VERSION ""

NS_ :

BS_:

BU_:

BO_ 2561081086 AUXIO3: 8 Vector__XXX
 SG_ AuxiliaryIO49 : 6|2@1+ (1,0) [0|3] "" Vector__XXX
 SG_ AuxiliaryIO50 : 4|2@1+ (1,0) [0|3] "" Vector__XXX
 SG_ AuxiliaryIO51 : 2|2@1+ (1,0) [0|3] "" Vector__XXX
 SG_ AuxiliaryIO52 : 0|2@1+ (1,0) [0|3] "" Vector__XXX
 SG_ AuxiliaryIO53 : 14|2@1+ (1,0) [0|3] "" Vector__XXX
 SG_ AuxiliaryIO54 : 12|2@1+ (1,0) [0|3] "" Vector__XXX
 SG_ AuxiliaryIO55 : 10|2@1+ (1,0) [0|3] "" Vector__XXX
 SG_ AuxiliaryIO56 : 8|2@1+ (1,0) [0|3] "" Vector__XXX
 SG_ AuxiliaryIO57 : 22|2@1+ (1,0) [0|3] "" Vector__XXX
 SG_ AuxiliaryIO58 : 20|2@1+ (1,0) [0|3] "" Vector__XXX
 SG_ AuxiliaryIO59 : 18|2@1+ (1,0) [0|3] "" Vector__XXX
 SG_ AuxiliaryIO60 : 16|2@1+ (1,0) [0|3] "" Vector__XXX
 SG_ AuxiliaryIO61 : 30|2@1+ (1,0) [0|3] "" Vector__XXX
 SG_ AuxiliaryIO62 : 28|2@1+ (1,0) [0|3] "" Vector__XXX
 SG_ AuxiliaryIO63 : 26|2@1+ (1,0) [0|3] "" Vector__XXX
 SG_ AuxiliaryIO64 : 24|2@1+ (1,0) [0|3] "" Vector__XXX
 SG_ AuxiliaryIO65 : 38|2@1+ (1,0) [0|3] "" Vector__XXX
 SG_ AuxiliaryIO66 : 36|2@1+ (1,0) [0|3] "" Vector__XXX
 SG_ AuxiliaryIO67 : 34|2@1+ (1,0) [0|3] "" Vector__XXX
 SG_ AuxiliaryIO68 : 32|2@1+ (1,0) [0|3] "" Vector__XXX
 SG_ AuxiliaryIO69 : 46|2@1+ (1,0) [0|3] "" Vector__XXX
 SG_ AuxiliaryIO70 : 44|2@1+ (1,0) [0|3] "" Vector__XXX
 SG_ AuxiliaryIO71 : 42|2@1+ (1,0) [0|3] "" Vector__XXX
 SG_ AuxiliaryIO72 : 40|2@1+ (1,0) [0|3] "" Vector__XXX
 SG_ AuxiliaryIO73 : 54|2@1+ (1,0) [0|3] "" Vector__XXX
 SG_ AuxiliaryIO74 : 52|2@1+ (1,0) [0|3] "" Vector__XXX
 SG_ AuxiliaryIO75 : 50|2@1+ (1,0) [0|3] "" Vector__XXX
 SG_ AuxiliaryIO76 : 48|2@1+ (1,0) [0|3] "" Vector__XXX
 SG_ AuxiliaryIO77 : 62|2@1+ (1,0) [0|3] "" Vector__XXX
 SG_ AuxiliaryIO78 : 60|2@1+ (1,0) [0|3] "" Vector__XXX
 SG_ AuxiliaryIO79 : 58|2@1+ (1,0) [0|3] "" Vector__XXX
 SG_ AuxiliaryIO80 : 56|2@1+ (1,0) [0|3] "" Vector__XXX

BO_ 2561146622 AUXIO2: 8 Vector__XXX
 SG_ AuxiliaryIO17 : 6|2@1+ (1,0) [0|3] "" Vector__XXX
 SG_ AuxiliaryIO18 : 4|2@1+ (1,0) [0|3] "" Vector__XXX
 SG_ AuxiliaryIO19 : 2|2@1+ (1,0) [0|3] "" Vector__XXX
 SG_ AuxiliaryIO20 : 0|2@1+ (1,0) [0|3] "" Vector__XXX
 SG_ AuxiliaryIO21 : 14|2@1+ (1,0) [0|3] "" Vector__XXX
 SG_ AuxiliaryIO22 : 12|2@1+ (1,0) [0|3] "" Vector__XXX
 SG_ AuxiliaryIO23 : 10|2@1+ (1,0) [0|3] "" Vector__XXX
 SG_ AuxiliaryIO24 : 8|2@1+ (1,0) [0|3] "" Vector__XXX
 SG_ AuxiliaryIO25 : 22|2@1+ (1,0) [0|3] "" Vector__XXX
 SG_ AuxiliaryIO26 : 20|2@1+ (1,0) [0|3] "" Vector__XXX
 SG_ AuxiliaryIO27 : 18|2@1+ (1,0) [0|3] "" Vector__XXX
 SG_ AuxiliaryIO28 : 16|2@1+ (1,0) [0|3] "" Vector__XXX
 SG_ AuxiliaryIO29 : 30|2@1+ (1,0) [0|3] "" Vector__XXX
 SG_ AuxiliaryIO30 : 28|2@1+ (1,0) [0|3] "" Vector__XXX
 SG_ AuxiliaryIO31 : 26|2@1+ (1,0) [0|3] "" Vector__XXX
 SG_ AuxiliaryIO32 : 24|2@1+ (1,0) [0|3] "" Vector__XXX
 SG_ AuxiliaryIO33 : 38|2@1+ (1,0) [0|3] "" Vector__XXX
 SG_ AuxiliaryIO34 : 36|2@1+ (1,0) [0|3] "" Vector__XXX
 SG_ AuxiliaryIO35 : 34|2@1+ (1,0) [0|3] "" Vector__XXX
 SG_ AuxiliaryIO36 : 32|2@1+ (1,0) [0|3] "" Vector__XXX
 SG_ AuxiliaryIO37 : 46|2@1+ (1,0) [0|3] "" Vector__XXX
 SG_ AuxiliaryIO38 : 44|2@1+ (1,0) [0|3] "" Vector__XXX
 SG_ AuxiliaryIO39 : 42|2@1+ (1,0) [0|3] "" Vector__XXX
 SG_ AuxiliaryIO40 : 40|2@1+ (1,0) [0|3] "" Vector__XXX
 SG_ AuxiliaryIO41 : 54|2@1+ (1,0) [0|3] "" Vector__XXX
 SG_ AuxiliaryIO42 : 52|2@1+ (1,0) [0|3] "" Vector__XXX
 SG_ AuxiliaryIO43 : 50|2@1+ (1,0) [0|3] "" Vector__XXX
 SG_ AuxiliaryIO44 : 48|2@1+ (1,0) [0|3] "" Vector__XXX
 SG_ AuxiliaryIO45 : 62|2@1+ (1,0) [0|3] "" Vector__XXX
 SG_ AuxiliaryIO46 : 60|2@1+ (1,0) [0|3] "" Vector__XXX
 SG_ AuxiliaryIO47 : 58|2@1+ (1,0) [0|3] "" Vector__XXX
 SG_ AuxiliaryIO48 : 56|2@1+ (1,0) [0|3] "" Vector__XXX

BO_ 2561212158 DISP1: 8 Vector__XXX
 SG_ TextDisplayIndex : 16|8@1+ (1,0) [0|200] "count" Vector__XXX
 SG_ TextDisplayInstructions : 0|4@1+ (1,0) [0|15] "" Vector__XXX

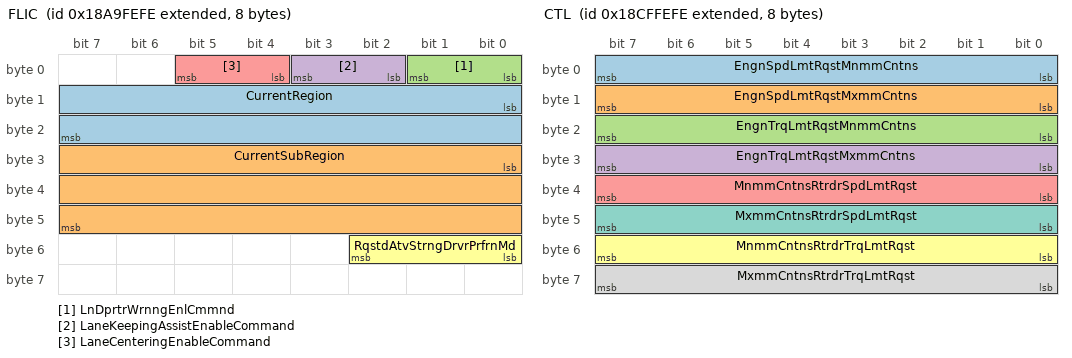
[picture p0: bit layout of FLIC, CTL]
BO_ 2561277694 FLIC: 8 Vector__XXX
 SG_ CurrentRegion : 8|16@1+ (1,0) [0|255] "" Vector__XXX
 SG_ CurrentSubRegion : 24|24@1+ (1,0) [0|255] "" Vector__XXX
 SG_ LnDprtrWrnngEnlCmmnd : 0|2@1+ (1,0) [0|3] "" Vector__XXX
 SG_ LaneKeepingAssistEnableCommand : 2|2@1+ (1,0) [0|3] "" Vector__XXX
 SG_ LaneCenteringEnableCommand : 4|2@1+ (1,0) [0|3] "" Vector__XXX
 SG_ RqstdAtvStrngDrvrPrfrnMd : 48|3@1+ (1,0) [0|7] "" Vector__XXX

BO_ 2561605374 TPRS: 8 Vector__XXX
 SG_ ReferenceTirePressureSetting : 8|8@1+ (8,0) [0|2000] "kPa" Vector__XXX
 SG_ TireLocation : 0|8@1+ (1,0) [0|250] "" Vector__XXX

BO_ 2563768062 CTL: 8 Vector__XXX
 SG_ EngnSpdLmtRqstMnmmCntns : 0|8@1+ (32,0) [0|8000] "rpm" Vector__XXX
 SG_ EngnSpdLmtRqstMxmmCntns : 8|8@1+ (32,0) [0|8000] "rpm" Vector__XXX
 SG_ EngnTrqLmtRqstMnmmCntns : 16|8@1+ (1,-125) [0|125] "%" Vector__XXX
 SG_ EngnTrqLmtRqstMxmmCntns : 24|8@1+ (1,-125) [0|125] "%" Vector__XXX
 SG_ MnmmCntnsRtrdrSpdLmtRqst : 32|8@1+ (32,0) [0|8000] "rpm" Vector__XXX
 SG_ MnmmCntnsRtrdrTrqLmtRqst : 48|8@1+ (1,-125) [-125|0] "%" Vector__XXX
 SG_ MxmmCntnsRtrdrSpdLmtRqst : 40|8@1+ (32,0) [0|8000] "rpm" Vector__XXX
 SG_ MxmmCntnsRtrdrTrqLmtRqst : 56|8@1+ (1,-125) [-125|0] "%" Vector__XXX

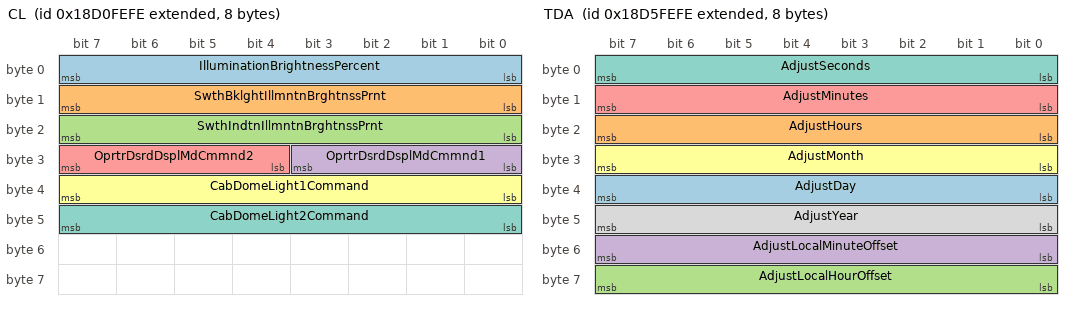
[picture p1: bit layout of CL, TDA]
BO_ 2563833598 CL: 8 Vector__XXX
 SG_ IlluminationBrightnessPercent : 0|8@1+ (0.4,0) [0|100] "%" Vector__XXX
 SG_ SwthBklghtIllmntnBrghtnssPrnt : 8|8@1+ (0.4,0) [0|100] "%" Vector__XXX
 SG_ SwthIndtnIllmntnBrghtnssPrnt : 16|8@1+ (0.4,0) [0|100] "%" Vector__XXX
 SG_ OprtrDsrdDsplMdCmmnd1 : 24|4@1+ (1,0) [0|15] "" Vector__XXX
 SG_ OprtrDsrdDsplMdCmmnd2 : 28|4@1+ (1,0) [0|15] "" Vector__XXX
 SG_ CabDomeLight1Command : 32|8@1+ (0.4,0) [0|100] "%" Vector__XXX
 SG_ CabDomeLight2Command : 40|8@1+ (0.4,0) [0|100] "%" Vector__XXX

BO_ 2564161278 TDA: 8 Vector__XXX
 SG_ AdjustDay : 32|8@1+ (0.25,0) [0.25|31.75] "days" Vector__XXX
 SG_ AdjustHours : 16|8@1+ (1,0) [0|23] "h" Vector__XXX
 SG_ AdjustLocalHourOffset : 56|8@1+ (1,-125) [-24|23] "h" Vector__XXX
 SG_ AdjustLocalMinuteOffset : 48|8@1+ (1,-125) [-59|59] "min" Vector__XXX
 SG_ AdjustMinutes : 8|8@1+ (1,0) [0|59] "min" Vector__XXX
 SG_ AdjustMonth : 24|8@1+ (1,0) [1|12] "month" Vector__XXX
 SG_ AdjustSeconds : 0|8@1+ (0.25,0) [0|59.75] "s" Vector__XXX
 SG_ AdjustYear : 40|8@1+ (1,1985) [1985|2235] "year" Vector__XXX

BO_ 2564882174 CM1: 8 Vector__XXX
 SG_ AftrtrtmntRgnrtnFrSwth : 42|2@1+ (1,0) [0|3] "" Vector__XXX
 SG_ AftrtrtmntRgnrtnInhtSwth : 40|2@1+ (1,0) [0|3] "" Vector__XXX
 SG_ AtmtGrShftngEnlSwth : 44|2@1+ (1,0) [0|3] "" Vector__XXX
 SG_ AuxiliaryHeaterModeRequest : 48|4@1+ (1,0) [0|15] "" Vector__XXX
 SG_ AxlrHtrClntPmpRqst : 24|2@1+ (1,0) [0|3] "" Vector__XXX
 SG_ BatteryMainSwitchHoldRequest : 26|2@1+ (1,0) [0|3] "" Vector__XXX
 SG_ CabInteriorTemperatureCommand : 8|16@1+ (0.03125,-273) [-273|1734.96875] "degC" Vector__XXX
 SG_ EngineFan1RequestedPercentSpeed : 0|8@1+ (0.4,0) [0|100] "%" Vector__XXX
 SG_ EngnAtmtStrtEnlSwth : 46|2@1+ (1,0) [0|3] "" Vector__XXX
 SG_ OperatorSeatDirectionSwitch : 28|2@1+ (1,0) [0|3] "" Vector__XXX
 SG_ ParkBrakeCommand : 32|2@1+ (1,0) [0|3] "" Vector__XXX
 SG_ RequestCabZoneHeating : 54|2@1+ (1,0) [0|3] "" Vector__XXX
 SG_ RequestEngineZoneHeating : 52|2@1+ (1,0) [0|3] "" Vector__XXX
 SG_ SeatBeltSwitch : 30|2@1+ (1,0) [0|3] "" Vector__XXX
 SG_ SltdMxmmVhlSpdLmt : 56|8@1+ (1,0) [0|250] "count" Vector__XXX
 SG_ VhlLmtngSpdGvrnrDrmntSwth : 34|2@1+ (1,0) [0|3] "" Vector__XXX
 SG_ VhlLmtngSpdGvrnrEnlSwth : 38|2@1+ (1,0) [0|3] "" Vector__XXX
 SG_ VhlLmtngSpdGvrnrInrmntSwth : 36|2@1+ (1,0) [0|3] "" Vector__XXX

BO_ 2565865982 EBC1: 8 Vector__XXX
 SG_ AbsFullyOperational : 40|2@1+ (1,0) [0|3] "" Vector__XXX
 SG_ AbsOffRoadSwitch : 16|2@1+ (1,0) [0|3] "" Vector__XXX
 SG_ AcceleratorInterlockSwitch : 24|2@1+ (1,0) [0|3] "" Vector__XXX
 SG_ AntiLockBrakingAbsActive : 4|2@1+ (1,0) [0|3] "" Vector__XXX
 SG_ AsrBrakeControlActive : 2|2@1+ (1,0) [0|3] "" Vector__XXX
 SG_ AsrEngineControlActive : 0|2@1+ (1,0) [0|3] "" Vector__XXX
 SG_ AsrHillHolderSwitch : 20|2@1+ (1,0) [0|3] "" Vector__XXX
 SG_ AsrOffRoadSwitch : 18|2@1+ (1,0) [0|3] "" Vector__XXX
 SG_ AtcAsrInformationSignal : 46|2@1+ (1,0) [0|3] "" Vector__XXX
 SG_ BrakePedalPosition : 8|8@1+ (0.4,0) [0|100] "%" Vector__XXX
 SG_ EbsBrakeSwitch : 6|2@1+ (1,0) [0|3] "" Vector__XXX
 SG_ EbsRedWarningSignal : 42|2@1+ (1,0) [0|3] "" Vector__XXX
 SG_ EngineAuxiliaryShutdownSwitch : 28|2@1+ (1,0) [0|3] "" Vector__XXX
 SG_ EngineDerateSwitch : 26|2@1+ (1,0) [0|3] "" Vector__XXX
 SG_ EngineRetarderSelection : 32|8@1+ (0.4,0) [0|100] "%" Vector__XXX
 SG_ HaltBrakeSwitch : 58|2@1+ (1,0) [0|3] "" Vector__XXX
 SG_ RailroadModeSwitch : 56|2@1+ (1,0) [0|3] "" Vector__XXX
 SG_ RemoteAcceleratorEnableSwitch : 30|2@1+ (1,0) [0|3] "" Vector__XXX
 SG_ TractionControlOverrideSwitch : 22|2@1+ (1,0) [0|3] "" Vector__XXX
 SG_ TrailerAbsStatus : 60|2@1+ (1,0) [0|3] "" Vector__XXX
 SG_ AsEsAmrWrnngSgnlPwrdVhl : 44|2@1+ (1,0) [0|3] "" Vector__XXX
 SG_ SrAddrssOfCntrllngDvFrBrkCntrl : 48|8@1+ (1,0) [0|253] "sourceadr" Vector__XXX
 SG_ TrtrMntdTrlrAsWrnngSgnl : 62|2@1+ (1,0) [0|3] "" Vector__XXX

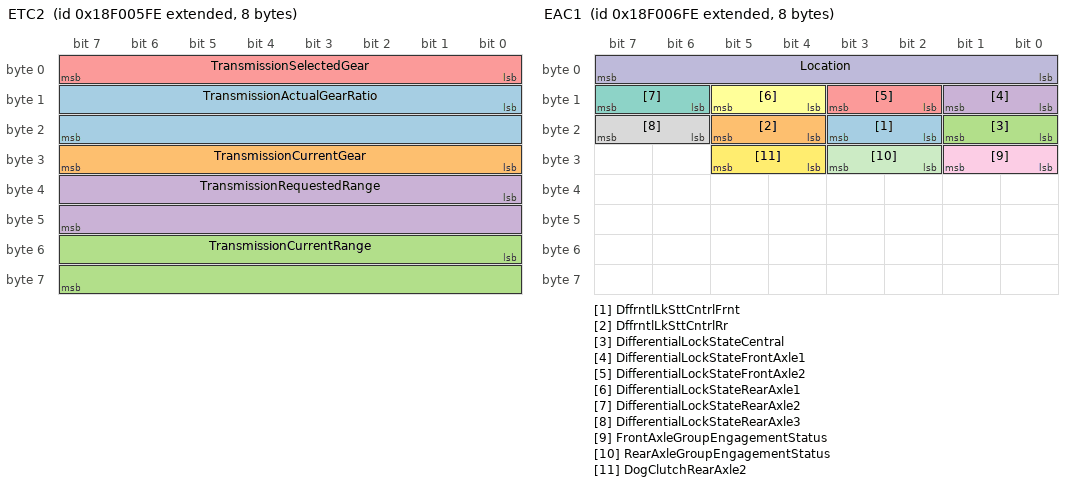
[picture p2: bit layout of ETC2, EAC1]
BO_ 2565867006 ETC2: 8 Vector__XXX
 SG_ TransmissionActualGearRatio : 8|16@1+ (0.001,0) [0|64.255] "" Vector__XXX
 SG_ TransmissionCurrentGear : 24|8@1+ (1,-125) [-125|125] "gear value" Vector__XXX
 SG_ TransmissionCurrentRange : 48|16@1+ (1,0) [0|255] "" Vector__XXX
 SG_ TransmissionRequestedRange : 32|16@1+ (1,0) [0|255] "" Vector__XXX
 SG_ TransmissionSelectedGear : 0|8@1+ (1,-125) [-125|125] "gear value" Vector__XXX

BO_ 2565867262 EAC1: 8 Vector__XXX
 SG_ DffrntlLkSttCntrlFrnt : 18|2@1+ (1,0) [0|3] "" Vector__XXX
 SG_ DffrntlLkSttCntrlRr : 20|2@1+ (1,0) [0|3] "" Vector__XXX
 SG_ DifferentialLockStateCentral : 16|2@1+ (1,0) [0|3] "" Vector__XXX
 SG_ DifferentialLockStateFrontAxle1 : 8|2@1+ (1,0) [0|3] "" Vector__XXX
 SG_ DifferentialLockStateFrontAxle2 : 10|2@1+ (1,0) [0|3] "" Vector__XXX
 SG_ DifferentialLockStateRearAxle1 : 12|2@1+ (1,0) [0|3] "" Vector__XXX
 SG_ DifferentialLockStateRearAxle2 : 14|2@1+ (1,0) [0|3] "" Vector__XXX
 SG_ DifferentialLockStateRearAxle3 : 22|2@1+ (1,0) [0|3] "" Vector__XXX
 SG_ FrontAxleGroupEngagementStatus : 24|2@1+ (1,0) [0|3] "" Vector__XXX
 SG_ Location : 0|8@1+ (1,0) [0|250] "" Vector__XXX
 SG_ RearAxleGroupEngagementStatus : 26|2@1+ (1,0) [0|3] "" Vector__XXX
 SG_ DogClutchRearAxle2 : 28|2@1+ (1,0) [0|3] "" Vector__XXX

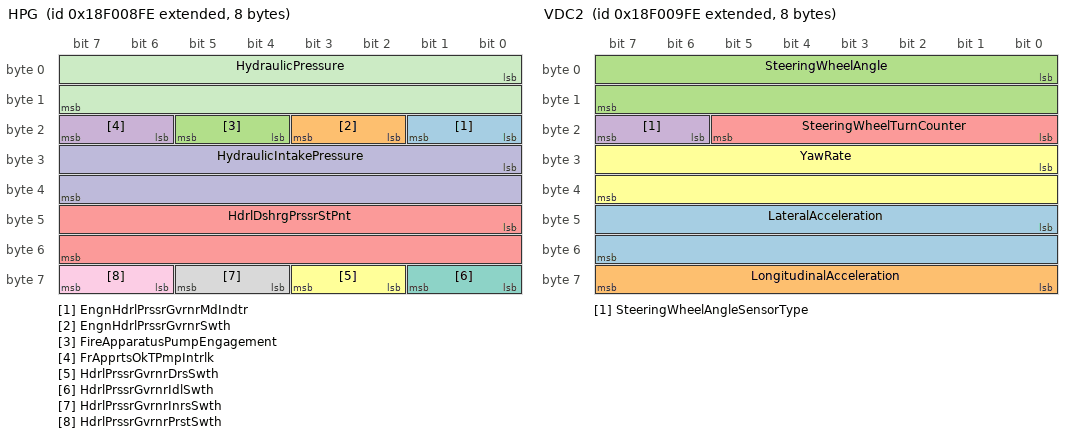
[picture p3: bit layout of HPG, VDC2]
BO_ 2565867774 HPG: 8 Vector__XXX
 SG_ EngnHdrlPrssrGvrnrMdIndtr : 16|2@1+ (1,0) [0|3] "" Vector__XXX
 SG_ EngnHdrlPrssrGvrnrSwth : 18|2@1+ (1,0) [0|3] "" Vector__XXX
 SG_ FireApparatusPumpEngagement : 20|2@1+ (1,0) [0|3] "" Vector__XXX
 SG_ FrApprtsOkTPmpIntrlk : 22|2@1+ (1,0) [0|3] "" Vector__XXX
 SG_ HdrlDshrgPrssrStPnt : 40|16@1+ (2,0) [0|128510] "kPa" Vector__XXX
 SG_ HdrlPrssrGvrnrDrsSwth : 58|2@1+ (1,0) [0|3] "" Vector__XXX
 SG_ HdrlPrssrGvrnrIdlSwth : 56|2@1+ (1,0) [0|3] "" Vector__XXX
 SG_ HdrlPrssrGvrnrInrsSwth : 60|2@1+ (1,0) [0|3] "" Vector__XXX
 SG_ HdrlPrssrGvrnrPrstSwth : 62|2@1+ (1,0) [0|3] "" Vector__XXX
 SG_ HydraulicIntakePressure : 24|16@1+ (0.0001220703125,-1) [-1|6.8436279296875] "MPa" Vector__XXX
 SG_ HydraulicPressure : 0|16@1+ (2,0) [0|128510] "kPa" Vector__XXX

BO_ 2565868030 VDC2: 8 Vector__XXX
 SG_ LateralAcceleration : 40|16@1+ (0.00048828125,-15.687) [-15.687|15.68751171875] "m/(s*s)" Vector__XXX
 SG_ LongitudinalAcceleration : 56|8@1+ (0.1,-12.5) [-12.5|12.5] "m/(s*s)" Vector__XXX
 SG_ SteeringWheelAngle : 0|16@1+ (0.0009765625,-31.374) [-31.374|31.3750234375] "rad" Vector__XXX
 SG_ SteeringWheelAngleSensorType : 22|2@1+ (1,0) [0|3] "" Vector__XXX
 SG_ SteeringWheelTurnCounter : 16|6@1+ (1,-32) [-10|10] "turn" Vector__XXX
 SG_ YawRate : 24|16@1+ (0.0001220703125,-3.92) [-3.92|3.9236279296875] "rad/s" Vector__XXX

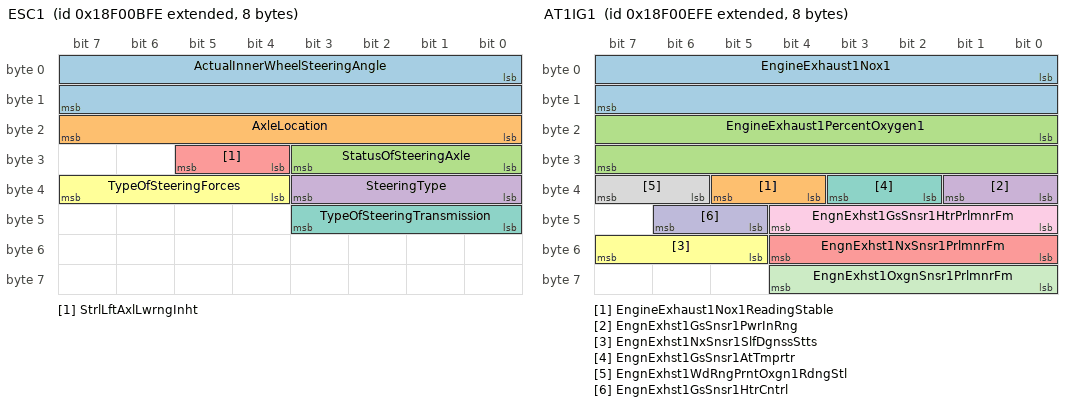
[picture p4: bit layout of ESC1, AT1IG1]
BO_ 2565868542 ESC1: 8 Vector__XXX
 SG_ ActualInnerWheelSteeringAngle : 0|16@1+ (0.00390625,-125) [-125|125.99609375] "deg" Vector__XXX
 SG_ AxleLocation : 16|8@1+ (1,0) [0|250] "" Vector__XXX
 SG_ StatusOfSteeringAxle : 24|4@1+ (1,0) [0|15] "" Vector__XXX
 SG_ SteeringType : 32|4@1+ (1,0) [0|15] "" Vector__XXX
 SG_ StrlLftAxlLwrngInht : 28|2@1+ (1,0) [0|3] "" Vector__XXX
 SG_ TypeOfSteeringForces : 36|4@1+ (1,0) [0|15] "" Vector__XXX
 SG_ TypeOfSteeringTransmission : 40|4@1+ (1,0) [0|15] "" Vector__XXX

BO_ 2565869310 AT1IG1: 8 Vector__XXX
 SG_ EngineExhaust1Nox1 : 0|16@1+ (0.05,-200) [-200|3012.75] "ppm" Vector__XXX
 SG_ EngineExhaust1Nox1ReadingStable : 36|2@1+ (1,0) [0|3] "" Vector__XXX
 SG_ EngineExhaust1PercentOxygen1 : 16|16@1+ (0.000514,-12) [-12|21.02707] "%" Vector__XXX
 SG_ EngnExhst1GsSnsr1PwrInRng : 32|2@1+ (1,0) [0|3] "" Vector__XXX
 SG_ EngnExhst1NxSnsr1PrlmnrFm : 48|5@1+ (1,0) [0|31] "" Vector__XXX
 SG_ EngnExhst1NxSnsr1SlfDgnssStts : 53|3@1+ (1,0) [0|7] "" Vector__XXX
 SG_ EngnExhst1GsSnsr1AtTmprtr : 34|2@1+ (1,0) [0|3] "" Vector__XXX
 SG_ EngnExhst1WdRngPrntOxgn1RdngStl : 38|2@1+ (1,0) [0|3] "" Vector__XXX
 SG_ EngnExhst1GsSnsr1HtrPrlmnrFm : 40|5@1+ (1,0) [0|31] "" Vector__XXX
 SG_ EngnExhst1GsSnsr1HtrCntrl : 45|2@1+ (1,0) [0|3] "" Vector__XXX
 SG_ EngnExhst1OxgnSnsr1PrlmnrFm : 56|5@1+ (1,0) [0|31] "" Vector__XXX

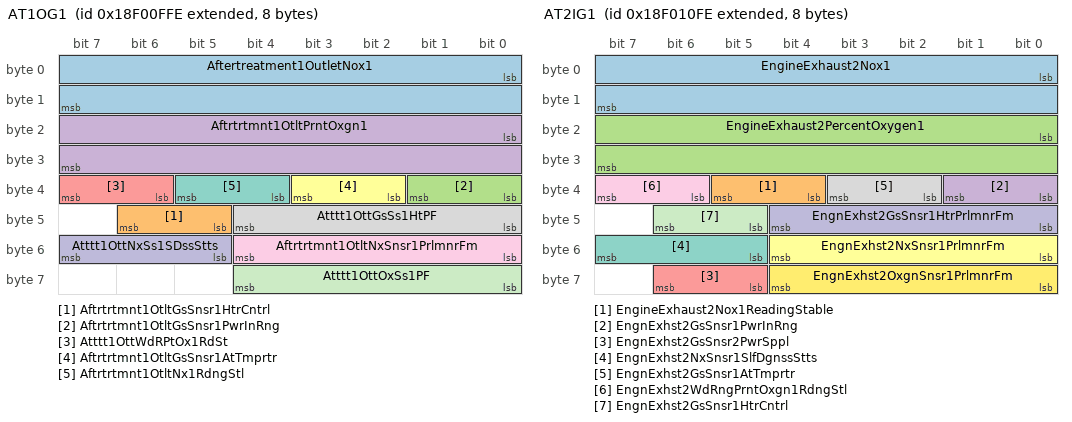
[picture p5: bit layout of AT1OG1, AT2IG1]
BO_ 2565869566 AT1OG1: 8 Vector__XXX
 SG_ Aftertreatment1OutletNox1 : 0|16@1+ (0.05,-200) [-200|3012.75] "ppm" Vector__XXX
 SG_ Aftrtrtmnt1OtltGsSnsr1HtrCntrl : 45|2@1+ (1,0) [0|3] "" Vector__XXX
 SG_ Aftrtrtmnt1OtltGsSnsr1PwrInRng : 32|2@1+ (1,0) [0|3] "" Vector__XXX
 SG_ Aftrtrtmnt1OtltPrntOxgn1 : 16|16@1+ (0.000514,-12) [-12|21.02707] "%" Vector__XXX
 SG_ Atttt1OttWdRPtOx1RdSt : 38|2@1+ (1,0) [0|3] "" Vector__XXX
 SG_ Aftrtrtmnt1OtltGsSnsr1AtTmprtr : 34|2@1+ (1,0) [0|3] "" Vector__XXX
 SG_ Aftrtrtmnt1OtltNx1RdngStl : 36|2@1+ (1,0) [0|3] "" Vector__XXX
 SG_ Atttt1OttGsSs1HtPF : 40|5@1+ (1,0) [0|31] "" Vector__XXX
 SG_ Aftrtrtmnt1OtltNxSnsr1PrlmnrFm : 48|5@1+ (1,0) [0|31] "" Vector__XXX
 SG_ Atttt1OttNxSs1SDssStts : 53|3@1+ (1,0) [0|7] "" Vector__XXX
 SG_ Atttt1OttOxSs1PF : 56|5@1+ (1,0) [0|31] "" Vector__XXX

BO_ 2565869822 AT2IG1: 8 Vector__XXX
 SG_ EngineExhaust2Nox1 : 0|16@1+ (0.05,-200) [-200|3012.75] "ppm" Vector__XXX
 SG_ EngineExhaust2Nox1ReadingStable : 36|2@1+ (1,0) [0|3] "" Vector__XXX
 SG_ EngineExhaust2PercentOxygen1 : 16|16@1+ (0.000514,-12) [-12|21.02707] "%" Vector__XXX
 SG_ EngnExhst2GsSnsr1PwrInRng : 32|2@1+ (1,0) [0|3] "" Vector__XXX
 SG_ EngnExhst2GsSnsr2PwrSppl : 61|2@1+ (1,0) [0|3] "" Vector__XXX
 SG_ EngnExhst2NxSnsr1PrlmnrFm : 48|5@1+ (1,0) [0|31] "" Vector__XXX
 SG_ EngnExhst2NxSnsr1SlfDgnssStts : 53|3@1+ (1,0) [0|7] "" Vector__XXX
 SG_ EngnExhst2GsSnsr1AtTmprtr : 34|2@1+ (1,0) [0|3] "" Vector__XXX
 SG_ EngnExhst2WdRngPrntOxgn1RdngStl : 38|2@1+ (1,0) [0|3] "" Vector__XXX
 SG_ EngnExhst2GsSnsr1HtrPrlmnrFm : 40|5@1+ (1,0) [0|31] "" Vector__XXX
 SG_ EngnExhst2GsSnsr1HtrCntrl : 45|2@1+ (1,0) [0|3] "" Vector__XXX
 SG_ EngnExhst2OxgnSnsr1PrlmnrFm : 56|5@1+ (1,0) [0|31] "" Vector__XXX

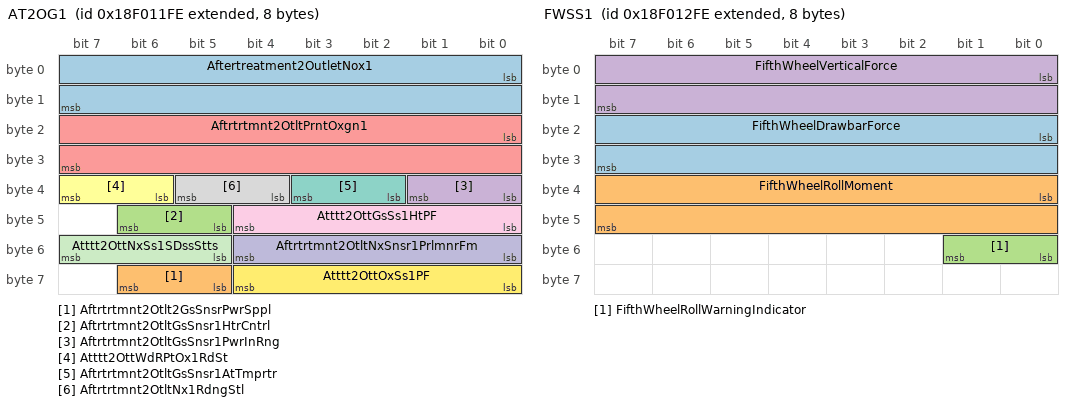
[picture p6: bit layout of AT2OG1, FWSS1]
BO_ 2565870078 AT2OG1: 8 Vector__XXX
 SG_ Aftertreatment2OutletNox1 : 0|16@1+ (0.05,-200) [-200|3012.75] "ppm" Vector__XXX
 SG_ Aftrtrtmnt2Otlt2GsSnsrPwrSppl : 61|2@1+ (1,0) [0|3] "" Vector__XXX
 SG_ Aftrtrtmnt2OtltGsSnsr1HtrCntrl : 45|2@1+ (1,0) [0|3] "" Vector__XXX
 SG_ Aftrtrtmnt2OtltGsSnsr1PwrInRng : 32|2@1+ (1,0) [0|3] "" Vector__XXX
 SG_ Aftrtrtmnt2OtltPrntOxgn1 : 16|16@1+ (0.000514,-12) [-12|21.02707] "%" Vector__XXX
 SG_ Atttt2OttWdRPtOx1RdSt : 38|2@1+ (1,0) [0|3] "" Vector__XXX
 SG_ Aftrtrtmnt2OtltGsSnsr1AtTmprtr : 34|2@1+ (1,0) [0|3] "" Vector__XXX
 SG_ Aftrtrtmnt2OtltNx1RdngStl : 36|2@1+ (1,0) [0|3] "" Vector__XXX
 SG_ Atttt2OttGsSs1HtPF : 40|5@1+ (1,0) [0|31] "" Vector__XXX
 SG_ Aftrtrtmnt2OtltNxSnsr1PrlmnrFm : 48|5@1+ (1,0) [0|31] "" Vector__XXX
 SG_ Atttt2OttNxSs1SDssStts : 53|3@1+ (1,0) [0|7] "" Vector__XXX
 SG_ Atttt2OttOxSs1PF : 56|5@1+ (1,0) [0|31] "" Vector__XXX

BO_ 2565870334 FWSS1: 8 Vector__XXX
 SG_ FifthWheelDrawbarForce : 16|16@1+ (10,-320000) [-320000|322550] "N" Vector__XXX
 SG_ FifthWheelRollMoment : 32|16@1+ (10,-320000) [-320000|322550] "N" Vector__XXX
 SG_ FifthWheelRollWarningIndicator : 48|2@1+ (1,0) [0|3] "" Vector__XXX
 SG_ FifthWheelVerticalForce : 0|16@1+ (5,0) [0|321275] "N" Vector__XXX

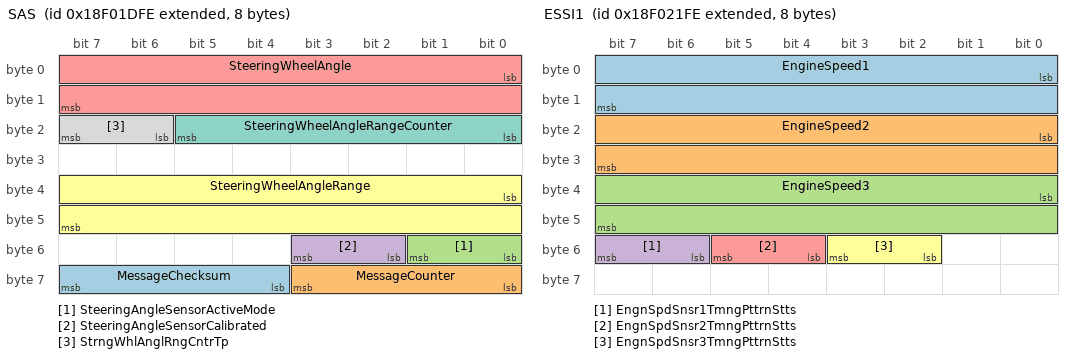
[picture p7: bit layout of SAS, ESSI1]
BO_ 2565873150 SAS: 8 Vector__XXX
 SG_ MessageChecksum : 60|4@1+ (1,0) [0|15] "count" Vector__XXX
 SG_ MessageCounter : 56|4@1+ (1,0) [0|15] "count" Vector__XXX
 SG_ SteeringAngleSensorActiveMode : 48|2@1+ (1,0) [0|3] "" Vector__XXX
 SG_ SteeringAngleSensorCalibrated : 50|2@1+ (1,0) [0|3] "" Vector__XXX
 SG_ SteeringWheelAngle : 0|16@1+ (0.0009765625,-31.374) [-31.374|31.3750234375] "rad" Vector__XXX
 SG_ SteeringWheelAngleRange : 32|16@1+ (0.0009765625,-31.374) [0|31.374] "rad" Vector__XXX
 SG_ SteeringWheelAngleRangeCounter : 16|6@1+ (1,-32) [-32|29] "range" Vector__XXX
 SG_ StrngWhlAnglRngCntrTp : 22|2@1+ (1,0) [0|3] "" Vector__XXX

BO_ 2565874174 ESSI1: 8 Vector__XXX
 SG_ EngineSpeed1 : 0|16@1+ (0.5,0) [0|32127.5] "rpm" Vector__XXX
 SG_ EngineSpeed2 : 16|16@1+ (0.5,0) [0|32127.5] "rpm" Vector__XXX
 SG_ EngineSpeed3 : 32|16@1+ (0.5,0) [0|32127.5] "rpm" Vector__XXX
 SG_ EngnSpdSnsr1TmngPttrnStts : 54|2@1+ (1,0) [0|3] "" Vector__XXX
 SG_ EngnSpdSnsr2TmngPttrnStts : 52|2@1+ (1,0) [0|3] "" Vector__XXX
 SG_ EngnSpdSnsr3TmngPttrnStts : 50|2@1+ (1,0) [0|3] "" Vector__XXX

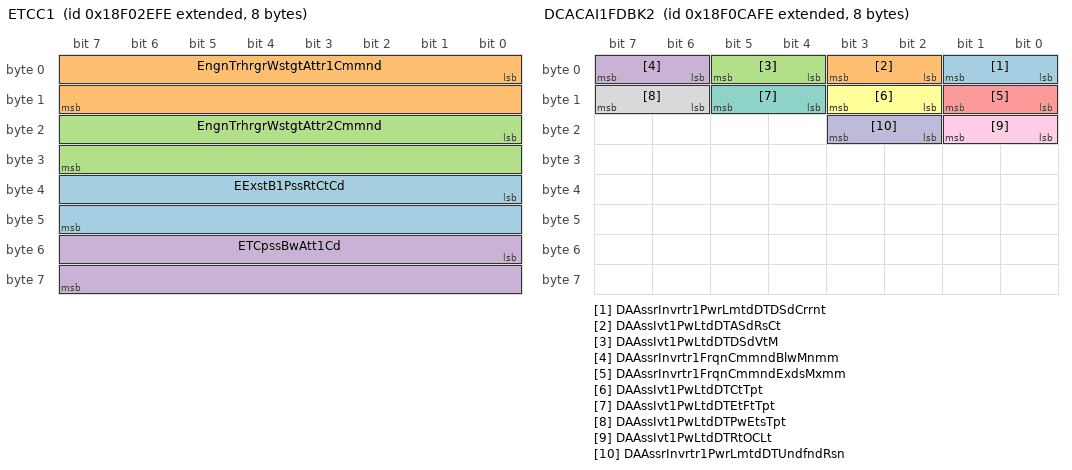
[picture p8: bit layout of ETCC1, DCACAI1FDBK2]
BO_ 2565877502 ETCC1: 8 Vector__XXX
 SG_ EExstB1PssRtCtCd : 32|16@1+ (0.0025,0) [0|100] "%" Vector__XXX
 SG_ EngnTrhrgrWstgtAttr1Cmmnd : 0|16@1+ (0.0025,0) [0|160.6375] "%" Vector__XXX
 SG_ EngnTrhrgrWstgtAttr2Cmmnd : 16|16@1+ (0.0025,0) [0|160.6375] "%" Vector__XXX
 SG_ ETCpssBwAtt1Cd : 48|16@1+ (0.0025,0) [0|100] "%" Vector__XXX

BO_ 2565917438 DCACAI1FDBK2: 8 Vector__XXX
 SG_ DAAssrInvrtr1PwrLmtdDTDSdCrrnt : 0|2@1+ (1,0) [0|3] "" Vector__XXX
 SG_ DAAssIvt1PwLtdDTASdRsCt : 2|2@1+ (1,0) [0|3] "" Vector__XXX
 SG_ DAAssIvt1PwLtdDTDSdVtM : 4|2@1+ (1,0) [0|3] "" Vector__XXX
 SG_ DAAssrInvrtr1FrqnCmmndBlwMnmm : 6|2@1+ (1,0) [0|3] "" Vector__XXX
 SG_ DAAssrInvrtr1FrqnCmmndExdsMxmm : 8|2@1+ (1,0) [0|3] "" Vector__XXX
 SG_ DAAssIvt1PwLtdDTCtTpt : 10|2@1+ (1,0) [0|3] "" Vector__XXX
 SG_ DAAssIvt1PwLtdDTEtFtTpt : 12|2@1+ (1,0) [0|3] "" Vector__XXX
 SG_ DAAssIvt1PwLtdDTPwEtsTpt : 14|2@1+ (1,0) [0|3] "" Vector__XXX
 SG_ DAAssIvt1PwLtdDTRtOCLt : 16|2@1+ (1,0) [0|3] "" Vector__XXX
 SG_ DAAssrInvrtr1PwrLmtdDTUndfndRsn : 18|2@1+ (1,0) [0|3] "" Vector__XXX

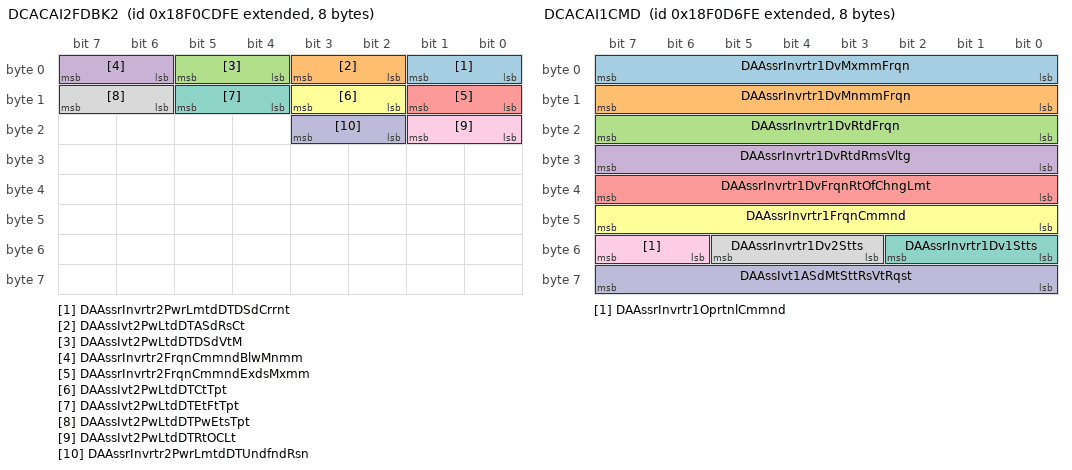
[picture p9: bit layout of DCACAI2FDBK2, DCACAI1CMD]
BO_ 2565918206 DCACAI2FDBK2: 8 Vector__XXX
 SG_ DAAssrInvrtr2PwrLmtdDTDSdCrrnt : 0|2@1+ (1,0) [0|3] "" Vector__XXX
 SG_ DAAssIvt2PwLtdDTASdRsCt : 2|2@1+ (1,0) [0|3] "" Vector__XXX
 SG_ DAAssIvt2PwLtdDTDSdVtM : 4|2@1+ (1,0) [0|3] "" Vector__XXX
 SG_ DAAssrInvrtr2FrqnCmmndBlwMnmm : 6|2@1+ (1,0) [0|3] "" Vector__XXX
 SG_ DAAssrInvrtr2FrqnCmmndExdsMxmm : 8|2@1+ (1,0) [0|3] "" Vector__XXX
 SG_ DAAssIvt2PwLtdDTCtTpt : 10|2@1+ (1,0) [0|3] "" Vector__XXX
 SG_ DAAssIvt2PwLtdDTEtFtTpt : 12|2@1+ (1,0) [0|3] "" Vector__XXX
 SG_ DAAssIvt2PwLtdDTPwEtsTpt : 14|2@1+ (1,0) [0|3] "" Vector__XXX
 SG_ DAAssIvt2PwLtdDTRtOCLt : 16|2@1+ (1,0) [0|3] "" Vector__XXX
 SG_ DAAssrInvrtr2PwrLmtdDTUndfndRsn : 18|2@1+ (1,0) [0|3] "" Vector__XXX

BO_ 2565920510 DCACAI1CMD: 8 Vector__XXX
 SG_ DAAssrInvrtr1DvMxmmFrqn : 0|8@1+ (1,0) [0|250] "Hz" Vector__XXX
 SG_ DAAssrInvrtr1DvMnmmFrqn : 8|8@1+ (1,0) [0|250] "Hz" Vector__XXX
 SG_ DAAssrInvrtr1DvRtdFrqn : 16|8@1+ (1,0) [0|250] "Hz" Vector__XXX
 SG_ DAAssrInvrtr1DvRtdRmsVltg : 24|8@1+ (2,0) [0|500] "V" Vector__XXX
 SG_ DAAssrInvrtr1DvFrqnRtOfChngLmt : 32|8@1+ (2,0) [0|500] "Hz/s" Vector__XXX
 SG_ DAAssrInvrtr1FrqnCmmnd : 40|8@1+ (1,0) [0|250] "Hz" Vector__XXX
 SG_ DAAssrInvrtr1Dv1Stts : 48|3@1+ (1,0) [0|7] "" Vector__XXX
 SG_ DAAssrInvrtr1Dv2Stts : 51|3@1+ (1,0) [0|7] "" Vector__XXX
 SG_ DAAssrInvrtr1OprtnlCmmnd : 54|2@1+ (1,0) [0|3] "" Vector__XXX
 SG_ DAAssIvt1ASdMtSttRsVtRqst : 56|8@1+ (2,0) [0|500] "V" Vector__XXX

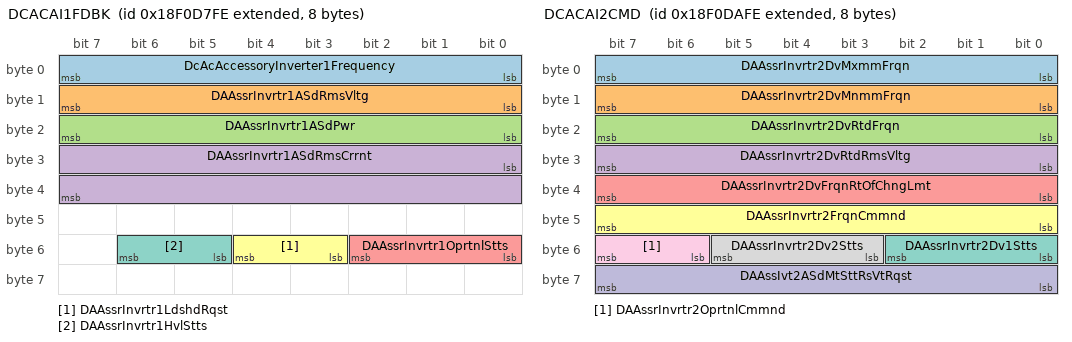
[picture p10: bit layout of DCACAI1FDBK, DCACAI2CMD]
BO_ 2565920766 DCACAI1FDBK: 8 Vector__XXX
 SG_ DcAcAccessoryInverter1Frequency : 0|8@1+ (1,0) [0|250] "Hz" Vector__XXX
 SG_ DAAssrInvrtr1ASdRmsVltg : 8|8@1+ (2,0) [0|500] "V" Vector__XXX
 SG_ DAAssrInvrtr1ASdPwr : 16|8@1+ (0.1,0) [0|25] "kW" Vector__XXX
 SG_ DAAssrInvrtr1ASdRmsCrrnt : 24|16@1+ (0.03125,0) [0|2007.96875] "A" Vector__XXX
 SG_ DAAssrInvrtr1OprtnlStts : 48|3@1+ (1,0) [0|7] "" Vector__XXX
 SG_ DAAssrInvrtr1LdshdRqst : 51|2@1+ (1,0) [0|3] "" Vector__XXX
 SG_ DAAssrInvrtr1HvlStts : 53|2@1+ (1,0) [0|3] "" Vector__XXX

BO_ 2565921534 DCACAI2CMD: 8 Vector__XXX
 SG_ DAAssrInvrtr2DvMxmmFrqn : 0|8@1+ (1,0) [0|250] "Hz" Vector__XXX
 SG_ DAAssrInvrtr2DvMnmmFrqn : 8|8@1+ (1,0) [0|250] "Hz" Vector__XXX
 SG_ DAAssrInvrtr2DvRtdFrqn : 16|8@1+ (1,0) [0|250] "Hz" Vector__XXX
 SG_ DAAssrInvrtr2DvRtdRmsVltg : 24|8@1+ (2,0) [0|500] "V" Vector__XXX
 SG_ DAAssrInvrtr2DvFrqnRtOfChngLmt : 32|8@1+ (2,0) [0|500] "Hz/s" Vector__XXX
 SG_ DAAssrInvrtr2FrqnCmmnd : 40|8@1+ (1,0) [0|250] "Hz" Vector__XXX
 SG_ DAAssrInvrtr2Dv1Stts : 48|3@1+ (1,0) [0|7] "" Vector__XXX
 SG_ DAAssrInvrtr2Dv2Stts : 51|3@1+ (1,0) [0|7] "" Vector__XXX
 SG_ DAAssrInvrtr2OprtnlCmmnd : 54|2@1+ (1,0) [0|3] "" Vector__XXX
 SG_ DAAssIvt2ASdMtSttRsVtRqst : 56|8@1+ (2,0) [0|500] "V" Vector__XXX

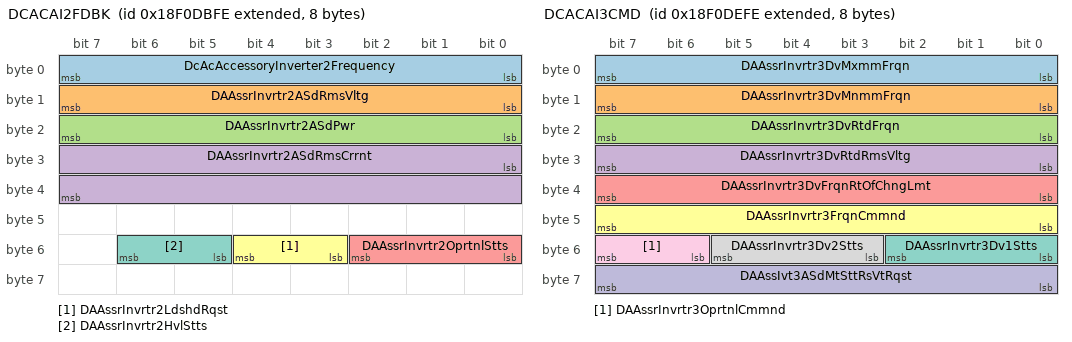
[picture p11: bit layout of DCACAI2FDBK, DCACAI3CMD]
BO_ 2565921790 DCACAI2FDBK: 8 Vector__XXX
 SG_ DcAcAccessoryInverter2Frequency : 0|8@1+ (1,0) [0|250] "Hz" Vector__XXX
 SG_ DAAssrInvrtr2ASdRmsVltg : 8|8@1+ (2,0) [0|500] "V" Vector__XXX
 SG_ DAAssrInvrtr2ASdPwr : 16|8@1+ (0.1,0) [0|25] "kW" Vector__XXX
 SG_ DAAssrInvrtr2ASdRmsCrrnt : 24|16@1+ (0.03125,0) [0|2007.96875] "A" Vector__XXX
 SG_ DAAssrInvrtr2OprtnlStts : 48|3@1+ (1,0) [0|7] "" Vector__XXX
 SG_ DAAssrInvrtr2LdshdRqst : 51|2@1+ (1,0) [0|3] "" Vector__XXX
 SG_ DAAssrInvrtr2HvlStts : 53|2@1+ (1,0) [0|3] "" Vector__XXX

BO_ 2565922558 DCACAI3CMD: 8 Vector__XXX
 SG_ DAAssrInvrtr3DvMxmmFrqn : 0|8@1+ (1,0) [0|250] "Hz" Vector__XXX
 SG_ DAAssrInvrtr3DvMnmmFrqn : 8|8@1+ (1,0) [0|250] "Hz" Vector__XXX
 SG_ DAAssrInvrtr3DvRtdFrqn : 16|8@1+ (1,0) [0|250] "Hz" Vector__XXX
 SG_ DAAssrInvrtr3DvRtdRmsVltg : 24|8@1+ (2,0) [0|500] "V" Vector__XXX
 SG_ DAAssrInvrtr3DvFrqnRtOfChngLmt : 32|8@1+ (2,0) [0|500] "Hz/s" Vector__XXX
 SG_ DAAssrInvrtr3FrqnCmmnd : 40|8@1+ (1,0) [0|250] "Hz" Vector__XXX
 SG_ DAAssrInvrtr3Dv1Stts : 48|3@1+ (1,0) [0|7] "" Vector__XXX
 SG_ DAAssrInvrtr3Dv2Stts : 51|3@1+ (1,0) [0|7] "" Vector__XXX
 SG_ DAAssrInvrtr3OprtnlCmmnd : 54|2@1+ (1,0) [0|3] "" Vector__XXX
 SG_ DAAssIvt3ASdMtSttRsVtRqst : 56|8@1+ (2,0) [0|500] "V" Vector__XXX

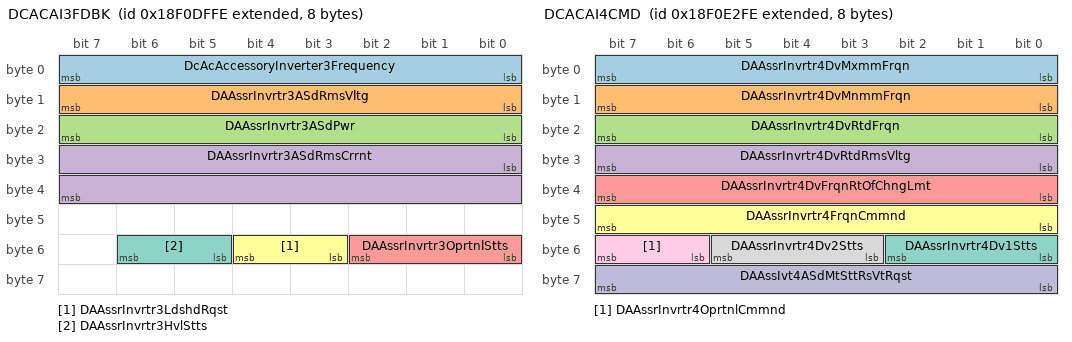
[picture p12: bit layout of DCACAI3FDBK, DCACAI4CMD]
BO_ 2565922814 DCACAI3FDBK: 8 Vector__XXX
 SG_ DcAcAccessoryInverter3Frequency : 0|8@1+ (1,0) [0|250] "Hz" Vector__XXX
 SG_ DAAssrInvrtr3ASdRmsVltg : 8|8@1+ (2,0) [0|500] "V" Vector__XXX
 SG_ DAAssrInvrtr3ASdPwr : 16|8@1+ (0.1,0) [0|25] "kW" Vector__XXX
 SG_ DAAssrInvrtr3ASdRmsCrrnt : 24|16@1+ (0.03125,0) [0|2007.96875] "A" Vector__XXX
 SG_ DAAssrInvrtr3OprtnlStts : 48|3@1+ (1,0) [0|7] "" Vector__XXX
 SG_ DAAssrInvrtr3LdshdRqst : 51|2@1+ (1,0) [0|3] "" Vector__XXX
 SG_ DAAssrInvrtr3HvlStts : 53|2@1+ (1,0) [0|3] "" Vector__XXX

BO_ 2565923582 DCACAI4CMD: 8 Vector__XXX
 SG_ DAAssrInvrtr4DvMxmmFrqn : 0|8@1+ (1,0) [0|250] "Hz" Vector__XXX
 SG_ DAAssrInvrtr4DvMnmmFrqn : 8|8@1+ (1,0) [0|250] "Hz" Vector__XXX
 SG_ DAAssrInvrtr4DvRtdFrqn : 16|8@1+ (1,0) [0|250] "Hz" Vector__XXX
 SG_ DAAssrInvrtr4DvRtdRmsVltg : 24|8@1+ (2,0) [0|500] "V" Vector__XXX
 SG_ DAAssrInvrtr4DvFrqnRtOfChngLmt : 32|8@1+ (2,0) [0|500] "Hz/s" Vector__XXX
 SG_ DAAssrInvrtr4FrqnCmmnd : 40|8@1+ (1,0) [0|250] "Hz" Vector__XXX
 SG_ DAAssrInvrtr4Dv1Stts : 48|3@1+ (1,0) [0|7] "" Vector__XXX
 SG_ DAAssrInvrtr4Dv2Stts : 51|3@1+ (1,0) [0|7] "" Vector__XXX
 SG_ DAAssrInvrtr4OprtnlCmmnd : 54|2@1+ (1,0) [0|3] "" Vector__XXX
 SG_ DAAssIvt4ASdMtSttRsVtRqst : 56|8@1+ (2,0) [0|500] "V" Vector__XXX

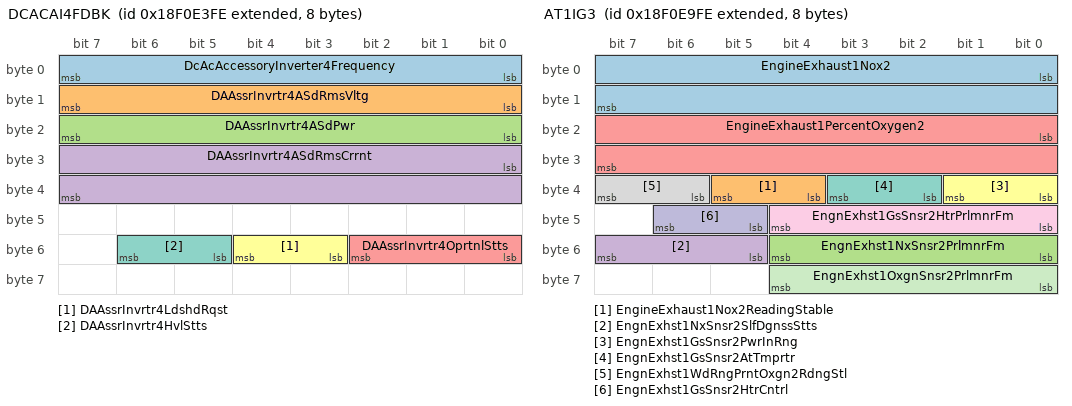
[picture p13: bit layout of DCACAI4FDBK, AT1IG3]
BO_ 2565923838 DCACAI4FDBK: 8 Vector__XXX
 SG_ DcAcAccessoryInverter4Frequency : 0|8@1+ (1,0) [0|250] "Hz" Vector__XXX
 SG_ DAAssrInvrtr4ASdRmsVltg : 8|8@1+ (2,0) [0|500] "V" Vector__XXX
 SG_ DAAssrInvrtr4ASdPwr : 16|8@1+ (0.1,0) [0|25] "kW" Vector__XXX
 SG_ DAAssrInvrtr4ASdRmsCrrnt : 24|16@1+ (0.03125,0) [0|2007.96875] "A" Vector__XXX
 SG_ DAAssrInvrtr4OprtnlStts : 48|3@1+ (1,0) [0|7] "" Vector__XXX
 SG_ DAAssrInvrtr4LdshdRqst : 51|2@1+ (1,0) [0|3] "" Vector__XXX
 SG_ DAAssrInvrtr4HvlStts : 53|2@1+ (1,0) [0|3] "" Vector__XXX

BO_ 2565925374 AT1IG3: 8 Vector__XXX
 SG_ EngineExhaust1Nox2 : 0|16@1+ (0.05,-200) [-200|3012.75] "ppm" Vector__XXX
 SG_ EngineExhaust1Nox2ReadingStable : 36|2@1+ (1,0) [0|3] "" Vector__XXX
 SG_ EngnExhst1NxSnsr2PrlmnrFm : 48|5@1+ (1,0) [0|31] "" Vector__XXX
 SG_ EngnExhst1NxSnsr2SlfDgnssStts : 53|3@1+ (1,0) [0|7] "" Vector__XXX
 SG_ EngineExhaust1PercentOxygen2 : 16|16@1+ (0.000514,-12) [-12|21.02707] "%" Vector__XXX
 SG_ EngnExhst1GsSnsr2PwrInRng : 32|2@1+ (1,0) [0|3] "" Vector__XXX
 SG_ EngnExhst1GsSnsr2AtTmprtr : 34|2@1+ (1,0) [0|3] "" Vector__XXX
 SG_ EngnExhst1WdRngPrntOxgn2RdngStl : 38|2@1+ (1,0) [0|3] "" Vector__XXX
 SG_ EngnExhst1GsSnsr2HtrPrlmnrFm : 40|5@1+ (1,0) [0|31] "" Vector__XXX
 SG_ EngnExhst1GsSnsr2HtrCntrl : 45|2@1+ (1,0) [0|3] "" Vector__XXX
 SG_ EngnExhst1OxgnSnsr2PrlmnrFm : 56|5@1+ (1,0) [0|31] "" Vector__XXX

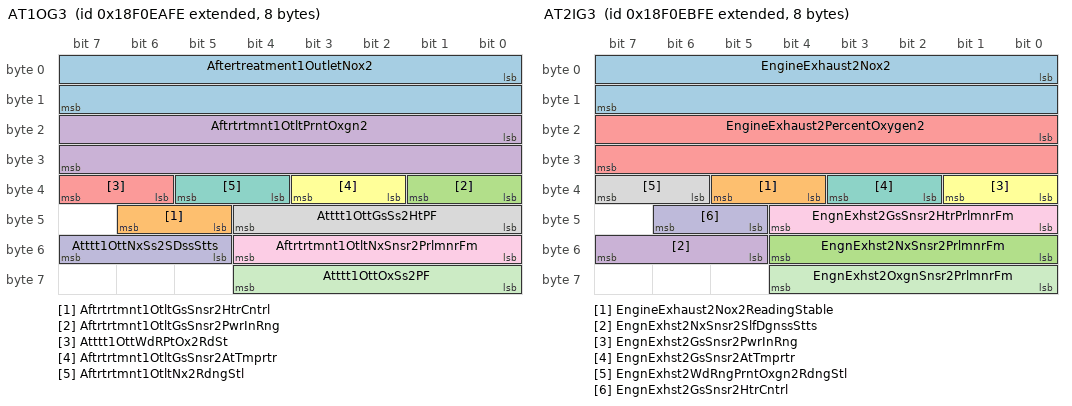
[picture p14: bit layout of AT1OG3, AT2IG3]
BO_ 2565925630 AT1OG3: 8 Vector__XXX
 SG_ Aftertreatment1OutletNox2 : 0|16@1+ (0.05,-200) [-200|3012.75] "ppm" Vector__XXX
 SG_ Aftrtrtmnt1OtltGsSnsr2HtrCntrl : 45|2@1+ (1,0) [0|3] "" Vector__XXX
 SG_ Aftrtrtmnt1OtltGsSnsr2PwrInRng : 32|2@1+ (1,0) [0|3] "" Vector__XXX
 SG_ Aftrtrtmnt1OtltPrntOxgn2 : 16|16@1+ (0.000514,-12) [-12|21.02707] "%" Vector__XXX
 SG_ Atttt1OttWdRPtOx2RdSt : 38|2@1+ (1,0) [0|3] "" Vector__XXX
 SG_ Aftrtrtmnt1OtltGsSnsr2AtTmprtr : 34|2@1+ (1,0) [0|3] "" Vector__XXX
 SG_ Aftrtrtmnt1OtltNx2RdngStl : 36|2@1+ (1,0) [0|3] "" Vector__XXX
 SG_ Atttt1OttGsSs2HtPF : 40|5@1+ (1,0) [0|31] "" Vector__XXX
 SG_ Aftrtrtmnt1OtltNxSnsr2PrlmnrFm : 48|5@1+ (1,0) [0|31] "" Vector__XXX
 SG_ Atttt1OttNxSs2SDssStts : 53|3@1+ (1,0) [0|7] "" Vector__XXX
 SG_ Atttt1OttOxSs2PF : 56|5@1+ (1,0) [0|31] "" Vector__XXX

BO_ 2565925886 AT2IG3: 8 Vector__XXX
 SG_ EngineExhaust2Nox2 : 0|16@1+ (0.05,-200) [-200|3012.75] "ppm" Vector__XXX
 SG_ EngineExhaust2Nox2ReadingStable : 36|2@1+ (1,0) [0|3] "" Vector__XXX
 SG_ EngnExhst2NxSnsr2PrlmnrFm : 48|5@1+ (1,0) [0|31] "" Vector__XXX
 SG_ EngnExhst2NxSnsr2SlfDgnssStts : 53|3@1+ (1,0) [0|7] "" Vector__XXX
 SG_ EngineExhaust2PercentOxygen2 : 16|16@1+ (0.000514,-12) [-12|21.02707] "%" Vector__XXX
 SG_ EngnExhst2GsSnsr2PwrInRng : 32|2@1+ (1,0) [0|3] "" Vector__XXX
 SG_ EngnExhst2GsSnsr2AtTmprtr : 34|2@1+ (1,0) [0|3] "" Vector__XXX
 SG_ EngnExhst2WdRngPrntOxgn2RdngStl : 38|2@1+ (1,0) [0|3] "" Vector__XXX
 SG_ EngnExhst2GsSnsr2HtrPrlmnrFm : 40|5@1+ (1,0) [0|31] "" Vector__XXX
 SG_ EngnExhst2GsSnsr2HtrCntrl : 45|2@1+ (1,0) [0|3] "" Vector__XXX
 SG_ EngnExhst2OxgnSnsr2PrlmnrFm : 56|5@1+ (1,0) [0|31] "" Vector__XXX

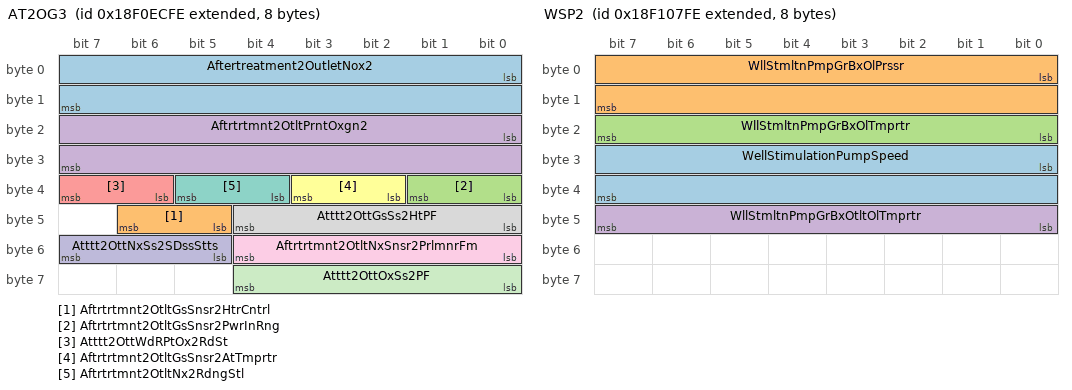
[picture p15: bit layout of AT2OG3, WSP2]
BO_ 2565926142 AT2OG3: 8 Vector__XXX
 SG_ Aftertreatment2OutletNox2 : 0|16@1+ (0.05,-200) [-200|3012.75] "ppm" Vector__XXX
 SG_ Aftrtrtmnt2OtltGsSnsr2HtrCntrl : 45|2@1+ (1,0) [0|3] "" Vector__XXX
 SG_ Aftrtrtmnt2OtltGsSnsr2PwrInRng : 32|2@1+ (1,0) [0|3] "" Vector__XXX
 SG_ Aftrtrtmnt2OtltPrntOxgn2 : 16|16@1+ (0.000514,-12) [-12|21.02707] "%" Vector__XXX
 SG_ Atttt2OttWdRPtOx2RdSt : 38|2@1+ (1,0) [0|3] "" Vector__XXX
 SG_ Aftrtrtmnt2OtltGsSnsr2AtTmprtr : 34|2@1+ (1,0) [0|3] "" Vector__XXX
 SG_ Aftrtrtmnt2OtltNx2RdngStl : 36|2@1+ (1,0) [0|3] "" Vector__XXX
 SG_ Atttt2OttGsSs2HtPF : 40|5@1+ (1,0) [0|31] "" Vector__XXX
 SG_ Aftrtrtmnt2OtltNxSnsr2PrlmnrFm : 48|5@1+ (1,0) [0|31] "" Vector__XXX
 SG_ Atttt2OttNxSs2SDssStts : 53|3@1+ (1,0) [0|7] "" Vector__XXX
 SG_ Atttt2OttOxSs2PF : 56|5@1+ (1,0) [0|31] "" Vector__XXX

BO_ 2565932286 ESSI2: 8 Vector__XXX
 SG_ EngineSpeed4 : 0|16@1+ (0.5,0) [0|32127.5] "rpm" Vector__XXX

BO_ 2565932798 WSP1: 8 Vector__XXX
 SG_ WllStmltnPmpDshrgPrssr : 16|16@1+ (5,0) [0|321275] "kPa" Vector__XXX
 SG_ WllStmltnPmpStnPrssr : 0|16@1+ (0.1,-3212.7) [-3212.7|3212.8] "kPa" Vector__XXX

BO_ 2565933054 WSP2: 8 Vector__XXX
 SG_ WellStimulationPumpSpeed : 24|16@1+ (0.125,0) [0|8031.875] "rpm" Vector__XXX
 SG_ WllStmltnPmpGrBxOlPrssr : 0|16@1+ (0.1,0) [0|6425.5] "kPa" Vector__XXX
 SG_ WllStmltnPmpGrBxOlTmprtr : 16|8@1+ (1,-40) [-40|210] "degC" Vector__XXX
 SG_ WllStmltnPmpGrBxOtltOlTmprtr : 40|8@1+ (1,-40) [-40|210] "degC" Vector__XXX

BO_ 2565934590 GFI6: 8 Vector__XXX
 SG_ EngnFlVlv2DffrntlPrssr : 0|16@1+ (0.1,0) [0|6425.5] "kPa" Vector__XXX

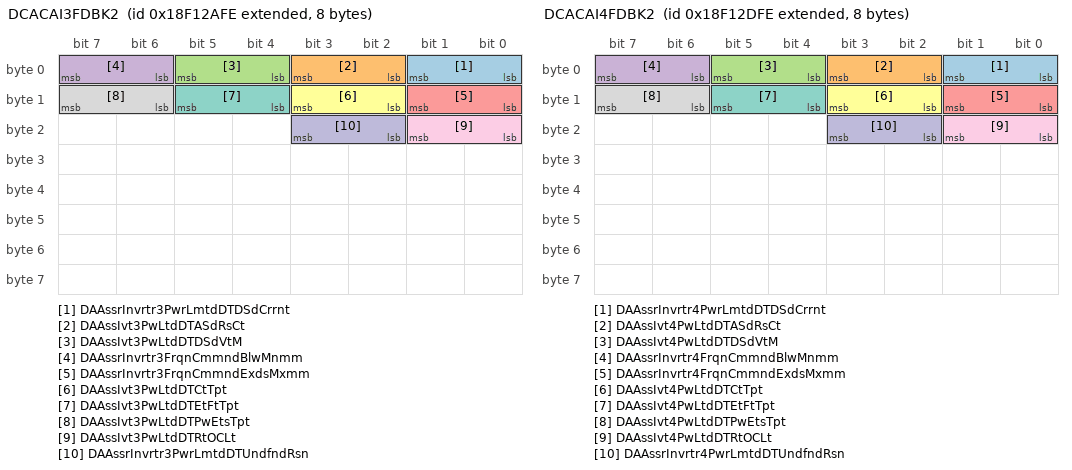
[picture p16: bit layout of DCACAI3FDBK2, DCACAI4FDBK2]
BO_ 2565942014 DCACAI3FDBK2: 8 Vector__XXX
 SG_ DAAssrInvrtr3PwrLmtdDTDSdCrrnt : 0|2@1+ (1,0) [0|3] "" Vector__XXX
 SG_ DAAssIvt3PwLtdDTASdRsCt : 2|2@1+ (1,0) [0|3] "" Vector__XXX
 SG_ DAAssIvt3PwLtdDTDSdVtM : 4|2@1+ (1,0) [0|3] "" Vector__XXX
 SG_ DAAssrInvrtr3FrqnCmmndBlwMnmm : 6|2@1+ (1,0) [0|3] "" Vector__XXX
 SG_ DAAssrInvrtr3FrqnCmmndExdsMxmm : 8|2@1+ (1,0) [0|3] "" Vector__XXX
 SG_ DAAssIvt3PwLtdDTCtTpt : 10|2@1+ (1,0) [0|3] "" Vector__XXX
 SG_ DAAssIvt3PwLtdDTEtFtTpt : 12|2@1+ (1,0) [0|3] "" Vector__XXX
 SG_ DAAssIvt3PwLtdDTPwEtsTpt : 14|2@1+ (1,0) [0|3] "" Vector__XXX
 SG_ DAAssIvt3PwLtdDTRtOCLt : 16|2@1+ (1,0) [0|3] "" Vector__XXX
 SG_ DAAssrInvrtr3PwrLmtdDTUndfndRsn : 18|2@1+ (1,0) [0|3] "" Vector__XXX

BO_ 2565942782 DCACAI4FDBK2: 8 Vector__XXX
 SG_ DAAssrInvrtr4PwrLmtdDTDSdCrrnt : 0|2@1+ (1,0) [0|3] "" Vector__XXX
 SG_ DAAssIvt4PwLtdDTASdRsCt : 2|2@1+ (1,0) [0|3] "" Vector__XXX
 SG_ DAAssIvt4PwLtdDTDSdVtM : 4|2@1+ (1,0) [0|3] "" Vector__XXX
 SG_ DAAssrInvrtr4FrqnCmmndBlwMnmm : 6|2@1+ (1,0) [0|3] "" Vector__XXX
 SG_ DAAssrInvrtr4FrqnCmmndExdsMxmm : 8|2@1+ (1,0) [0|3] "" Vector__XXX
 SG_ DAAssIvt4PwLtdDTCtTpt : 10|2@1+ (1,0) [0|3] "" Vector__XXX
 SG_ DAAssIvt4PwLtdDTEtFtTpt : 12|2@1+ (1,0) [0|3] "" Vector__XXX
 SG_ DAAssIvt4PwLtdDTPwEtsTpt : 14|2@1+ (1,0) [0|3] "" Vector__XXX
 SG_ DAAssIvt4PwLtdDTRtOCLt : 16|2@1+ (1,0) [0|3] "" Vector__XXX
 SG_ DAAssrInvrtr4PwrLmtdDTUndfndRsn : 18|2@1+ (1,0) [0|3] "" Vector__XXX

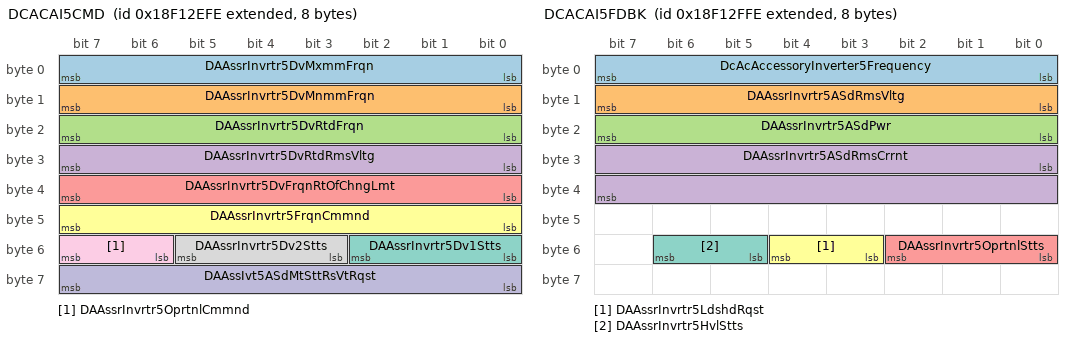
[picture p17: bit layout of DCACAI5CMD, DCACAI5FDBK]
BO_ 2565943038 DCACAI5CMD: 8 Vector__XXX
 SG_ DAAssrInvrtr5DvMxmmFrqn : 0|8@1+ (1,0) [0|250] "Hz" Vector__XXX
 SG_ DAAssrInvrtr5DvMnmmFrqn : 8|8@1+ (1,0) [0|250] "Hz" Vector__XXX
 SG_ DAAssrInvrtr5DvRtdFrqn : 16|8@1+ (1,0) [0|250] "Hz" Vector__XXX
 SG_ DAAssrInvrtr5DvRtdRmsVltg : 24|8@1+ (2,0) [0|500] "V" Vector__XXX
 SG_ DAAssrInvrtr5DvFrqnRtOfChngLmt : 32|8@1+ (2,0) [0|500] "Hz/s" Vector__XXX
 SG_ DAAssrInvrtr5FrqnCmmnd : 40|8@1+ (1,0) [0|250] "Hz" Vector__XXX
 SG_ DAAssrInvrtr5Dv1Stts : 48|3@1+ (1,0) [0|7] "" Vector__XXX
 SG_ DAAssrInvrtr5Dv2Stts : 51|3@1+ (1,0) [0|7] "" Vector__XXX
 SG_ DAAssrInvrtr5OprtnlCmmnd : 54|2@1+ (1,0) [0|3] "" Vector__XXX
 SG_ DAAssIvt5ASdMtSttRsVtRqst : 56|8@1+ (2,0) [0|500] "V" Vector__XXX

BO_ 2565943294 DCACAI5FDBK: 8 Vector__XXX
 SG_ DcAcAccessoryInverter5Frequency : 0|8@1+ (1,0) [0|250] "Hz" Vector__XXX
 SG_ DAAssrInvrtr5ASdRmsVltg : 8|8@1+ (2,0) [0|500] "V" Vector__XXX
 SG_ DAAssrInvrtr5ASdPwr : 16|8@1+ (0.1,0) [0|25] "kW" Vector__XXX
 SG_ DAAssrInvrtr5ASdRmsCrrnt : 24|16@1+ (0.03125,0) [0|2007.96875] "A" Vector__XXX
 SG_ DAAssrInvrtr5OprtnlStts : 48|3@1+ (1,0) [0|7] "" Vector__XXX
 SG_ DAAssrInvrtr5LdshdRqst : 51|2@1+ (1,0) [0|3] "" Vector__XXX
 SG_ DAAssrInvrtr5HvlStts : 53|2@1+ (1,0) [0|3] "" Vector__XXX

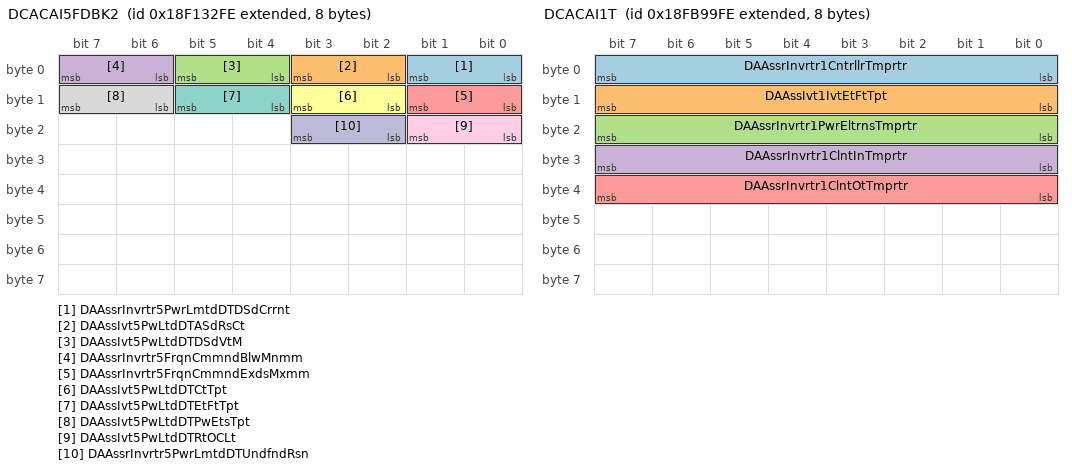
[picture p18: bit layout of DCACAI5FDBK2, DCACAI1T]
BO_ 2565944062 DCACAI5FDBK2: 8 Vector__XXX
 SG_ DAAssrInvrtr5PwrLmtdDTDSdCrrnt : 0|2@1+ (1,0) [0|3] "" Vector__XXX
 SG_ DAAssIvt5PwLtdDTASdRsCt : 2|2@1+ (1,0) [0|3] "" Vector__XXX
 SG_ DAAssIvt5PwLtdDTDSdVtM : 4|2@1+ (1,0) [0|3] "" Vector__XXX
 SG_ DAAssrInvrtr5FrqnCmmndBlwMnmm : 6|2@1+ (1,0) [0|3] "" Vector__XXX
 SG_ DAAssrInvrtr5FrqnCmmndExdsMxmm : 8|2@1+ (1,0) [0|3] "" Vector__XXX
 SG_ DAAssIvt5PwLtdDTCtTpt : 10|2@1+ (1,0) [0|3] "" Vector__XXX
 SG_ DAAssIvt5PwLtdDTEtFtTpt : 12|2@1+ (1,0) [0|3] "" Vector__XXX
 SG_ DAAssIvt5PwLtdDTPwEtsTpt : 14|2@1+ (1,0) [0|3] "" Vector__XXX
 SG_ DAAssIvt5PwLtdDTRtOCLt : 16|2@1+ (1,0) [0|3] "" Vector__XXX
 SG_ DAAssrInvrtr5PwrLmtdDTUndfndRsn : 18|2@1+ (1,0) [0|3] "" Vector__XXX

BO_ 2566624510 EEC22: 8 Vector__XXX
 SG_ EngnExhstGsRrltn1ClrIntkPrssr : 0|16@1+ (5,0) [0|321275] "kPa" Vector__XXX
 SG_ TtlNmrOfCrnkAttmptsDrngEngnLf : 16|32@1+ (1,0) [0|4211081215] "count" Vector__XXX

BO_ 2566624766 HOURS2: 8 Vector__XXX
 SG_ EngnIdlMngmntAtvTtlTm : 0|32@1+ (0.05,0) [0|210554060.75] "h" Vector__XXX

BO_ 2566625022 EI3: 8 Vector__XXX
 SG_ InstntnsEstmtdEngnPwrRtLmt : 0|16@1+ (0.125,0) [0|8031.875] "kW/s" Vector__XXX
 SG_ EngineExhaustBank1Pressure2 : 16|16@1+ (0.0078125,-250) [-250|251.9921875] "kPa" Vector__XXX
 SG_ EngineDifferentialPressure : 32|16@1+ (0.0078125,-250) [-250|251.9921875] "kPa" Vector__XXX

BO_ 2566625278 VEP15: 8 Vector__XXX
 SG_ SlBttrPk1Bttr1CptSttng : 0|16@1+ (1,0) [0|64255] "Ah" Vector__XXX
 SG_ SlBttrPk1Bttr2CptSttng : 16|16@1+ (1,0) [0|64255] "Ah" Vector__XXX
 SG_ SlBttrPk1Bttr3CptSttng : 32|16@1+ (1,0) [0|64255] "Ah" Vector__XXX
 SG_ SlBttrPk1Bttr4CptSttng : 48|16@1+ (1,0) [0|64255] "Ah" Vector__XXX

BO_ 2566625790 DCACAI1T: 8 Vector__XXX
 SG_ DAAssrInvrtr1CntrllrTmprtr : 0|8@1+ (1,-40) [-40|210] "degC" Vector__XXX
 SG_ DAAssIvt1IvtEtFtTpt : 8|8@1+ (1,-40) [-40|210] "degC" Vector__XXX
 SG_ DAAssrInvrtr1PwrEltrnsTmprtr : 16|8@1+ (1,-40) [-40|210] "degC" Vector__XXX
 SG_ DAAssrInvrtr1ClntInTmprtr : 24|8@1+ (1,-40) [-40|210] "degC" Vector__XXX
 SG_ DAAssrInvrtr1ClntOtTmprtr : 32|8@1+ (1,-40) [-40|210] "degC" Vector__XXX

BO_ 2566626558 DCACAI1CFG1: 13 Vector__XXX
 SG_ DAAssIvt1DSdVtMLtStt : 0|16@1+ (0.05,0) [0|3212.75] "V" Vector__XXX
 SG_ DAAssIvt1DSdCtMxLtStt : 16|16@1+ (0.05,0) [0|3212.75] "A" Vector__XXX
 SG_ DAAssIvt1ASdRsVtMxLtStt : 32|16@1+ (0.03125,0) [0|2007.96875] "V" Vector__XXX
 SG_ DAAssIvt1ASdRsCtMxLtStt : 48|16@1+ (0.03125,0) [0|2007.96875] "A" Vector__XXX
 SG_ DAAssIvt1DSdVtMxLtStt : 64|16@1+ (0.05,0) [0|3212.75] "V" Vector__XXX
 SG_ DAAssIvt1DSdCtMLtStt : 80|16@1+ (0.05,-3212.75) [-3212.75|0] "A" Vector__XXX
 SG_ DAAssIvt1ASdDtFqCdStt : 96|8@1+ (1,0) [0|250] "Hz" Vector__XXX

BO_ 2566626814 DCACAI1LD: 8 Vector__XXX
 SG_ DAAssrInvrtr1TtlDInptChrg : 0|32@1+ (100,0) [0|421108121500] "Ah" Vector__XXX
 SG_ DAAssrInvrtr1TtlDInptEnrg : 32|32@1+ (100,0) [0|421108121500] "Watt-hour" Vector__XXX

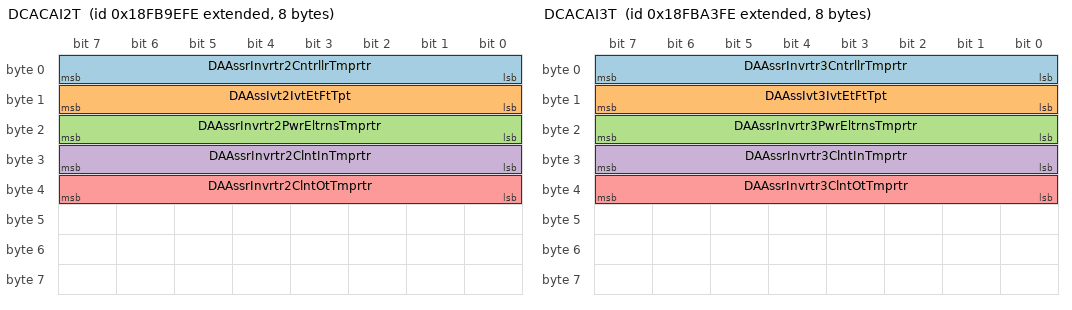
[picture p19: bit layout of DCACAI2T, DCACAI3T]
BO_ 2566627070 DCACAI2T: 8 Vector__XXX
 SG_ DAAssrInvrtr2CntrllrTmprtr : 0|8@1+ (1,-40) [-40|210] "degC" Vector__XXX
 SG_ DAAssIvt2IvtEtFtTpt : 8|8@1+ (1,-40) [-40|210] "degC" Vector__XXX
 SG_ DAAssrInvrtr2PwrEltrnsTmprtr : 16|8@1+ (1,-40) [-40|210] "degC" Vector__XXX
 SG_ DAAssrInvrtr2ClntInTmprtr : 24|8@1+ (1,-40) [-40|210] "degC" Vector__XXX
 SG_ DAAssrInvrtr2ClntOtTmprtr : 32|8@1+ (1,-40) [-40|210] "degC" Vector__XXX

BO_ 2566627838 DCACAI2CFG1: 13 Vector__XXX
 SG_ DAAssIvt2DSdVtMLtStt : 0|16@1+ (0.05,0) [0|3212.75] "V" Vector__XXX
 SG_ DAAssIvt2DSdCtMxLtStt : 16|16@1+ (0.05,0) [0|3212.75] "A" Vector__XXX
 SG_ DAAssIvt2ASdRsVtMxLtStt : 32|16@1+ (0.03125,0) [0|2007.96875] "V" Vector__XXX
 SG_ DAAssIvt2ASdRsCtMxLtStt : 48|16@1+ (0.03125,0) [0|2007.96875] "A" Vector__XXX
 SG_ DAAssIvt2DSdVtMxLtStt : 64|16@1+ (0.05,0) [0|3212.75] "V" Vector__XXX
 SG_ DAAssIvt2DSdCtMLtStt : 80|16@1+ (0.05,-3212.75) [-3212.75|0] "A" Vector__XXX
 SG_ DAAssIvt2ASdDtFqCdStt : 96|8@1+ (1,0) [0|250] "Hz" Vector__XXX

BO_ 2566628094 DCACAI2LD: 8 Vector__XXX
 SG_ DAAssrInvrtr2TtlDInptChrg : 0|32@1+ (100,0) [0|421108121500] "Ah" Vector__XXX
 SG_ DAAssrInvrtr2TtlDInptEnrg : 32|32@1+ (100,0) [0|421108121500] "Watt-hour" Vector__XXX

BO_ 2566628350 DCACAI3T: 8 Vector__XXX
 SG_ DAAssrInvrtr3CntrllrTmprtr : 0|8@1+ (1,-40) [-40|210] "degC" Vector__XXX
 SG_ DAAssIvt3IvtEtFtTpt : 8|8@1+ (1,-40) [-40|210] "degC" Vector__XXX
 SG_ DAAssrInvrtr3PwrEltrnsTmprtr : 16|8@1+ (1,-40) [-40|210] "degC" Vector__XXX
 SG_ DAAssrInvrtr3ClntInTmprtr : 24|8@1+ (1,-40) [-40|210] "degC" Vector__XXX
 SG_ DAAssrInvrtr3ClntOtTmprtr : 32|8@1+ (1,-40) [-40|210] "degC" Vector__XXX

CM_ BO_ 2561081086 "Auxiliary Input/Output Status 3";
CM_ SG_ 2561081086 AuxiliaryIO49 "Auxiliary I/O #49: Identifies the current status of auxiliary input/output functions that are configured uniquely per application.00b = Auxiliary channel off01b = Auxiliary channel on10b = Error Indicator or Not Used , depending on application11b = N...";
CM_ SG_ 2561081086 AuxiliaryIO50 "Auxiliary I/O #50: Identifies the current status of auxiliary input/output functions that are configured uniquely per application.00b = Auxiliary channel off01b = Auxiliary channel on10b = Error Indicator or Not Used , depending on application11b = N...";
CM_ SG_ 2561081086 AuxiliaryIO51 "Auxiliary I/O #51: Identifies the current status of auxiliary input/output functions that are configured uniquely per application.00b = Auxiliary channel off01b = Auxiliary channel on10b = Error Indicator or Not Used , depending on application11b = N...";
CM_ SG_ 2561081086 AuxiliaryIO52 "Auxiliary I/O #52: Identifies the current status of auxiliary input/output functions that are configured uniquely per application.00b = Auxiliary channel off01b = Auxiliary channel on10b = Error Indicator or Not Used , depending on application11b = N...";
CM_ SG_ 2561081086 AuxiliaryIO53 "Auxiliary I/O #53: Identifies the current status of auxiliary input/output functions that are configured uniquely per application.00b = Auxiliary channel off01b = Auxiliary channel on10b = Error Indicator or Not Used , depending on application11b = N...";
CM_ SG_ 2561081086 AuxiliaryIO54 "Auxiliary I/O #54: Identifies the current status of auxiliary input/output functions that are configured uniquely per application.00b = Auxiliary channel off01b = Auxiliary channel on10b = Error Indicator or Not Used , depending on application11b = N...";
CM_ SG_ 2561081086 AuxiliaryIO55 "Auxiliary I/O #55: Identifies the current status of auxiliary input/output functions that are configured uniquely per application.00b = Auxiliary channel off01b = Auxiliary channel on10b = Error Indicator or Not Used , depending on application11b = N...";
CM_ SG_ 2561081086 AuxiliaryIO56 "Auxiliary I/O #56: Identifies the current status of auxiliary input/output functions that are configured uniquely per application.00b = Auxiliary channel off01b = Auxiliary channel on10b = Error Indicator or Not Used , depending on application11b = N...";
CM_ SG_ 2561081086 AuxiliaryIO57 "Auxiliary I/O #57: Identifies the current status of auxiliary input/output functions that are configured uniquely per application.00b = Auxiliary channel off01b = Auxiliary channel on10b = Error Indicator or Not Used , depending on application11b = N...";
CM_ SG_ 2561081086 AuxiliaryIO58 "Auxiliary I/O #58: Identifies the current status of auxiliary input/output functions that are configured uniquely per application.00b = Auxiliary channel off01b = Auxiliary channel on10b = Error Indicator or Not Used , depending on application11b = N...";
CM_ SG_ 2561081086 AuxiliaryIO59 "Auxiliary I/O #59: Identifies the current status of auxiliary input/output functions that are configured uniquely per application.00b = Auxiliary channel off01b = Auxiliary channel on10b = Error Indicator or Not Used , depending on application11b = N...";
CM_ SG_ 2561081086 AuxiliaryIO60 "Auxiliary I/O #60: Identifies the current status of auxiliary input/output functions that are configured uniquely per application.00b = Auxiliary channel off01b = Auxiliary channel on10b = Error Indicator or Not Used , depending on application11b = N...";
CM_ SG_ 2561081086 AuxiliaryIO61 "Auxiliary I/O #61: Identifies the current status of auxiliary input/output functions that are configured uniquely per application.00b = Auxiliary channel off01b = Auxiliary channel on10b = Error Indicator or Not Used , depending on application11b = N...";
CM_ SG_ 2561081086 AuxiliaryIO62 "Auxiliary I/O #62: Identifies the current status of auxiliary input/output functions that are configured uniquely per application.00b = Auxiliary channel off01b = Auxiliary channel on10b = Error Indicator or Not Used , depending on application11b = N...";
CM_ SG_ 2561081086 AuxiliaryIO63 "Auxiliary I/O #63: Identifies the current status of auxiliary input/output functions that are configured uniquely per application.00b = Auxiliary channel off01b = Auxiliary channel on10b = Error Indicator or Not Used , depending on application11b = N...";
CM_ SG_ 2561081086 AuxiliaryIO64 "Auxiliary I/O #64: Identifies the current status of auxiliary input/output functions that are configured uniquely per application.00b = Auxiliary channel off01b = Auxiliary channel on10b = Error Indicator or Not Used , depending on application11b = N...";
CM_ SG_ 2561081086 AuxiliaryIO65 "Auxiliary I/O #65: Identifies the current status of auxiliary input/output functions that are configured uniquely per application.00b = Auxiliary channel off01b = Auxiliary channel on10b = Error Indicator or Not Used , depending on application11b = N...";
CM_ SG_ 2561081086 AuxiliaryIO66 "Auxiliary I/O #66: Identifies the current status of auxiliary input/output functions that are configured uniquely per application.00b = Auxiliary channel off01b = Auxiliary channel on10b = Error Indicator or Not Used , depending on application11b = N...";
CM_ SG_ 2561081086 AuxiliaryIO67 "Auxiliary I/O #67: Identifies the current status of auxiliary input/output functions that are configured uniquely per application.00b = Auxiliary channel off01b = Auxiliary channel on10b = Error Indicator or Not Used , depending on application11b = N...";
CM_ SG_ 2561081086 AuxiliaryIO68 "Auxiliary I/O #68: Identifies the current status of auxiliary input/output functions that are configured uniquely per application.00b = Auxiliary channel off01b = Auxiliary channel on10b = Error Indicator or Not Used , depending on application11b = N...";
CM_ SG_ 2561081086 AuxiliaryIO69 "Auxiliary I/O #69: Identifies the current status of auxiliary input/output functions that are configured uniquely per application.00b = Auxiliary channel off01b = Auxiliary channel on10b = Error Indicator or Not Used , depending on application11b = N...";
CM_ SG_ 2561081086 AuxiliaryIO70 "Auxiliary I/O #70: Identifies the current status of auxiliary input/output functions that are configured uniquely per application.00b = Auxiliary channel off01b = Auxiliary channel on10b = Error Indicator or Not Used , depending on application11b = N...";
CM_ SG_ 2561081086 AuxiliaryIO71 "Auxiliary I/O #71: Identifies the current status of auxiliary input/output functions that are configured uniquely per application.00b = Auxiliary channel off01b = Auxiliary channel on10b = Error Indicator or Not Used , depending on application11b = N...";
CM_ SG_ 2561081086 AuxiliaryIO72 "Auxiliary I/O #72: Identifies the current status of auxiliary input/output functions that are configured uniquely per application.00b = Auxiliary channel off01b = Auxiliary channel on10b = Error Indicator or Not Used , depending on application11b = N...";
CM_ SG_ 2561081086 AuxiliaryIO73 "Auxiliary I/O #73: Identifies the current status of auxiliary input/output functions that are configured uniquely per application.00b = Auxiliary channel off01b = Auxiliary channel on10b = Error Indicator or Not Used , depending on application11b = N...";
CM_ SG_ 2561081086 AuxiliaryIO74 "Auxiliary I/O #74: Identifies the current status of auxiliary input/output functions that are configured uniquely per application.00b = Auxiliary channel off01b = Auxiliary channel on10b = Error Indicator or Not Used , depending on application11b = N...";
CM_ SG_ 2561081086 AuxiliaryIO75 "Auxiliary I/O #75: Identifies the current status of auxiliary input/output functions that are configured uniquely per application.00b = Auxiliary channel off01b = Auxiliary channel on10b = Error Indicator or Not Used , depending on application11b = N...";
CM_ SG_ 2561081086 AuxiliaryIO76 "Auxiliary I/O #76: Identifies the current status of auxiliary input/output functions that are configured uniquely per application.00b = Auxiliary channel off01b = Auxiliary channel on10b = Error Indicator or Not Used , depending on application11b = N...";
CM_ SG_ 2561081086 AuxiliaryIO77 "Auxiliary I/O #77: Identifies the current status of auxiliary input/output functions that are configured uniquely per application.00b = Auxiliary channel off01b = Auxiliary channel on10b = Error Indicator or Not Used , depending on application11b = N...";
CM_ SG_ 2561081086 AuxiliaryIO78 "Auxiliary I/O #78: Identifies the current status of auxiliary input/output functions that are configured uniquely per application.00b = Auxiliary channel off01b = Auxiliary channel on10b = Error Indicator or Not Used , depending on application11b = N...";
CM_ SG_ 2561081086 AuxiliaryIO79 "Auxiliary I/O #79: Identifies the current status of auxiliary input/output functions that are configured uniquely per application.00b = Auxiliary channel off01b = Auxiliary channel on10b = Error Indicator or Not Used , depending on application11b = N...";
CM_ SG_ 2561081086 AuxiliaryIO80 "Auxiliary I/O #80: Identifies the current status of auxiliary input/output functions that are configured uniquely per application.00b = Auxiliary channel off01b = Auxiliary channel on10b = Error Indicator or Not Used , depending on application11b = N...";
CM_ BO_ 2561146622 "Auxiliary Input/Output Status 2";
CM_ SG_ 2561146622 AuxiliaryIO17 "Auxiliary I/O #17: Identifies the current status of auxiliary input/output functions that are configured uniquely per application.00b = Auxiliary channel off01b = Auxiliary channel on10b = Error Indicator or Not Used , depending on application11b = N...";
CM_ SG_ 2561146622 AuxiliaryIO18 "Auxiliary I/O #18: Identifies the current status of auxiliary input/output functions that are configured uniquely per application.00b = Auxiliary channel off01b = Auxiliary channel on10b = Error Indicator or Not Used , depending on application11b = N...";
CM_ SG_ 2561146622 AuxiliaryIO19 "Auxiliary I/O #19: Identifies the current status of auxiliary input/output functions that are configured uniquely per application.00b = Auxiliary channel off01b = Auxiliary channel on10b = Error Indicator or Not Used , depending on application11b = N...";
CM_ SG_ 2561146622 AuxiliaryIO20 "Auxiliary I/O #20: Identifies the current status of auxiliary input/output functions that are configured uniquely per application.00b = Auxiliary channel off01b = Auxiliary channel on10b = Error Indicator or Not Used , depending on application11b = N...";
CM_ SG_ 2561146622 AuxiliaryIO21 "Auxiliary I/O #21: Identifies the current status of auxiliary input/output functions that are configured uniquely per application.00b = Auxiliary channel off01b = Auxiliary channel on10b = Error Indicator or Not Used , depending on application11b = N...";
CM_ SG_ 2561146622 AuxiliaryIO22 "Auxiliary I/O #22: Identifies the current status of auxiliary input/output functions that are configured uniquely per application.00b = Auxiliary channel off01b = Auxiliary channel on10b = Error Indicator or Not Used , depending on application11b = N...";
CM_ SG_ 2561146622 AuxiliaryIO23 "Auxiliary I/O #23: Identifies the current status of auxiliary input/output functions that are configured uniquely per application.00b = Auxiliary channel off01b = Auxiliary channel on10b = Error Indicator or Not Used , depending on application11b = N...";
CM_ SG_ 2561146622 AuxiliaryIO24 "Auxiliary I/O #24: Identifies the current status of auxiliary input/output functions that are configured uniquely per application.00b = Auxiliary channel off01b = Auxiliary channel on10b = Error Indicator or Not Used , depending on application11b = N...";
CM_ SG_ 2561146622 AuxiliaryIO25 "Auxiliary I/O #25: Identifies the current status of auxiliary input/output functions that are configured uniquely per application.00b = Auxiliary channel off01b = Auxiliary channel on10b = Error Indicator or Not Used , depending on application11b = N...";
CM_ SG_ 2561146622 AuxiliaryIO26 "Auxiliary I/O #26: Identifies the current status of auxiliary input/output functions that are configured uniquely per application.00b = Auxiliary channel off01b = Auxiliary channel on10b = Error Indicator or Not Used , depending on application11b = N...";
CM_ SG_ 2561146622 AuxiliaryIO27 "Auxiliary I/O #27: Identifies the current status of auxiliary input/output functions that are configured uniquely per application.00b = Auxiliary channel off01b = Auxiliary channel on10b = Error Indicator or Not Used , depending on application11b = N...";
CM_ SG_ 2561146622 AuxiliaryIO28 "Auxiliary I/O #28: Identifies the current status of auxiliary input/output functions that are configured uniquely per application.00b = Auxiliary channel off01b = Auxiliary channel on10b = Error Indicator or Not Used , depending on application11b = N...";
CM_ SG_ 2561146622 AuxiliaryIO29 "Auxiliary I/O #29: Identifies the current status of auxiliary input/output functions that are configured uniquely per application.00b = Auxiliary channel off01b = Auxiliary channel on10b = Error Indicator or Not Used , depending on application11b = N...";
CM_ SG_ 2561146622 AuxiliaryIO30 "Auxiliary I/O #30: Identifies the current status of auxiliary input/output functions that are configured uniquely per application.00b = Auxiliary channel off01b = Auxiliary channel on10b = Error Indicator or Not Used , depending on application11b = N...";
CM_ SG_ 2561146622 AuxiliaryIO31 "Auxiliary I/O #31: Identifies the current status of auxiliary input/output functions that are configured uniquely per application.00b = Auxiliary channel off01b = Auxiliary channel on10b = Error Indicator or Not Used , depending on application11b = N...";
CM_ SG_ 2561146622 AuxiliaryIO32 "Auxiliary I/O #32: Identifies the current status of auxiliary input/output functions that are configured uniquely per application.00b = Auxiliary channel off01b = Auxiliary channel on10b = Error Indicator or Not Used , depending on application11b = N...";
CM_ SG_ 2561146622 AuxiliaryIO33 "Auxiliary I/O #33: Identifies the current status of auxiliary input/output functions that are configured uniquely per application.00b = Auxiliary channel off01b = Auxiliary channel on10b = Error Indicator or Not Used , depending on application11b = N...";
CM_ SG_ 2561146622 AuxiliaryIO34 "Auxiliary I/O #34: Identifies the current status of auxiliary input/output functions that are configured uniquely per application.00b = Auxiliary channel off01b = Auxiliary channel on10b = Error Indicator or Not Used , depending on application11b = N...";
CM_ SG_ 2561146622 AuxiliaryIO35 "Auxiliary I/O #35: Identifies the current status of auxiliary input/output functions that are configured uniquely per application.00b = Auxiliary channel off01b = Auxiliary channel on10b = Error Indicator or Not Used , depending on application11b = N...";
CM_ SG_ 2561146622 AuxiliaryIO36 "Auxiliary I/O #36: Identifies the current status of auxiliary input/output functions that are configured uniquely per application.00b = Auxiliary channel off01b = Auxiliary channel on10b = Error Indicator or Not Used , depending on application11b = N...";
CM_ SG_ 2561146622 AuxiliaryIO37 "Auxiliary I/O #37: Identifies the current status of auxiliary input/output functions that are configured uniquely per application.00b = Auxiliary channel off01b = Auxiliary channel on10b = Error Indicator or Not Used , depending on application11b = N...";
CM_ SG_ 2561146622 AuxiliaryIO38 "Auxiliary I/O #38: Identifies the current status of auxiliary input/output functions that are configured uniquely per application.00b = Auxiliary channel off01b = Auxiliary channel on10b = Error Indicator or Not Used , depending on application11b = N...";
CM_ SG_ 2561146622 AuxiliaryIO39 "Auxiliary I/O #39: Identifies the current status of auxiliary input/output functions that are configured uniquely per application.00b = Auxiliary channel off01b = Auxiliary channel on10b = Error Indicator or Not Used , depending on application11b = N...";
CM_ SG_ 2561146622 AuxiliaryIO40 "Auxiliary I/O #40: Identifies the current status of auxiliary input/output functions that are configured uniquely per application.00b = Auxiliary channel off01b = Auxiliary channel on10b = Error Indicator or Not Used , depending on application11b = N...";
CM_ SG_ 2561146622 AuxiliaryIO41 "Auxiliary I/O #41: Identifies the current status of auxiliary input/output functions that are configured uniquely per application.00b = Auxiliary channel off01b = Auxiliary channel on10b = Error Indicator or Not Used , depending on application11b = N...";
CM_ SG_ 2561146622 AuxiliaryIO42 "Auxiliary I/O #42: Identifies the current status of auxiliary input/output functions that are configured uniquely per application.00b = Auxiliary channel off01b = Auxiliary channel on10b = Error Indicator or Not Used , depending on application11b = N...";
CM_ SG_ 2561146622 AuxiliaryIO43 "Auxiliary I/O #43: Identifies the current status of auxiliary input/output functions that are configured uniquely per application.00b = Auxiliary channel off01b = Auxiliary channel on10b = Error Indicator or Not Used , depending on application11b = N...";
CM_ SG_ 2561146622 AuxiliaryIO44 "Auxiliary I/O #44: Identifies the current status of auxiliary input/output functions that are configured uniquely per application.00b = Auxiliary channel off01b = Auxiliary channel on10b = Error Indicator or Not Used , depending on application11b = N...";
CM_ SG_ 2561146622 AuxiliaryIO45 "Auxiliary I/O #45: Identifies the current status of auxiliary input/output functions that are configured uniquely per application.00b = Auxiliary channel off01b = Auxiliary channel on10b = Error Indicator or Not Used , depending on application11b = N...";
CM_ SG_ 2561146622 AuxiliaryIO46 "Auxiliary I/O #46: Identifies the current status of auxiliary input/output functions that are configured uniquely per application.00b = Auxiliary channel off01b = Auxiliary channel on10b = Error Indicator or Not Used , depending on application11b = N...";
CM_ SG_ 2561146622 AuxiliaryIO47 "Auxiliary I/O #47: Identifies the current status of auxiliary input/output functions that are configured uniquely per application.00b = Auxiliary channel off01b = Auxiliary channel on10b = Error Indicator or Not Used , depending on application11b = N...";
CM_ SG_ 2561146622 AuxiliaryIO48 "Auxiliary I/O #48: Identifies the current status of auxiliary input/output functions that are configured uniquely per application.00b = Auxiliary channel off01b = Auxiliary channel on10b = Error Indicator or Not Used , depending on application11b = N...";
CM_ BO_ 2561212158 "Text Display";
CM_ SG_ 2561212158 TextDisplayIndex "Text Display Index: Used for overwriting consecutive bytes of a displayed string when byte 1 Text Display Instructions state is set for overwrite substring mode.  When used, this byte declares where in the text string that the new text will start ove...";
CM_ SG_ 2561212158 TextDisplayInstructions "Text Display Instructions: This parameter describes the status for the display how to show the information.0000b = Clear display - The displayed information should be deleted or not displayed any more.0001b = Hold display - The presently displayed in...";
CM_ BO_ 2561277694 "Forward Lane Image Command";
CM_ SG_ 2561277694 CurrentRegion "Current Region: Command sent to forward imager which specifies the operator's desired region to assist with object recognition.Message shall use the 2-character string country codes in ISO 3166-1 alpha-2.Typical examples from ISO 3166-1 alpha-2 are:F...";
CM_ SG_ 2561277694 CurrentSubRegion "Current Sub-Region: Command sent to all Forward Imager which specifies the operator's desired sub-region to assist with object recognition.This signal will be dependent on Current Region and shall use the 3-character string subdivision codes in ISO 3...";
CM_ SG_ 2561277694 LnDprtrWrnngEnlCmmnd "Lane Departure Warning Enable Command: Command to enable/disable Lane Departure Indication00b = Disable Lane Departure Warning01b = Enable Lane Departure Warning10b = Reserved11b = Don't care";
CM_ SG_ 2561277694 LaneKeepingAssistEnableCommand "Lane Keeping Assist Enable Command: Command to enable/disable lane keeping assist system.00b = Disable lane keeping assist01b = Enable lane keeping assist10b = Reserved11b = Don't care";
CM_ SG_ 2561277694 LaneCenteringEnableCommand "Lane Centering Enable Command: Command to enable/disable lane centering system.00b = Disable lane centering01b = Enable lane centering10b = Reserved11b = Don't care";
CM_ SG_ 2561277694 RqstdAtvStrngDrvrPrfrnMd "Requested Active Steering Driver Preference Mode: The requested active steering mode to the active steering system from the operators interface. This parameter is the driver's request, the state is shown in SPN 9757.000b = Requested Active Steering M...";
CM_ BO_ 2561605374 "Tire Pressure Reference Setting";
CM_ SG_ 2561605374 ReferenceTirePressureSetting "Reference Tire Pressure Setting: Reference value of the tire pressure setting as basis for the tire pressure monitoring";
CM_ SG_ 2561605374 TireLocation "Tire Location: Identifies which tire is associated with the parametric data in this PG.The low order 4 bits represent a position number, counting left to right when facing in the direction of normal vehicle travel (forward).The high order 4 bits repr...";
CM_ BO_ 2563768062 "Continuous Torque & Speed Limit Request";
CM_ SG_ 2563768062 EngnSpdLmtRqstMnmmCntns "Engine Speed Limit Request - Minimum Continuous: Requested minimum continuous engine speed";
CM_ SG_ 2563768062 EngnSpdLmtRqstMxmmCntns "Engine Speed Limit Request - Maximum Continuous: Requested maximum continuous engine speed";
CM_ SG_ 2563768062 EngnTrqLmtRqstMnmmCntns "Engine Torque Limit Request - Minimum Continuous: Requested minimum continuous engine torque (operating range: 0 to 125%)";
CM_ SG_ 2563768062 EngnTrqLmtRqstMxmmCntns "Engine Torque Limit Request - Maximum Continuous: Requested maximum continuous engine torque (operating range: 0 to 125%)";
CM_ SG_ 2563768062 MnmmCntnsRtrdrSpdLmtRqst "Minimum Continuous Retarder Speed Limit Request: Requested minimum continuous retarder speed";
CM_ SG_ 2563768062 MnmmCntnsRtrdrTrqLmtRqst "Minimum Continuous Retarder Torque Limit Request: Requested minimum continuous retarder torque (operating range: -125 to 0%)";
CM_ SG_ 2563768062 MxmmCntnsRtrdrSpdLmtRqst "Maximum Continuous Retarder Speed Limit Request: Requested maximum continuous retarder speed";
CM_ SG_ 2563768062 MxmmCntnsRtrdrTrqLmtRqst "Maximum Continuous Retarder Torque Limit Request: Requested maximum continuous retarder torque (operating range: -125 to 0%)";
CM_ BO_ 2563833598 "Cab Illumination Message";
CM_ SG_ 2563833598 IlluminationBrightnessPercent "Illumination Brightness Percent: Commanded backlight brightness level for all cab displays.  Note:  If a separate device is used to independently control the switch backlight brightness level, see SPN 5532.";
CM_ SG_ 2563833598 SwthBklghtIllmntnBrghtnssPrnt "Switch Backlight Illumination Brightness Percent: Commanded switch backlight brightness level for all operator control switches.  This is separate from the cab display illumination Brightness Percent parameter.Note:  If a single device is used to con...";
CM_ SG_ 2563833598 SwthIndtnIllmntnBrghtnssPrnt "Switch Indication Illumination Brightness Percent: Commanded switch indication illumination brightness level for all operator control switches. This is separate from the cab display illumination Brightness Percent parameter.Note: If a single device i...";
CM_ SG_ 2563833598 OprtrDsrdDsplMdCmmnd1 "Operator Desired Display Mode Command 1: The desired mode of the operator's display.  Allows the operator to select different day/night modes and broadcast desired setting to other displays in the system.  Display modes may include brightness, color,...";
CM_ SG_ 2563833598 OprtrDsrdDsplMdCmmnd2 "Operator Desired Display Mode Command 2: The desired mode of the operator's display.  Allows the operator to select different day/night modes and broadcast desired setting to other displays in the system.  Display modes may include brightness, color,...";
CM_ SG_ 2563833598 CabDomeLight1Command "Cab Dome Light 1 Command: The cab dome light 1 is the forwardmost interior light mounted on the ceiling of the cab behind the driver's shoulders.  Typically, the cab dome light 1 will illuminate when the driver's or passenger's door is open.  Cabs wi...";
CM_ SG_ 2563833598 CabDomeLight2Command "Cab Dome Light 2 Command: The cab dome light 2 is the second forwardmost interior light mounted on the ceiling of the cab behind the driver's shoulders.  Typically, the cab dome light 2 will illuminate when a rear passenger door is open.See SPN 3977 ...";
CM_ BO_ 2564161278 "Time/Date Adjust";
CM_ SG_ 2564161278 AdjustDay "Adjust day: The day component for setting the current calendar date.  This should be reported as the day component of the current date according to the calendar date standard indicated with the Local Hour Offset parameter (SPN 1602).  The calendar da...";
CM_ SG_ 2564161278 AdjustHours "Adjust hours: The hours component for setting the current time of day.  This should be reported as the hours component of the current time according to the time of day standard indicated with the Local Hour Offset parameter (SPN 1602).  The time of d...";
CM_ SG_ 2564161278 AdjustLocalHourOffset "Adjust local hour offset: The hour component for setting the offset between the UTC (Universal Time Coordinate) time and date and a the local time zone time and date.  This is the number of minutes to add to UTC, a.k.a. GMT, time and date to convert ...";
CM_ SG_ 2564161278 AdjustLocalMinuteOffset "Adjust local minute offset: The minute component for setting the offset between the UTC (Universal Time Coordinate) time and date and a the local time zone time and date.  This is the number of minutes to add to UTC, a.k.a. GMT, time and date to conv...";
CM_ SG_ 2564161278 AdjustMinutes "Adjust minutes: The minutes component for setting the current time of day.  This should be reported as the minutes component of the current time according to the time of day standard indicated with the Local Hour Offset parameter (SPN 1602).  The tim...";
CM_ SG_ 2564161278 AdjustMonth "Adjust month: The month component for setting the current calendar date.  This should be reported as the month component of the current date according to the calendar date standard indicated with the Local Hour Offset parameter (SPN 1602).  The calen...";
CM_ SG_ 2564161278 AdjustSeconds "Adjust seconds: The seconds component for setting the current time of day.  This should be reported as the seconds component of the current time according to the time of day standard indicated with the Local Hour Offset parameter (SPN 1602).  The tim...";
CM_ SG_ 2564161278 AdjustYear "Adjust year: The year component for setting the current calendar date.  This should be reported as the year component of the current date according to the calendar date standard indicated with the Local Hour Offset parameter (SPN 1602).  The calendar...";
CM_ BO_ 2564882174 "Cab Message 1";
CM_ SG_ 2564882174 AftrtrtmntRgnrtnFrSwth "Aftertreatment Regeneration Force Switch: Indicates the state of a switch available to the operator that forces aftertreatment regeneration. 00b = not active 01b = active 10b = error 11b = not available  This SP would be not active when aftertreatmen...";
CM_ SG_ 2564882174 AftrtrtmntRgnrtnInhtSwth "Aftertreatment Regeneration Inhibit Switch: Indicates the state of a switch available to the operator that inhibits aftertreatment regeneration. 00b = not active 01b = active 10b = error 11b = not available  This SP would be not active when aftertrea...";
CM_ SG_ 2564882174 AtmtGrShftngEnlSwth "Automatic Gear Shifting Enable Switch: Indicates that automated gear shifting is enabled via a switch00b = Automated Gear Shifting is disabled01b = Automated Gear Shifting is enabled10b = Error11b = Not available";
CM_ SG_ 2564882174 AuxiliaryHeaterModeRequest "Auxiliary Heater Mode Request: Request to activate the auxiliary heater.0000b = De-activate auxiliary heater0001b = Off due to ADR per European Regulations for Transport of hazardous materials0010b = Economy mode0011b = Normal mode0100b = Heater pump...";
CM_ SG_ 2564882174 AxlrHtrClntPmpRqst "Auxiliary Heater Coolant Pump Request: Indicates whether to activate the auxiliary heater coolant water pump.00b = Deactivate water pump01b = Activate water pump10b = Reserved11b = Don't care/take no action";
CM_ SG_ 2564882174 BatteryMainSwitchHoldRequest "Battery Main Switch Hold Request: Request to hold the battery main switch.00b = Release Battery Main Switch01b = Hold Battery Main Switch10b = undefined11b = Don't care/take no action";
CM_ SG_ 2564882174 CabInteriorTemperatureCommand "Cab Interior Temperature Command: Parameter used to command a certain cab interior temperature.Note: See also SPN 170.  SPN 1662 is an additional diagnostic SP associated with cab temperature.";
CM_ SG_ 2564882174 EngineFan1RequestedPercentSpeed "Engine Fan 1 Requested Percent Speed: Fan speed of the first or only fan in the system as a ratio of the actual fan drive (current speed) to the fully engaged fan drive (maximum fan speed). A two state fan (off/on) will use 0% and 100% respectively. ...";
CM_ SG_ 2564882174 EngnAtmtStrtEnlSwth "Engine Automatic Start Enable Switch: Switch signal which enables the idle management system to be enabled. When this system is enabled with the engine in an idle mode and safe operating conditions existing, then the engine may be started or stopped ...";
CM_ SG_ 2564882174 OperatorSeatDirectionSwitch "Operator Seat Direction Switch: Senses whether the operator seat is in the forward driving position00b = Operator seat not facing forward01b = Operator seat is facing forward10b = Error11b = Not Available";
CM_ SG_ 2564882174 ParkBrakeCommand "Park Brake Command: Request by a secondary device to command the Park Brake.  The Park Brake controller should treat this as a request and should apply the Park Brake as determined by the controller. Feedback of the park brake actuation may utilize S...";
CM_ SG_ 2564882174 RequestCabZoneHeating "Request Cab Zone Heating: Request to activate cab zone heating.00b = Do not heat cab engine zone01b = Heat cab zone10b = Reserved11b = Don't care/take no action";
CM_ SG_ 2564882174 RequestEngineZoneHeating "Request Engine Zone Heating: Request to activate engine zone heating.00b = Do not heat engine zone01b = Heat engine zone10b = Reserved11b = Don't care/take no action";
CM_ SG_ 2564882174 SeatBeltSwitch "Seat Belt Switch: State of switch used to determine if Seat Belt is buckled00b = NOT Buckled01b = OK - Seat Belt is buckled10b = Error - Switch state cannot be determined11b = Not Available";
CM_ SG_ 2564882174 SltdMxmmVhlSpdLmt "Selected Maximum Vehicle Speed Limit: User selected maximum vehicle speed.  If one is selected, then this SP must equal one of the maximum vehicle speeds #1-#7 from PGN 64997 - Maximum Vehicle Speed Limit Status. If different maximum vehicle speed re...";
CM_ SG_ 2564882174 VhlLmtngSpdGvrnrDrmntSwth "Vehicle Limiting Speed Governor Decrement Switch: Switch signal which decreases the Vehicle Limiting Speed Governor (VLSG).00b = Switch in the off state01b = Switch in the on state - decrease10b = Error11b = Not available";
CM_ SG_ 2564882174 VhlLmtngSpdGvrnrEnlSwth "Vehicle Limiting Speed Governor Enable Switch: Switch signal which enables the Vehicle Limiting Speed Governor (VLSG) such that the vehicle speed may be either increased or decreased when the engine is off idle.00b = Switch disabled01b = Switched ena...";
CM_ SG_ 2564882174 VhlLmtngSpdGvrnrInrmntSwth "Vehicle Limiting Speed Governor Increment Switch: Switch signal which increases the Vehicle Limiting Speed Governor (VLSG).00b = Switch in the off state01b = Switch in the on state - increase10b = Error11b = Not available";
CM_ BO_ 2565865982 "Electronic Brake Controller 1";
CM_ SG_ 2565865982 AbsFullyOperational "ABS Fully Operational: Signal which indicates whether an ABS system is fully operational or whether its functionality is reduced by a defect or by an intended action (e.g., by activation of an ABS-off-road switch or during special diagnostic procedur...";
CM_ SG_ 2565865982 AbsOffRoadSwitch "ABS Off-road Switch: Switch signal which indicates the position of the ABS off-road switch.00b = ABS off-road switch passive01b = ABS off-road switch active10b = Error11b = Not available";
CM_ SG_ 2565865982 AcceleratorInterlockSwitch "Accelerator Interlock Switch: Switch signal used to disable the accelerator and remote accelerator inputs, causing the engine to return to idle.00b = Off01b = On10b = Error11b = Not available";
CM_ SG_ 2565865982 AntiLockBrakingAbsActive "Anti-Lock Braking (ABS) Active: State signal which indicates that the ABS is active.  The signal is set active when wheel brake pressure actually starts to be modulated by ABS and is reset to passive when all wheels are in a stable condition for a ce...";
CM_ SG_ 2565865982 AsrBrakeControlActive "ASR Brake Control Active: State signal which indicates that ASR brake control is active. Active means that ASR actually controls wheel brake pressure at one or more wheels of the driven axle(s).00b = ASR brake control passive but installed01b = ASR b...";
CM_ SG_ 2565865982 AsrEngineControlActive "ASR Engine Control Active: State signal which indicates that ASR engine control has been commanded to be active. Active means that ASR actually tries to control the engine. This state signal is independent of other control commands to the engine (e.g...";
CM_ SG_ 2565865982 AsrHillHolderSwitch "ASR Hill Holder Switch: Switch signal which indicates the position of the ASR hill holder switch.00b = ASR hill holder switch passive01b = ASR hill holder switch active10b = Error11b = Not available";
CM_ SG_ 2565865982 AsrOffRoadSwitch "ASR Off-road Switch: Switch signal which indicates the position of the ASR off-road switch.00b = ASR off-road switch passive01b = ASR off-road switch active10b = Error11b = Not available";
CM_ SG_ 2565865982 AtcAsrInformationSignal "ATC/ASR Information Signal: This parameter commands the ATC/ASR driver information signal, for example a dash lamp.00b = Off01b = On 10b = Reserved11b = Take no action";
CM_ SG_ 2565865982 BrakePedalPosition "Brake Pedal Position: Ratio of brake pedal position to maximum pedal position.  Used for electric brake applications. 0% means no braking. Also when there are two brake pedals on the machine (Left Brake Pedal Position SPN 3033 and Right Brake Pedal P...";
CM_ SG_ 2565865982 EbsBrakeSwitch "EBS Brake Switch: Switch signal which indicates that the brake pedal is being pressed.  The EBS brake switch is independent of the brake light switch and has no provisions for external connections.00b = Brake pedal is not being pressed01b = Brake ped...";
CM_ SG_ 2565865982 EbsRedWarningSignal "EBS Red Warning Signal: This parameter commands the EBS red optical warning signal00b = Off01b = On10b = Reserved11b = Take no action";
CM_ SG_ 2565865982 EngineAuxiliaryShutdownSwitch "Engine Auxiliary Shutdown Switch: Switch signal which requests that all engine fueling stop.00b = Off01b = On10b = Error11b = Not available";
CM_ SG_ 2565865982 EngineDerateSwitch "Engine Derate Switch: Switch signal used to activate the torque limiting feature of the engine.  The specific nature of torque limiting should be verified with the manufacturer.00b = Off01b = On10b = Error11b = Not available";
CM_ SG_ 2565865982 EngineRetarderSelection "Engine Retarder Selection: The position of the operator controlled selector, expressed as a percentage and determined by the ratio of the current position of the selector to its maximum possible position. Zero percent means no braking torque is reque...";
CM_ SG_ 2565865982 HaltBrakeSwitch "Halt brake switch: Switch signal which indicates the position of the halt brake switch.00b = Halt brake switch passive01b = Halt brake switch active10b = Error11b = Not available";
CM_ SG_ 2565865982 RailroadModeSwitch "Railroad Mode Switch: Switch signal which indicates the position of the Railroad mode switch.00b = Railroad mode switch passive (City/Highway mode)01b = Railroad mode switch active (Railroad mode)10b = Error11b = Not availableNote:  This switch signa...";
CM_ SG_ 2565865982 RemoteAcceleratorEnableSwitch "Remote Accelerator Enable Switch: Switch signal which indicates that the remote accelerator has been enabled and controls the engine.  00b = Off01b = On10b = Error11b = Not availableNOTE-The accelerator interlock switch (see SPN 972) must be disabled...";
CM_ SG_ 2565865982 TractionControlOverrideSwitch "Traction Control Override Switch: Switch signal which indicates the position of the traction control override switch.  The traction control override signal disables the automatic traction control function allowing the wheels to spin.00b = Off01b = On...";
CM_ SG_ 2565865982 TrailerAbsStatus "Trailer ABS Status: State signal which indicates that ABS in the trailer is actively controlling the brakes.  A message is sent to the tractor from the trailer (i.e. by PLC). The receiving device in the tractor transfers this information to the J1939...";
CM_ SG_ 2565865982 AsEsAmrWrnngSgnlPwrdVhl "ABS/EBS Amber Warning Signal (Powered Vehicle): This parameter commands the ABS/EBS amber/yellow optical warning signal00b = Off01b = On10b = Reserved11b = Take no action";
CM_ SG_ 2565865982 SrAddrssOfCntrllngDvFrBrkCntrl "Source Address of Controlling Device for Brake Control: The source address of the SAE J1939 device currently controlling the brake system. Its value may be the source address of the ECU transmitting the message (which means that no external SAE J1939...";
CM_ SG_ 2565865982 TrtrMntdTrlrAsWrnngSgnl "Tractor-Mounted Trailer ABS Warning Signal: This parameter commands the tractor-mounted trailer ABS optical warning signal.00b = Off01b = On 10b = Reserved11b = Take no action";
CM_ BO_ 2565867006 "Electronic Transmission Controller 2";
CM_ SG_ 2565867006 TransmissionActualGearRatio "Transmission Actual Gear Ratio: Actual ratio of input shaft speed to output shaft speed.";
CM_ SG_ 2565867006 TransmissionCurrentGear "Transmission Current Gear: The gear currently engaged in the transmission or the last gear engaged while the transmission is in the process of shifting to the new or selected gear.  Transitions toward a destination gear will not be indicated.  Once t...";
CM_ SG_ 2565867006 TransmissionCurrentRange "Transmission Current Range: Range currently being commanded by the transmission control system. Characters may include P, Rx, Rx-1...R2, R1, R, Nx, Nx-1...N2, N1, N, D, D1, D2..., Dx, L, L1, L2..., Lx-1, 1, 2, 3,... If only one displayed character is...";
CM_ SG_ 2565867006 TransmissionRequestedRange "Transmission Requested Range: Range selected by the operator.  Characters may include P, Rx, Rx-1...R2, R1, R, Nx, Nx-1...N2, N1, N, D, D1, D2..., Dx, L, L1, L2..., Lx-1, 1, 2, 3,...  If only one displayed character is required, the second character ...";
CM_ SG_ 2565867006 TransmissionSelectedGear "Transmission Selected Gear: The gear that the transmission will attempt to achieve during the current shift if a shift is in progress, or the next shift if one is pending (i.e., waiting for torque reduction to initiate the shift).Negative values are ...";
CM_ BO_ 2565867262 "Electronic Axle Controller 1";
CM_ SG_ 2565867262 DffrntlLkSttCntrlFrnt "Differential Lock State - Central Front: State used which indicates the condition of the central front differential lock.  The differential locks are located as defined in figure SPN564_A.00b = Differential lock disengaged01b = Differential lock enga...";
CM_ SG_ 2565867262 DffrntlLkSttCntrlRr "Differential Lock State - Central Rear: State used which indicates the condition of the central rear differential lock.  The differential locks are located as defined in figure SPN564_A.00b = Differential lock disengaged01b = Differential lock engage...";
CM_ SG_ 2565867262 DifferentialLockStateCentral "Differential Lock State - Central: State used which indicates the condition of the central differential lock.  The differential locks are located as defined in attached figure SPN564_A.00b = Differential lock disengaged01b = Differential lock engaged...";
CM_ SG_ 2565867262 DifferentialLockStateFrontAxle1 "Differential Lock State - Front Axle 1: State used which indicates the condition of the front axle 1 differential lock.  The differential locks are located as defined in figure SPN564_A.00b = Differential lock disengaged01b = Differential lock engage...";
CM_ SG_ 2565867262 DifferentialLockStateFrontAxle2 "Differential Lock State - Front Axle 2: State used which indicates the condition of the front axle 2 differential lock. The differential locks are located as defined in figure SPN 564_A.00b = Differential lock disengaged01b = Differential lock engage...";
CM_ SG_ 2565867262 DifferentialLockStateRearAxle1 "Differential Lock State - Rear Axle 1: State used which indicates the condition of the rear axle 1 differential lock.  The differential locks are located as defined in figure SPN 564_A.00b = Differential lock disengaged01b = Differential lock engaged...";
CM_ SG_ 2565867262 DifferentialLockStateRearAxle2 "Differential Lock State - Rear Axle 2: State used which indicates the condition of the rear axle 2 differential lock.  The differential locks are located as defined in figure SPN 564_A.00b = Differential lock disengaged01b = Differential lock engaged...";
CM_ SG_ 2565867262 DifferentialLockStateRearAxle3 "Differential Lock State - Rear Axle 3: State used which indicates the condition of the rear axle 3 differential lock. The differential locks are located as defined in figure SPN 564_A.00b = Differential lock disengaged01b = Differential lock engaged1...";
CM_ SG_ 2565867262 FrontAxleGroupEngagementStatus "Front axle group engagement status: Front axle group engagement status 00b = front axle group disengaged 01b = front axle group engaged10b = error11b = not available";
CM_ SG_ 2565867262 Location "Location: To identify to which of several similar devices (such as tires or fuel tanks) the information applies.The low order 4 bits represent a position number, counting left to right when facing in the direction of normal vehicle travel (forward).T...";
CM_ SG_ 2565867262 RearAxleGroupEngagementStatus "Rear axle group engagement status: Rear axle group engagement status00b = rear axle group disengaged 01b = rear axle group engaged10b = error11b = not available";
CM_ SG_ 2565867262 DogClutchRearAxle2 "Dog Clutch Rear Axle 2: Status of the Dog Clutch Rear Axle 2.00b = Dog Clutch Rear Axle 2 Disengaged01b = Dog Clutch Rear Axle 2 Engaged10b = Error11b = Not Available";
CM_ BO_ 2565867774 "Hydraulic Pressure Governor Info";
CM_ SG_ 2565867774 EngnHdrlPrssrGvrnrMdIndtr "Engine Hydraulic Pressure Governor Mode Indicator: Mode for governor operation is hydraulic pressure control.00b = Disabled01b = Enabled10b = Error Indicator11b = Not Available";
CM_ SG_ 2565867774 EngnHdrlPrssrGvrnrSwth "Engine Hydraulic Pressure Governor Switch: Switch that sets the  mode of hydraulic governor00b = Pressure Mode Inactive01b = Pressure Mode Active10b = Error Indicator11b = Not Available";
CM_ SG_ 2565867774 FireApparatusPumpEngagement "Fire Apparatus Pump Engagement: The measured status of the pump used to provide water in fire fighting apparatus for distribution of water through water cannons or fire hoses.00b = Pump not engaged01b = Pump engaged10b = Error11b = Not available or n...";
CM_ SG_ 2565867774 FrApprtsOkTPmpIntrlk "Fire Apparatus Okay To Pump Interlock: The measured state of the Okay To Pump interlock of the fire apparatus.00b = Okay to Pump Interlock Inactive01b = Okay to Pump Interlock Active10b = Error11b = Not AvailableNote: Okay to Pump is incorporated int...";
CM_ SG_ 2565867774 HdrlDshrgPrssrStPnt "Hydraulic Discharge Pressure Set Point: Hydraulic pressure governing system discharge pressure set point.";
CM_ SG_ 2565867774 HdrlPrssrGvrnrDrsSwth "Hydraulic Pressure Governor Decrease Switch: Switch that commands hydraulic pressure governor to decrease engine rpm resulting in expected decrease of hydraulic discharge pressure.00b = Decrease Switch Inactive01b = Decrease Switch Active10b = Error1...";
CM_ SG_ 2565867774 HdrlPrssrGvrnrIdlSwth "Hydraulic Pressure Governor Idle Switch: Switch that commands hydraulic pressure governor to decrease engine rpm to its idle position.00b = Idle Switch Inactive01b = Idle Switch Active10b = Error11b = Not available";
CM_ SG_ 2565867774 HdrlPrssrGvrnrInrsSwth "Hydraulic Pressure Governor Increase Switch: Switch that commands hydraulic pressure governor to increase engine rpm resulting in expected increase of hydraulic discharge pressure.00b = Increase Switch Inactive01b = Increase Switch Active10b = Error1...";
CM_ SG_ 2565867774 HdrlPrssrGvrnrPrstSwth "Hydraulic Pressure Governor Preset Switch: Switch that commands hydraulic pressure governor to increase or decrease engine rpm to achieve a predefined discharge pressure.00b = Preset Switch Inactive01b = Preset Switch Active10b = Error11b = Not avail...";
CM_ SG_ 2565867774 HydraulicIntakePressure "Hydraulic Intake Pressure: Hydraulic pressure measured at the intake of the hydraulic pump.";
CM_ SG_ 2565867774 HydraulicPressure "Hydraulic Pressure: Hydraulic pressure measured at the output of the hydraulic pump.";
CM_ BO_ 2565868030 "Vehicle Dynamic Stability Control 2";
CM_ SG_ 2565868030 LateralAcceleration "Lateral Acceleration: Indicates a lateral acceleration of the vehicle (the component of vehicle acceleration vector along the Y-axis). A positive lateral acceleration signal results when the vehicle is accelerated to the left.  This parameter is defi...";
CM_ SG_ 2565868030 LongitudinalAcceleration "Longitudinal Acceleration: Indicates the longitudinal acceleration of the vehicle. A positive longitudinal acceleration signal results when the vehicle speed increases, regardless of driving the vehicle forward or backward.  This parameter is applica...";
CM_ SG_ 2565868030 SteeringWheelAngle "Steering Wheel Angle: The main operator`s steering wheel angle (on the steering column, not the actual wheel angle).  The vehicle being steered to the left (counterclockwise) results in a positive steering wheel angle.  This is the yaw angle of the s...";
CM_ SG_ 2565868030 SteeringWheelAngleSensorType "Steering Wheel Angle Sensor Type: Indicates whether the steering wheel angle sensor is capable of absolute measuring of the number of steering wheel turns or not (relative measuring to position at ignition on).00b = Relative measuring principle01b = ...";
CM_ SG_ 2565868030 SteeringWheelTurnCounter "Steering Wheel Turn Counter: Indicates number of steering wheel turns, absolute position or relative position at ignition on. Positive values indicate left turns.";
CM_ SG_ 2565868030 YawRate "Yaw Rate: Indicates the rate of rotation about the vertical axis (i.e. the z-axis).  A positive yaw rate signal results when the vehicle turns counter-clockwise.   This parameter is defined according to a Z-Up axis system and the sign of the value is...";
CM_ BO_ 2565868542 "Electronic Steering Control";
CM_ SG_ 2565868542 ActualInnerWheelSteeringAngle "Actual Inner wheel steering angle: Signal which indicates the actual inner wheel steering angle.  The steering angle is the angle of wheel turn relative to the vehicle x-axis (yaw angle of inner wheel). See Figure SPN2927_A for explanation of positiv...";
CM_ SG_ 2565868542 AxleLocation "Axle Location: To identify to which of several similar devices (such as tires or fuel tanks) the information applies.The low order 4 bits represent a position number, counting left to right when facing in the direction of normal vehicle travel (forwa...";
CM_ SG_ 2565868542 StatusOfSteeringAxle "Status of Steering Axle: A signal which indicates different states of the steering axle0000b = Axle steering not active (adhesion steering)0001b = Axle steering active0010b = Axle centered0011b = Axle centered, because of an error0100b = Axle not act...";
CM_ SG_ 2565868542 SteeringType "Steering Type: Indicates the different types of steering systems (ref. ECE Regulation 79 paragraph 2.5)0000b = Main steering system0001b = Auxiliary steering equipment0010b to 1110b = Reserved for Assignment by SAE1111b = Not Available0000b    Main s...";
CM_ SG_ 2565868542 StrlLftAxlLwrngInht "Steerable Lift Axle Lowering Inhibit: A signal which indicates if lowering of lifted axle is allowed or inhibited.00b = Lowering allowed01b = Lowering inhibited10b = Reserved11b = Not available";
CM_ SG_ 2565868542 TypeOfSteeringForces "Type of Steering Forces: Type of Steering Forces (Ref. ECE Regulation 79 paragraph 2.5)0000b = Manual steering equipment0001b = Power assisted steering equipment0010b = Full power steering equipment0011b = Self tracking steering equipment0100b to 111...";
CM_ SG_ 2565868542 TypeOfSteeringTransmission "Type of Steering Transmission: Type of Steering Transmission (Ref. ECE Regulation 79 paragraph 2.6)0000b = Purely mechanical steering transmission0001b = Purely hydraulic steering transmission0010b = Purely electric steering transmission0011b = Hybri...";
CM_ BO_ 2565869310 "Aftertreatment 1 Intake Gas 1";
CM_ SG_ 2565869310 EngineExhaust1Nox1 "Engine Exhaust 1 NOx 1: The amount of combined NO and NO2 in the exhaust, represented in NOx molecule parts per million non-NOx molecules, in exhaust bank 1.  This sensor is located at the intake of the SCR system if an SCR system exists. SPN 3216 sh...";
CM_ SG_ 2565869310 EngineExhaust1Nox1ReadingStable "Engine Exhaust 1 NOx 1 Reading Stable: Indicates that the NOx reading of the first NOx sensor is stable as determined by the manufacturer's control software in exhaust bank 1.  This sensor is located at the intake of the SCR system if an SCR system e...";
CM_ SG_ 2565869310 EngineExhaust1PercentOxygen1 "Engine Exhaust 1 Percent Oxygen 1: The actual oxidation factor (Percent Oxygen) of the gas within the exhaust stream. For positive values, the parameter represents the percent oxygen in excess of the amount required for stoichiometric combustion. For...";
CM_ SG_ 2565869310 EngnExhst1GsSnsr1PwrInRng "Engine Exhaust 1 Gas Sensor 1 Power In Range: Indicates that the power supplied to the aftertreatment intake gas sensor, either NOx or O2, is within the manufacturer's specification in exhaust bank 1.  This parameter reports the status as reported by...";
CM_ SG_ 2565869310 EngnExhst1NxSnsr1PrlmnrFm "Engine Exhaust 1 NOx Sensor 1 Preliminary FMI: Used to identify the applicable J1939-73 FMI detected in the first NOx sensor by the manufacturer's sensor control software in exhaust bank 1.  This sensor is located at the intake of the SCR system if a...";
CM_ SG_ 2565869310 EngnExhst1NxSnsr1SlfDgnssStts "Engine Exhaust 1 NOx Sensor 1 Self-diagnosis Status: Self-diagnosis result status for the first NOx sensor in Engine Exhaust Bank 1 (EEB1).  This sensor is located at the intake of the aftertreatment system if an aftertreatment system exists.000b = D...";
CM_ SG_ 2565869310 EngnExhst1GsSnsr1AtTmprtr "Engine Exhaust 1 Gas Sensor 1 at Temperature: Indicates that the heater element of the gas sensor, either NOx or O2, is within the manufacturer's specified range for accurate measurements in exhaust bank 1.   This sensor is located at the engine exha...";
CM_ SG_ 2565869310 EngnExhst1WdRngPrntOxgn1RdngStl "Engine Exhaust 1 Wide-Range Percent Oxygen 1 Reading Stable: Indicates that the percent oxygen reading of the gas sensor, either NOx or O2, is stable as determined by the manufacturer's control software in exhaust bank 1.  This sensor is located at t...";
CM_ SG_ 2565869310 EngnExhst1GsSnsr1HtrPrlmnrFm "Engine Exhaust 1 Gas Sensor 1 Heater Preliminary FMI: Used to identify the applicable J1939-73 FMI detected in the heater of the exhaust gas sensor, either NOx or O2, by the manufacturer's sensor control software in exhaust bank 1.  In the case of mu...";
CM_ SG_ 2565869310 EngnExhst1GsSnsr1HtrCntrl "Engine Exhaust 1 Gas Sensor 1 Heater Control: Indicates the heater status in the warm-up process.  Upon receiving a power-up command, the gas sensor ramps up according to a manufacturer defined profile.  The Preheat 1, Preheat 2, and Automatic messag...";
CM_ SG_ 2565869310 EngnExhst1OxgnSnsr1PrlmnrFm "Engine Exhaust 1 Oxygen  Sensor 1 Preliminary FMI: Used to identify the applicable J1939-73 FMI detected in the oxygen sensor by the manufacturer's sensor control software in exhaust bank 1.  In the case of multiple failures the most severe is commun...";
CM_ BO_ 2565869566 "Aftertreatment 1 Outlet Gas 1";
CM_ SG_ 2565869566 Aftertreatment1OutletNox1 "Aftertreatment 1 Outlet NOx 1: The amount of combined NO and NO2 in the exhaust exiting the aftertreatment system measured by a NOx sensor at the aftertreatment outlet, represented in NOx molecule parts per million non-NOx molecules in exhaust bank 1...";
CM_ SG_ 2565869566 Aftrtrtmnt1OtltGsSnsr1HtrCntrl "Aftertreatment 1 Outlet Gas Sensor 1 Heater Control: Indicates the heater status in the warm-up process.  Upon receiving a power-up command, the gas sensor ramps up according to a manufacturer defined profile.  The Preheat 1, Preheat 2, and Automatic...";
CM_ SG_ 2565869566 Aftrtrtmnt1OtltGsSnsr1PwrInRng "Aftertreatment 1 Outlet Gas Sensor 1 Power In Range: Indicates that the power supplied to the aftertreatment outlet gas sensor, either NOx or O2, is within the manufacturer's specification in exhaust bank 1. This parameter reports the status as repor...";
CM_ SG_ 2565869566 Aftrtrtmnt1OtltPrntOxgn1 "Aftertreatment 1 Outlet Percent Oxygen 1: The actual oxidation factor (percent oxygen) of the gas within the exhaust stream.  For positive values, the parameter represents the percent oxygen in excess of the amount required for stoichiometric combust...";
CM_ SG_ 2565869566 Atttt1OttWdRPtOx1RdSt "Aftertreatment 1 Outlet Wide-Range Percent Oxygen 1 Reading Stable: Indicates that the percent oxygen reading of the aftertreatment outlet gas sensor, either NOx or O2, is stable as determined by the manufacturer's control software in exhaust bank 1....";
CM_ SG_ 2565869566 Aftrtrtmnt1OtltGsSnsr1AtTmprtr "Aftertreatment 1 Outlet Gas Sensor 1 at Temperature: Indicates that the heater element of the aftertreatment outlet gas sensor, either NOx or O2, is within the manufacturer's specified range for accurate measurements in exhaust bank 1.00b = Not in ra...";
CM_ SG_ 2565869566 Aftrtrtmnt1OtltNx1RdngStl "Aftertreatment 1 Outlet NOx 1 Reading Stable: Indicates that the NOx reading of the aftertreatment outlet NOx sensor is stable as determined by the manufacturer's control software in exhaust bank 1.00b = Not stable01b = Stable10b = Error11b = Not ava...";
CM_ SG_ 2565869566 Atttt1OttGsSs1HtPF "Aftertreatment 1 Outlet Gas Sensor 1 Heater Preliminary FMI: Used to identify the applicable J1939-73 FMI detected in the heater of the outlet exhaust gas sensor, either NOx or O2, by the manufacturer's sensor control software in exhaust bank 1.  In ...";
CM_ SG_ 2565869566 Aftrtrtmnt1OtltNxSnsr1PrlmnrFm "Aftertreatment 1 Outlet NOx Sensor 1 Preliminary FMI: Used to identify the applicable J1939-73 FMI detected in the aftertreatment outlet NOx sensor by the manufacturer's sensor control software in exhaust bank 1.  In the case of multiple failures the...";
CM_ SG_ 2565869566 Atttt1OttNxSs1SDssStts "Aftertreatment 1 Outlet NOx Sensor 1 Self-diagnosis Status: Self-diagnosis result status for NOx sensor ATO1 (Aftertreatment Outlet Bank 1)000b = Diagnosis not active001b = NOx Sensor ATO1 Self-diagnosis active flag010b = NOx Sensor ATO1 Self-diagnos...";
CM_ SG_ 2565869566 Atttt1OttOxSs1PF "Aftertreatment 1 Outlet Oxygen Sensor 1 Preliminary FMI: Used to identify the applicable J1939-73 FMI detected in the aftertreatment outlet oxygen sensor by the manufacturer's sensor control software in exhaust bank 1.  In the case of multiple failur...";
CM_ BO_ 2565869822 "Aftertreatment 2 Intake Gas 1";
CM_ SG_ 2565869822 EngineExhaust2Nox1 "Engine Exhaust 2 NOx 1: The amount of combined NO and NO2 in the exhaust, represented in NOx molecule parts per million non-NOx molecules, in exhaust bank 2.  This sensor is located at the intake of the SCR system if an SCR system exists.For a single...";
CM_ SG_ 2565869822 EngineExhaust2Nox1ReadingStable "Engine Exhaust 2 NOx 1 Reading Stable: Indicates that the NOx reading of the first NOx sensor is stable as determined by the manufacturer's control software in exhaust bank 2.  This sensor is located at the intake of the SCR system if an SCR system e...";
CM_ SG_ 2565869822 EngineExhaust2PercentOxygen1 "Engine Exhaust 2 Percent Oxygen 1: The actual oxidation factor (percent oxygen) of the gas within the exhaust stream.  For positive values, the parameter represents the percent oxygen in excess of the amount required for stoichiometric combustion.  F...";
CM_ SG_ 2565869822 EngnExhst2GsSnsr1PwrInRng "Engine Exhaust 2 Gas Sensor 1 Power In Range: Indicates that the power supplied to the intake gas sensor, either NOx or O2, is within the manufacturer's specification in exhaust bank 2. This parameter reports the status as reported by the sensor. Thi...";
CM_ SG_ 2565869822 EngnExhst2GsSnsr2PwrSppl "Engine Exhaust 2 Gas Sensor 2 Power Supply: State signal which indicates when the Engine Exhaust 2 Intake 2 Gas Sensor driver output is being driven.  On means the ECU is powering the Engine Exhaust 2 Intake 2 Gas Sensor.  Note that the ECU is extern...";
CM_ SG_ 2565869822 EngnExhst2NxSnsr1PrlmnrFm "Engine Exhaust 2 NOx Sensor 1 Preliminary FMI: Used to identify the applicable J1939-73 FMI detected in the NOx sensor by the manufacturer's sensor control software in exhaust bank 2.  This sensor is located at the intake of the SCR system if an SCR ...";
CM_ SG_ 2565869822 EngnExhst2NxSnsr1SlfDgnssStts "Engine Exhaust 2 NOx Sensor 1 Self-diagnosis Status: Self-diagnosis result status for NOx sensor Engine Exhaust Bank 2 (EEB2).  This sensor is located at the intake of the aftertreatment system if an aftertreatment system exists.000b = Diagnosis not ...";
CM_ SG_ 2565869822 EngnExhst2GsSnsr1AtTmprtr "Engine Exhaust 2 Gas Sensor 1 at Temperature: Indicates that the heater element of the gas sensor, either NOx or O2, is within the manufacturer's specified range for accurate measurements in exhaust bank 2.  This sensor is located at the engine exhau...";
CM_ SG_ 2565869822 EngnExhst2WdRngPrntOxgn1RdngStl "Engine Exhaust 2 Wide-Range Percent Oxygen 1 Reading Stable: Indicates that the percent oxygen reading of the gas sensor, either NOx or O2, is stable as determined by the manufacturer's control software in exhaust bank 2.This sensor is located at the...";
CM_ SG_ 2565869822 EngnExhst2GsSnsr1HtrPrlmnrFm "Engine Exhaust 2 Gas Sensor 1 Heater Preliminary FMI: Used to identify the applicable J1939-73 FMI detected in the heater of the exhaust gas sensor, either NOx or O2, by the manufacturer's sensor control software in exhaust bank 2.  In the case of mu...";
CM_ SG_ 2565869822 EngnExhst2GsSnsr1HtrCntrl "Engine Exhaust 2 Gas Sensor 1 Heater Control: Indicates the heater status in the warm-up process.  Upon receiving a power-up command, the gas sensor ramps up according to a manufacturer defined profile.  The Preheat 1, Preheat 2, and Automatic messag...";
CM_ SG_ 2565869822 EngnExhst2OxgnSnsr1PrlmnrFm "Engine Exhaust 2 Oxygen Sensor 1 Preliminary FMI: Used to identify the applicable J1939-73 FMI detected in the  oxygen sensor by the manufacturer's sensor control software in exhaust bank 2.  In the case of multiple failures the most severe is commun...";
CM_ BO_ 2565870078 "Aftertreatment 2 Outlet Gas 1";
CM_ SG_ 2565870078 Aftertreatment2OutletNox1 "Aftertreatment 2 Outlet NOx 1: The amount of combined NO and NO2 in the exhaust entering the aftertreatment system measured by a NOx sensor at the aftertreatment outlet, represented in NOx molecule parts per million non-NOx molecules in exhaust bank ...";
CM_ SG_ 2565870078 Aftrtrtmnt2Otlt2GsSnsrPwrSppl "Aftertreatment 2 Outlet 2 Gas Sensor Power Supply: State signal which indicates when the Aftertreatment 2 Outlet 2 Gas Sensor driver output is being driven.  On means the ECU is powering the Aftertreatment 2 Outlet 2 Gas Sensor.  Note that the ECU is...";
CM_ SG_ 2565870078 Aftrtrtmnt2OtltGsSnsr1HtrCntrl "Aftertreatment 2 Outlet Gas Sensor 1 Heater Control: Indicates the heater status in the warm-up process.  Upon receiving a power-up command, the gas sensor ramps up according to a manufacturer defined profile.  The Preheat 1, Preheat 2, and Automatic...";
CM_ SG_ 2565870078 Aftrtrtmnt2OtltGsSnsr1PwrInRng "Aftertreatment 2 Outlet Gas Sensor 1 Power In Range:  Indicates that the power supplied to the aftertreatment outlet gas sensor, either NOx or O2, is within the manufacturer's specification in exhaust bank 2.For a single exhaust bank system, refer to...";
CM_ SG_ 2565870078 Aftrtrtmnt2OtltPrntOxgn1 "Aftertreatment 2 Outlet Percent Oxygen 1: The actual oxidation factor (percent oxygen) of the gas within the exhaust stream.  For positive values, the parameter represents the percent oxygen in excess of the amount required for stoichiometric combust...";
CM_ SG_ 2565870078 Atttt2OttWdRPtOx1RdSt "Aftertreatment 2 Outlet Wide-Range Percent Oxygen 1 Reading Stable: Indicates that the percent oxygen reading of the aftertreatment outlet gas sensor, either NOx or O2, is stable as determined by the manufacturer's control software in exhaust bank 2....";
CM_ SG_ 2565870078 Aftrtrtmnt2OtltGsSnsr1AtTmprtr "Aftertreatment 2 Outlet Gas Sensor 1 at Temperature: Indicates that the heater element of the aftertreatment outlet gas sensor, either NOx or O2, is within the manufacturer's specified range for accurate measurements in exhaust bank 2.For a single ex...";
CM_ SG_ 2565870078 Aftrtrtmnt2OtltNx1RdngStl "Aftertreatment 2 Outlet NOx 1 Reading Stable: Indicates that the NOx reading of the aftertreatment outlet NOx sensor is stable as determined by the manufacturer's control software in exhaust bank 2.For a single exhaust bank system, refer to parameter...";
CM_ SG_ 2565870078 Atttt2OttGsSs1HtPF "Aftertreatment 2 Outlet Gas Sensor 1 Heater Preliminary FMI: Used to identify the applicable J1939-73 FMI detected in the heater of the outlet exhaust gas sensor, either NOx or O2, by the manufacturer's sensor control software in exhaust bank 2.  In ...";
CM_ SG_ 2565870078 Aftrtrtmnt2OtltNxSnsr1PrlmnrFm "Aftertreatment 2 Outlet NOx Sensor 1 Preliminary FMI: Used to identify the applicable J1939-73 FMI detected in the aftertreatment outlet NOx sensor by the manufacturer's sensor control software in exhaust bank 2.  In the case of multiple failures the...";
CM_ SG_ 2565870078 Atttt2OttNxSs1SDssStts "Aftertreatment 2 Outlet NOx Sensor 1 Self-diagnosis Status: Self-diagnosis result status for NOx sensor ATO2 (Aftertreatment Outlet Bank 2)000b = Diagnosis not active001b = NOx Sensor ATO2 Self-diagnosis active flag010b = NOx Sensor ATO2 Self-diagnos...";
CM_ SG_ 2565870078 Atttt2OttOxSs1PF "Aftertreatment 2 Outlet Oxygen Sensor 1 Preliminary FMI: Used to identify the applicable J1939-73 FMI detected in the aftertreatment outlet oxygen sensor by the manufacturer's sensor control software in exhaust bank 2.  In the case of multiple failur...";
CM_ BO_ 2565870334 "Fifth Wheel Smart Systems 1";
CM_ SG_ 2565870334 FifthWheelDrawbarForce "Fifth Wheel Drawbar Force: Fifth wheel drawbar force, with the trailer held stationary a positive force is generated by the vehicle pulling forward.";
CM_ SG_ 2565870334 FifthWheelRollMoment "Fifth Wheel Roll Moment : Fifth wheel roll moment force - If the moment is positive, the trailer is rolling clockwise relative to the normal vehicle forward motion.";
CM_ SG_ 2565870334 FifthWheelRollWarningIndicator "Fifth Wheel Roll Warning Indicator: Indicates to the vehicle operator that the roll moment has exceeded a preset limit. 00b = Limit not exceeded01b = Limit exceeded10b = error11b = Not Available";
CM_ SG_ 2565870334 FifthWheelVerticalForce "Fifth Wheel Vertical Force: The amount of load being applied to the fifth wheel by the trailer. Zero load is indicated without a trailer.";
CM_ BO_ 2565873150 "Steering Angle Sensor Information";
CM_ SG_ 2565873150 MessageChecksum "Message Checksum: The message checksum is used to verify the signal path from the demanding device to the steering controller.  The support of this parameter is mandatory if PGN 61469 is supported as there is no means to indicate not available.The 4 ...";
CM_ SG_ 2565873150 MessageCounter "Message Counter: The message counter is to verify the signal path from the demanding device to the steering controller.  The support of this parameter is mandatory.Note:  The initial value of the 4 bit message counter for the first message during a d...";
CM_ SG_ 2565873150 SteeringAngleSensorActiveMode "Steering Angle Sensor Active Mode: This signal indicates the operational mode of the steering angle sensor.00b = Programming mode active01b = Normal mode active10b = Reserved11b = Not available";
CM_ SG_ 2565873150 SteeringAngleSensorCalibrated "Steering Angle Sensor Calibrated: This signal indicates the calibration status of the steering angle sensor.00b = SAS not calibrated01b = SAS calibrated10b = Reserved11b = Not available";
CM_ SG_ 2565873150 SteeringWheelAngle "Steering Wheel Angle: The main operator`s steering wheel angle (on the steering column, not the actual wheel angle). The vehicle being steered to the left (counterclockwise) results in a positive steering wheel angle.  This is the yaw angle of the st...";
CM_ SG_ 2565873150 SteeringWheelAngleRange "Steering Wheel Angle Range: The signal indicates the range of  the steering wheel angle the sensor element is capable to measure. The steering wheel angle signal ranges between the negative and the positive value of the steering wheel angle range.For...";
CM_ SG_ 2565873150 SteeringWheelAngleRangeCounter "Steering Wheel Angle Range Counter: The signal indicates the number of steering wheel angle range overflows if the operating range of steering wheel is greater than the measuring range of sensor element. Positive values indicate left turns (countercl...";
CM_ SG_ 2565873150 StrngWhlAnglRngCntrTp "Steering Wheel Angle Range Counter Type: The signal indicates whether the steering wheel angle sensor is capable of absolute measuring of the number of steering wheel angle ranges or not.  Absolute measuring means that the steering wheel angle range ...";
CM_ BO_ 2565874174 "Engine Speed Sensor Information 1";
CM_ SG_ 2565874174 EngineSpeed1 "Engine Speed 1: The engine speed as measured by speed sensor 1.Note:  This is for the engine speed from the 1st engine speed sensor.  This may be different than SPN 190 when used in multiple engine speed sensor configurations.   In an application wit...";
CM_ SG_ 2565874174 EngineSpeed2 "Engine Speed 2: The engine speed as measured by speed sensor 2Note:  This is for the engine speed from the 2nd engine speed sensor.  This may be different than SPN 190 when used in multiple engine speed sensor configurations.   In an application with...";
CM_ SG_ 2565874174 EngineSpeed3 "Engine Speed 3: The engine speed as measured by speed sensor 3.Note:  This is for the engine speed from the 3rd engine speed sensor.  This may be different than SPN 190 when used in multiple engine speed sensor configurations.   In an application wit...";
CM_ SG_ 2565874174 EngnSpdSnsr1TmngPttrnStts "Engine Speed Sensor 1 Timing Pattern Status: This is the timing pattern status of the engine speed sensor signal for sensor 1.   The sensor may be sending a speed signal but the pattern may not be valid.  Since the speed is considered valid, the erro...";
CM_ SG_ 2565874174 EngnSpdSnsr2TmngPttrnStts "Engine Speed Sensor 2 Timing Pattern Status: This is the timing pattern status of the engine speed sensor signal for sensor 2.  The sensor may be sending a speed signal but the pattern may not be valid.  Since the speed is considered valid, the error...";
CM_ SG_ 2565874174 EngnSpdSnsr3TmngPttrnStts "Engine Speed Sensor 3 Timing Pattern Status: This is the timing pattern status of the engine speed sensor signal for sensor 3.  The sensor may be sending a speed signal but the pattern may not be valid.  Since the speed is considered valid, the error...";
CM_ BO_ 2565877502 "Engine Turbocharger Control 1";
CM_ SG_ 2565877502 EExstB1PssRtCtCd "Engine Exhaust Bank 1 Pressure Regulator Control Command: The control command to the Engine Exhaust Pressure Regulator in bank 1, normalized to percent.  100 percent means the regulator is fully closed, providing the maximum restriction to exhaust ga...";
CM_ SG_ 2565877502 EngnTrhrgrWstgtAttr1Cmmnd "Engine Turbocharger Wastegate Actuator 1 Command: The command to a Turbocharger Wastegate actuator 1, normalized to percent, where 0% nominally represents fully closed (No Flow) and 100% represents fully open (Max Flow).FB00h - FB64h is sent to calib...";
CM_ SG_ 2565877502 EngnTrhrgrWstgtAttr2Cmmnd "Engine Turbocharger Wastegate Actuator 2 Command: The command to a Turbocharger Wastegate actuator 2, normalized to percent, where 0% nominally represents fully closed (No Flow) and 100% represents fully open (Max Flow).";
CM_ SG_ 2565877502 ETCpssBwAtt1Cd "Engine Turbocharger Compressor Blowoff Actuator 1 Command: The command to blow off actuator 1, normalized to percent, where 0% nominally represents fully closed (No Flow) and 100% represents fully open (Max Flow). The purpose of Blow-off value is sim...";
CM_ BO_ 2565917438 "DC/AC Accessory Inverter 1 Feedback 2";
CM_ SG_ 2565917438 DAAssrInvrtr1PwrLmtdDTDSdCrrnt "DC/AC Accessory Inverter 1 Power Limited due to DC Side Current: Output power is being limited due to DC Side input current (see SPN 8891) approaching or exceeding the maximum limit (See SPN 9226).00b = No power limit for this reason01b = Power limit...";
CM_ SG_ 2565917438 DAAssIvt1PwLtdDTASdRsCt "DC/AC Accessory Inverter 1 Power Limited due to AC Side RMS Current: AC Side Output power is being limited due to AC Side output RMS current (see SPN 9200) approaching or exceeding the maximum limit (See SPN 9228).00b = No power limit for this reason...";
CM_ SG_ 2565917438 DAAssIvt1PwLtdDTDSdVtM "DC/AC Accessory Inverter 1 Power Limited due to DC Side Voltage Minimum: Output power is being limited due to DC Side input voltage (see SPN 8890) approaching or falling below the minimum limit (SPN 9225).00b = No power limit for this reason01b = Pow...";
CM_ SG_ 2565917438 DAAssrInvrtr1FrqnCmmndBlwMnmm "DC/AC Accessory Inverter 1 Frequency Command below Minimum: Output frequency is being limited due to frequency command (see SPN 8333) approaching or falling below the minimum limit (SPN 8329).00b = No frequency limit for this reason01b = Frequency li...";
CM_ SG_ 2565917438 DAAssrInvrtr1FrqnCmmndExdsMxmm "DC/AC Accessory Inverter 1 Frequency Command exceeds Maximum: Output frequency is being limited due to frequency command (see SPN 8333) approaching or exceeding the maximum limit (SPN 8328).00b = No frequency limit for this reason01b = Frequency limi...";
CM_ SG_ 2565917438 DAAssIvt1PwLtdDTCtTpt "DC/AC Accessory Inverter 1 Power Limited due to Controller Temperature: Output power is being limited due to the controller temperature (see SPN 9204) approaching or exceeding the maximum limit.00b = No power limit for this reason01b = Power limited ...";
CM_ SG_ 2565917438 DAAssIvt1PwLtdDTEtFtTpt "DC/AC Accessory Inverter 1 Power Limited due to Electronic Filter Temperature: Output power is being limited due to electronic filter temperature (see SPN 9205) approaching or exceeding the maximum limit.00b = No power limit for this reason01b = Powe...";
CM_ SG_ 2565917438 DAAssIvt1PwLtdDTPwEtsTpt "DC/AC Accessory Inverter 1 Power Limited due to Power Electronics Temperature: Output power is being limited due to power electronics temperature (see SPN 9206) approaching or exceeding the maximum limit.00b = No power limit for this reason01b = Powe...";
CM_ SG_ 2565917438 DAAssIvt1PwLtdDTRtOCLt "DC/AC Accessory Inverter 1 Power Limited due to Rate of Change Limit: Output power is being limited due to the frequency approaching or exceeding the rate of change limit (see SPN 8332).00b = No power limit for this reason01b = Power limited for this...";
CM_ SG_ 2565917438 DAAssrInvrtr1PwrLmtdDTUndfndRsn "DC/AC Accessory Inverter 1 Power Limited due to Undefined Reason: Output power is being limited due to an undefined reason.00b = No power limit for this reason01b = Power limited for this reason10b = Error11b = Not Available";
CM_ BO_ 2565918206 "DC/AC Accessory Inverter 2 Feedback 2";
CM_ SG_ 2565918206 DAAssrInvrtr2PwrLmtdDTDSdCrrnt "DC/AC Accessory Inverter 2 Power Limited due to DC Side Current: Output power is being limited due to DC Side input current (see SPN 9238) approaching or exceeding the maximum limit (See SPN 9256).00b = No power limit for this reason01b = Power limit...";
CM_ SG_ 2565918206 DAAssIvt2PwLtdDTASdRsCt "DC/AC Accessory Inverter 2 Power Limited due to AC Side RMS Current: AC Side Output power is being limited due to AC Side output RMS current (see SPN 9201) approaching or exceeding the maximum limit (See SPN 9258).00b = No power limit for this reason...";
CM_ SG_ 2565918206 DAAssIvt2PwLtdDTDSdVtM "DC/AC Accessory Inverter 2 Power Limited due to DC Side Voltage Minimum: Output power is being limited due to DC Side input voltage (see SPN 9237) approaching or falling below the minimum limit (SPN 9255).00b = No power limit for this reason01b = Pow...";
CM_ SG_ 2565918206 DAAssrInvrtr2FrqnCmmndBlwMnmm "DC/AC Accessory Inverter 2 Frequency Command below Minimum: Output frequency is being limited due to frequency command (see SPN 8347) approaching or falling below the minimum limit (SPN 8343).00b = No frequency limit for this reason01b = Frequency li...";
CM_ SG_ 2565918206 DAAssrInvrtr2FrqnCmmndExdsMxmm "DC/AC Accessory Inverter 2 Frequency Command exceeds Maximum: Output frequency is being limited due to frequency command (see SPN 8347) approaching or exceeding the maximum limit (SPN 8342).00b = No frequency limit for this reason01b = Frequency limi...";
CM_ SG_ 2565918206 DAAssIvt2PwLtdDTCtTpt "DC/AC Accessory Inverter 2 Power Limited due to Controller Temperature: Output power is being limited due to the controller temperature (see SPN 9231) approaching or exceeding the maximum limit.00b = No power limit for this reason01b = Power limited ...";
CM_ SG_ 2565918206 DAAssIvt2PwLtdDTEtFtTpt "DC/AC Accessory Inverter 2 Power Limited due to Electronic Filter Temperature: Output power is being limited due to electronic filter temperature (see SPN 9232) approaching or exceeding the maximum limit.00b = No power limit for this reason01b = Powe...";
CM_ SG_ 2565918206 DAAssIvt2PwLtdDTPwEtsTpt "DC/AC Accessory Inverter 2 Power Limited due to Power Electronics Temperature: Output power is being limited due to power electronics temperature (see SPN 9233) approaching or exceeding the maximum limit.00b = No power limit for this reason01b = Powe...";
CM_ SG_ 2565918206 DAAssIvt2PwLtdDTRtOCLt "DC/AC Accessory Inverter 2 Power Limited due to Rate of Change Limit: Output power is being limited due to the frequency approaching or exceeding the rate of change limit (see SPN 8346).00b = No power limit for this reason01b = Power limited for this...";
CM_ SG_ 2565918206 DAAssrInvrtr2PwrLmtdDTUndfndRsn "DC/AC Accessory Inverter 2 Power Limited due to Undefined Reason: Output power is being limited due to an undefined reason.00b = No power limit for this reason01b = Power limited for this reason10b = Error11b = Not Available";
CM_ BO_ 2565920510 "DC/AC Accessory Inverter 1 Command";
CM_ SG_ 2565920510 DAAssrInvrtr1DvMxmmFrqn "DC/AC Accessory Inverter 1 Device Maximum Frequency: Signal to the DC/AC Accessory Inverter indicating the maximum frequency of the devices(s) attached to the inverter output.  Each output may control multiple devices (e.g. electric motors) if they a...";
CM_ SG_ 2565920510 DAAssrInvrtr1DvMnmmFrqn "DC/AC Accessory Inverter 1 Device Minimum Frequency: Signal to the DC/AC Accessory Inverter indicating the minimum frequency of the device(s) attached to the inverter output.  Each output may control multiple devices (e.g. electric motors) if they al...";
CM_ SG_ 2565920510 DAAssrInvrtr1DvRtdFrqn "DC/AC Accessory Inverter 1 Device Rated Frequency: Signal to the DC/AC Accessory Inverter indicating the rated frequency of the device(s) attached to the inverter output.  Each output may control multiple devices (e.g. electric motors) if they all op...";
CM_ SG_ 2565920510 DAAssrInvrtr1DvRtdRmsVltg "DC/AC Accessory Inverter 1 Device Rated RMS Voltage: Signal to the DC/AC Accessory Inverter indicating the rated RMS voltage of the device(s) attached to the inverter output.   Each output may control multiple devices (e.g. electric motors) if they a...";
CM_ SG_ 2565920510 DAAssrInvrtr1DvFrqnRtOfChngLmt "DC/AC Accessory Inverter 1 Device Frequency Rate of Change Limit: Signal to the DC/AC Accessory Inverter indicating the frequency rate of change limit of the device(s) attached to the inverter output (Note: Increasing and decreasing rates can be cont...";
CM_ SG_ 2565920510 DAAssrInvrtr1FrqnCmmnd "DC/AC Accessory Inverter 1 Frequency Command: Command to the DC/AC Accessory Inverter indicating the Inverter frequency desired for the device(s) attached to the inverter output.  Each output may control multiple devices (e.g. electric motors) if the...";
CM_ SG_ 2565920510 DAAssrInvrtr1Dv1Stts "DC/AC Accessory Inverter 1 Device 1 Status: Signal to the DC/AC Accessory Inverter indicating the state of the device attached to the inverter output.  Each output may control multiple devices (e.g. electric motors) if they all operate at the same fr...";
CM_ SG_ 2565920510 DAAssrInvrtr1Dv2Stts "DC/AC Accessory Inverter 1 Device 2 Status: Signal to the DC/AC Accessory Inverter indicating the state of the device attached to the inverter output.  Each output may control multiple devices (e.g. electric motors) if they all operate at the same fr...";
CM_ SG_ 2565920510 DAAssrInvrtr1OprtnlCmmnd "DC/AC Accessory Inverter 1 Operational Command: Command to the DC/AC Accessory Inverter to enable this output.  Each output may control multiple devices (e.g. electric motors) if they all operate at the same frequency.00b = Disable DC/AC Accessory In...";
CM_ SG_ 2565920510 DAAssIvt1ASdMtSttRsVtRqst "DC/AC Accessory Inverter 1 AC Side Motor Starting RMS Voltage Request: Signal to the DC/AC Accessory Inverter indicating the requested AC side RMS voltage for starting the attached accessory motor.   In a V/Hz variable speed motor control application...";
CM_ BO_ 2565920766 "DC/AC Accessory Inverter 1 Feedback";
CM_ SG_ 2565920766 DcAcAccessoryInverter1Frequency "DC/AC Accessory Inverter 1 Frequency: Present operating frequency of this DC/AC Accessory Inverter output.";
CM_ SG_ 2565920766 DAAssrInvrtr1ASdRmsVltg "DC/AC Accessory Inverter 1 AC Side RMS Voltage: Present operating AC Side line to line RMS voltage of this DC/AC Accessory Inverter output.  In a three phase balanced motor, this is the RMS voltage across one phase of the motor.";
CM_ SG_ 2565920766 DAAssrInvrtr1ASdPwr "DC/AC Accessory Inverter 1 AC Side Power: Present operating AC Side power of this DC/AC Accessory Inverter output.";
CM_ SG_ 2565920766 DAAssrInvrtr1ASdRmsCrrnt "DC/AC Accessory Inverter 1 AC Side RMS Current: Present operating AC Side output RMS line Current of this DC/AC Accessory Inverter.  When connected to a balanced three phase motor, this would be the current in each individual phase of the motor.";
CM_ SG_ 2565920766 DAAssrInvrtr1OprtnlStts "DC/AC Accessory Inverter 1 Operational Status: Operating Status of this DC/AC Accessory Inverter output. The Inverter Output Faulted state will be communicated when the inverter output has shutdown due to an overload condition or other fault.000b = O...";
CM_ SG_ 2565920766 DAAssrInvrtr1LdshdRqst "DC/AC Accessory Inverter 1 Loadshed Request: Loadshed Request from this DC/AC Accessory Inverter output.  The Loadshed Requested state is an indication that the inverter output powering this device has a malfunction and is in a limit condition and if...";
CM_ SG_ 2565920766 DAAssrInvrtr1HvlStts "DC/AC Accessory Inverter 1 HVIL Status: High Voltage Interlock Loop (HVIL) state of the DC/AC Accessory Inverter 1.00b = HVIL Closed01b = HVIL Open10b = Error11b = Not Available";
CM_ BO_ 2565921534 "DC/AC Accessory Inverter 2 Command";
CM_ SG_ 2565921534 DAAssrInvrtr2DvMxmmFrqn "DC/AC Accessory Inverter 2 Device Maximum Frequency: Signal to the DC/AC Accessory Inverter indicating the maximum frequency of the devices(s) attached to the inverter output.  Each output may control multiple devices (e.g. electric motors) if they a...";
CM_ SG_ 2565921534 DAAssrInvrtr2DvMnmmFrqn "DC/AC Accessory Inverter 2 Device Minimum Frequency: Signal to the DC/AC Accessory Inverter indicating the minimum frequency of the device(s) attached to the inverter output.  Each output may control multiple devices (e.g. electric motors) if they al...";
CM_ SG_ 2565921534 DAAssrInvrtr2DvRtdFrqn "DC/AC Accessory Inverter 2 Device Rated Frequency: Signal to the DC/AC Accessory Inverter indicating the rated frequency of the device(s) attached to the inverter output.  Each output may control multiple devices (e.g. electric motors) if they all op...";
CM_ SG_ 2565921534 DAAssrInvrtr2DvRtdRmsVltg "DC/AC Accessory Inverter 2 Device Rated RMS Voltage: Signal to the DC/AC Accessory Inverter indicating the rated RMS voltage of the device(s) attached to the inverter output.   Each output may control multiple devices (e.g. electric motors) if they a...";
CM_ SG_ 2565921534 DAAssrInvrtr2DvFrqnRtOfChngLmt "DC/AC Accessory Inverter 2 Device Frequency Rate of Change Limit: Signal to the DC/AC Accessory Inverter indicating the frequency rate of change limit of the device(s) attached to the inverter output (Note: Increasing and decreasing rates can be cont...";
CM_ SG_ 2565921534 DAAssrInvrtr2FrqnCmmnd "DC/AC Accessory Inverter 2 Frequency Command: Command to the DC/AC Accessory Inverter indicating the Inverter frequency desired for the device(s) attached to the inverter output.  Each output may control multiple devices (e.g. electric motors) if the...";
CM_ SG_ 2565921534 DAAssrInvrtr2Dv1Stts "DC/AC Accessory Inverter 2 Device 1 Status: Signal to the DC/AC Accessory Inverter indicating the state of the device attached to the inverter output.  Each output may control multiple devices (e.g. electric motors) if they all operate at the same fr...";
CM_ SG_ 2565921534 DAAssrInvrtr2Dv2Stts "DC/AC Accessory Inverter 2 Device 2 Status: Signal to the DC/AC Accessory Inverter indicating the state of the device attached to the inverter output.  Each output may control multiple devices (e.g. electric motors) if they all operate at the same fr...";
CM_ SG_ 2565921534 DAAssrInvrtr2OprtnlCmmnd "DC/AC Accessory Inverter 2 Operational Command: Command to the DC/AC Accessory Inverter to enable this output.  Each output may control multiple devices (e.g. electric motors) if they all operate at the same frequency.00b = Disable DC/AC Accessory In...";
CM_ SG_ 2565921534 DAAssIvt2ASdMtSttRsVtRqst "DC/AC Accessory Inverter 2 AC Side Motor Starting RMS Voltage Request: Signal to the DC/AC Accessory Inverter indicating the requested AC side RMS voltage for starting the attached accessory motor.   In a V/Hz variable speed motor control application...";
CM_ BO_ 2565921790 "DC/AC Accessory Inverter 2 Feedback";
CM_ SG_ 2565921790 DcAcAccessoryInverter2Frequency "DC/AC Accessory Inverter 2 Frequency: Present operating frequency of this DC/AC Accessory Inverter output.";
CM_ SG_ 2565921790 DAAssrInvrtr2ASdRmsVltg "DC/AC Accessory Inverter 2 AC Side RMS Voltage: Present operating AC Side line to line RMS voltage of this DC/AC Accessory Inverter output.  In a three phase balanced motor, this is the RMS voltage across one phase of the motor.";
CM_ SG_ 2565921790 DAAssrInvrtr2ASdPwr "DC/AC Accessory Inverter 2 AC Side Power: Present operating AC Side power of this DC/AC Accessory Inverter output.";
CM_ SG_ 2565921790 DAAssrInvrtr2ASdRmsCrrnt "DC/AC Accessory Inverter 2 AC Side RMS Current: Present operating AC Side output RMS line Current of this DC/AC Accessory Inverter.  When connected to a balanced three phase motor, this would be the current in each individual phase of the motor.";
CM_ SG_ 2565921790 DAAssrInvrtr2OprtnlStts "DC/AC Accessory Inverter 2 Operational Status: Operating Status of this DC/AC Accessory Inverter output. The Inverter Output Faulted state will be communicated when the inverter output has shutdown due to an overload condition or other fault.000b = O...";
CM_ SG_ 2565921790 DAAssrInvrtr2LdshdRqst "DC/AC Accessory Inverter 2 Loadshed Request: Loadshed Request from this DC/AC Accessory Inverter output.  The Loadshed Requested state is an indication that the inverter output powering this device has a malfunction and is in a limit condition and if...";
CM_ SG_ 2565921790 DAAssrInvrtr2HvlStts "DC/AC Accessory Inverter 2 HVIL Status: High Voltage Interlock Loop (HVIL) state of the DC/AC Accessory Inverter 2.00b = HVIL Closed01b = HVIL Open10b = Error11b = Not Available";
CM_ BO_ 2565922558 "DC/AC Accessory Inverter 3 Command";
CM_ SG_ 2565922558 DAAssrInvrtr3DvMxmmFrqn "DC/AC Accessory Inverter 3 Device Maximum Frequency: Signal to the DC/AC Accessory Inverter indicating the maximum frequency of the devices(s) attached to the inverter output.  Each output may control multiple devices (e.g. electric motors) if they a...";
CM_ SG_ 2565922558 DAAssrInvrtr3DvMnmmFrqn "DC/AC Accessory Inverter 3 Device Minimum Frequency: Signal to the DC/AC Accessory Inverter indicating the minimum frequency of the device(s) attached to the inverter output.  Each output may control multiple devices (e.g. electric motors) if they al...";
CM_ SG_ 2565922558 DAAssrInvrtr3DvRtdFrqn "DC/AC Accessory Inverter 3 Device Rated Frequency: Signal to the DC/AC Accessory Inverter indicating the rated frequency of the device(s) attached to the inverter output.  Each output may control multiple devices (e.g. electric motors) if they all op...";
CM_ SG_ 2565922558 DAAssrInvrtr3DvRtdRmsVltg "DC/AC Accessory Inverter 3 Device Rated RMS Voltage: Signal to the DC/AC Accessory Inverter indicating the rated RMS voltage of the device(s) attached to the inverter output.   Each output may control multiple devices (e.g. electric motors) if they a...";
CM_ SG_ 2565922558 DAAssrInvrtr3DvFrqnRtOfChngLmt "DC/AC Accessory Inverter 3 Device Frequency Rate of Change Limit: Signal to the DC/AC Accessory Inverter indicating the frequency rate of change limit of the device(s) attached to the inverter output (Note: Increasing and decreasing rates can be cont...";
CM_ SG_ 2565922558 DAAssrInvrtr3FrqnCmmnd "DC/AC Accessory Inverter 3 Frequency Command: Command to the DC/AC Accessory Inverter indicating the Inverter frequency desired for the device(s) attached to the inverter output.  Each output may control multiple devices (e.g. electric motors) if the...";
CM_ SG_ 2565922558 DAAssrInvrtr3Dv1Stts "DC/AC Accessory Inverter 3 Device 1 Status: Signal to the DC/AC Accessory Inverter indicating the state of the device attached to the inverter output.  Each output may control multiple devices (e.g. electric motors) if they all operate at the same fr...";
CM_ SG_ 2565922558 DAAssrInvrtr3Dv2Stts "DC/AC Accessory Inverter 3 Device 2 Status: Signal to the DC/AC Accessory Inverter indicating the state of the device attached to the inverter output.  Each output may control multiple devices (e.g. electric motors) if they all operate at the same fr...";
CM_ SG_ 2565922558 DAAssrInvrtr3OprtnlCmmnd "DC/AC Accessory Inverter 3 Operational Command: Command to the DC/AC Accessory Inverter to enable this output.  Each output may control multiple devices (e.g. electric motors) if they all operate at the same frequency.00b = Disable DC/AC Accessory In...";
CM_ SG_ 2565922558 DAAssIvt3ASdMtSttRsVtRqst "DC/AC Accessory Inverter 3 AC Side Motor Starting RMS Voltage Request: Signal to the DC/AC Accessory Inverter indicating the requested AC side RMS voltage for starting the attached accessory motor.   In a V/Hz variable speed motor control application...";
CM_ BO_ 2565922814 "DC/AC Accessory Inverter 3 Feedback";
CM_ SG_ 2565922814 DcAcAccessoryInverter3Frequency "DC/AC Accessory Inverter 3 Frequency: Present operating frequency of this DC/AC Accessory Inverter output.";
CM_ SG_ 2565922814 DAAssrInvrtr3ASdRmsVltg "DC/AC Accessory Inverter 3 AC Side RMS Voltage: Present operating AC Side line to line RMS voltage of this DC/AC Accessory Inverter output.  In a three phase balanced motor, this is the RMS voltage across one phase of the motor.";
CM_ SG_ 2565922814 DAAssrInvrtr3ASdPwr "DC/AC Accessory Inverter 3 AC Side Power: Present operating AC Side power of this DC/AC Accessory Inverter output.";
CM_ SG_ 2565922814 DAAssrInvrtr3ASdRmsCrrnt "DC/AC Accessory Inverter 3 AC Side RMS Current: Present operating AC Side output RMS line Current of this DC/AC Accessory Inverter.  When connected to a balanced three phase motor, this would be the current in each individual phase of the motor.";
CM_ SG_ 2565922814 DAAssrInvrtr3OprtnlStts "DC/AC Accessory Inverter 3 Operational Status: Operating Status of this DC/AC Accessory Inverter output. The Inverter Output Faulted state will be communicated when the inverter output has shutdown due to an overload condition or other fault.000b = O...";
CM_ SG_ 2565922814 DAAssrInvrtr3LdshdRqst "DC/AC Accessory Inverter 3 Loadshed Request: Loadshed Request from this DC/AC Accessory Inverter output.  The Loadshed Requested state is an indication that the inverter output powering this device has a malfunction and is in a limit condition and if...";
CM_ SG_ 2565922814 DAAssrInvrtr3HvlStts "DC/AC Accessory Inverter 3 HVIL Status: High Voltage Interlock Loop (HVIL) state of the DC/AC Accessory Inverter 3.00b = HVIL Closed01b = HVIL Open10b = Error11b = Not Available";
CM_ BO_ 2565923582 "DC/AC Accessory Inverter 4 Command";
CM_ SG_ 2565923582 DAAssrInvrtr4DvMxmmFrqn "DC/AC Accessory Inverter 4 Device Maximum Frequency: Signal to the DC/AC Accessory Inverter indicating the maximum frequency of the devices(s) attached to the inverter output.  Each output may control multiple devices (e.g. electric motors) if they a...";
CM_ SG_ 2565923582 DAAssrInvrtr4DvMnmmFrqn "DC/AC Accessory Inverter 4 Device Minimum Frequency: Signal to the DC/AC Accessory Inverter indicating the minimum frequency of the device(s) attached to the inverter output.  Each output may control multiple devices (e.g. electric motors) if they al...";
CM_ SG_ 2565923582 DAAssrInvrtr4DvRtdFrqn "DC/AC Accessory Inverter 4 Device Rated Frequency: Signal to the DC/AC Accessory Inverter indicating the rated frequency of the device(s) attached to the inverter output.  Each output may control multiple devices (e.g. electric motors) if they all op...";
CM_ SG_ 2565923582 DAAssrInvrtr4DvRtdRmsVltg "DC/AC Accessory Inverter 4 Device Rated RMS Voltage: Signal to the DC/AC Accessory Inverter indicating the rated RMS voltage of the device(s) attached to the inverter output.   Each output may control multiple devices (e.g. electric motors) if they a...";
CM_ SG_ 2565923582 DAAssrInvrtr4DvFrqnRtOfChngLmt "DC/AC Accessory Inverter 4 Device Frequency Rate of Change Limit: Signal to the DC/AC Accessory Inverter indicating the frequency rate of change limit of the device(s) attached to the inverter output (Note: Increasing and decreasing rates can be cont...";
CM_ SG_ 2565923582 DAAssrInvrtr4FrqnCmmnd "DC/AC Accessory Inverter 4 Frequency Command: Command to the DC/AC Accessory Inverter indicating the Inverter frequency desired for the device(s) attached to the inverter output.  Each output may control multiple devices (e.g. electric motors) if the...";
CM_ SG_ 2565923582 DAAssrInvrtr4Dv1Stts "DC/AC Accessory Inverter 4 Device 1 Status: Signal to the DC/AC Accessory Inverter indicating the state of the device attached to the inverter output.  Each output may control multiple devices (e.g. electric motors) if they all operate at the same fr...";
CM_ SG_ 2565923582 DAAssrInvrtr4Dv2Stts "DC/AC Accessory Inverter 4 Device 2 Status: Signal to the DC/AC Accessory Inverter indicating the state of the device attached to the inverter output.  Each output may control multiple devices (e.g. electric motors) if they all operate at the same fr...";
CM_ SG_ 2565923582 DAAssrInvrtr4OprtnlCmmnd "DC/AC Accessory Inverter 4 Operational Command: Command to the DC/AC Accessory Inverter to enable this output.  Each output may control multiple devices (e.g. electric motors) if they all operate at the same frequency.00b = Disable DC/AC Accessory In...";
CM_ SG_ 2565923582 DAAssIvt4ASdMtSttRsVtRqst "DC/AC Accessory Inverter 4 AC Side Motor Starting RMS Voltage Request: Signal to the DC/AC Accessory Inverter indicating the requested AC side RMS voltage for starting the attached accessory motor.   In a V/Hz variable speed motor control application...";
CM_ BO_ 2565923838 "DC/AC Accessory Inverter 4 Feedback";
CM_ SG_ 2565923838 DcAcAccessoryInverter4Frequency "DC/AC Accessory Inverter 4 Frequency: Present operating frequency of this DC/AC Accessory Inverter output.";
CM_ SG_ 2565923838 DAAssrInvrtr4ASdRmsVltg "DC/AC Accessory Inverter 4 AC Side RMS Voltage: Present operating AC Side line to line RMS voltage of this DC/AC Accessory Inverter output.  In a three phase balanced motor, this is the RMS voltage across one phase of the motor.";
CM_ SG_ 2565923838 DAAssrInvrtr4ASdPwr "DC/AC Accessory Inverter 4 AC Side Power: Present operating AC Side power of this DC/AC Accessory Inverter output.";
CM_ SG_ 2565923838 DAAssrInvrtr4ASdRmsCrrnt "DC/AC Accessory Inverter 4 AC Side RMS Current: Present operating AC Side output RMS line Current of this DC/AC Accessory Inverter.  When connected to a balanced three phase motor, this would be the current in each individual phase of the motor.";
CM_ SG_ 2565923838 DAAssrInvrtr4OprtnlStts "DC/AC Accessory Inverter 4 Operational Status: Operating Status of this DC/AC Accessory Inverter output. The Inverter Output Faulted state will be communicated when the inverter output has shutdown due to an overload condition or other fault.000b = O...";
CM_ SG_ 2565923838 DAAssrInvrtr4LdshdRqst "DC/AC Accessory Inverter 4 Loadshed Request: Loadshed Request from this DC/AC Accessory Inverter output.  The Loadshed Requested state is an indication that the inverter output powering this device has a malfunction and is in a limit condition and if...";
CM_ SG_ 2565923838 DAAssrInvrtr4HvlStts "DC/AC Accessory Inverter 4 HVIL Status: High Voltage Interlock Loop (HVIL) state of the DC/AC Accessory Inverter 4.00b = HVIL Closed01b = HVIL Open10b = Error11b = Not Available";
CM_ BO_ 2565925374 "Aftertreatment 1 Intake Gas 3";
CM_ SG_ 2565925374 EngineExhaust1Nox2 "Engine Exhaust 1 NOx 2: The second measurement of the amount of combined NO and NO2 in the exhaust, represented in NOx molecule parts per million non-NOx molecules in exhaust bank 1.  This sensor is located at the intake of the SCR system if an SCR s...";
CM_ SG_ 2565925374 EngineExhaust1Nox2ReadingStable "Engine Exhaust 1 NOx 2 Reading Stable: Indicates that the NOx reading of the second NOx sensor is stable as determined by the manufacturer's control software in exhaust bank 1.  This sensor is located at the intake of the SCR system if an SCR system ...";
CM_ SG_ 2565925374 EngnExhst1NxSnsr2PrlmnrFm "Engine Exhaust 1 NOx Sensor 2 Preliminary FMI: Used to identify the applicable J1939-73 FMI detected in the second NOx sensor by the manufacturer's sensor control software in exhaust bank 1.  In the case of multiple failures the most severe is commun...";
CM_ SG_ 2565925374 EngnExhst1NxSnsr2SlfDgnssStts "Engine Exhaust 1 NOx Sensor 2 Self-diagnosis Status: Self-diagnosis result status for the second NOx sensor in Engine Exhaust Bank 1 (EEB1).  This sensor is located at the intake of the aftertreatment system if an aftertreatment system exists.000b = ...";
CM_ SG_ 2565925374 EngineExhaust1PercentOxygen2 "Engine Exhaust 1 Percent Oxygen 2: The second measurement of the actual oxidation factor (Percent Oxygen) of the gas within the exhaust stream. For positive values, the parameter represents the percent oxygen in excess of the amount required for stoi...";
CM_ SG_ 2565925374 EngnExhst1GsSnsr2PwrInRng "Engine Exhaust 1 Gas Sensor 2 Power In Range: Indicates that the second measurement of power supplied to the gas sensor, either NOx or O2, is within the manufacturer's specification in exhaust bank 1.  This parameter reports the status as reported by...";
CM_ SG_ 2565925374 EngnExhst1GsSnsr2AtTmprtr "Engine Exhaust 1 Gas Sensor 2 at Temperature: Indicates that the heater element of the gas second sensor, either NOx or O2, is within the manufacturer's specified range for accurate measurements in exhaust bank 1.  This sensor is located at the engin...";
CM_ SG_ 2565925374 EngnExhst1WdRngPrntOxgn2RdngStl "Engine Exhaust 1 Wide-Range Percent Oxygen 2 Reading Stable: Indicates that the second measurement of the percent oxygen reading of the gas sensor, either NOx or O2, is stable as determined by the manufacturer's control software in exhaust bank 1.Thi...";
CM_ SG_ 2565925374 EngnExhst1GsSnsr2HtrPrlmnrFm "Engine Exhaust 1 Gas Sensor 2 Heater Preliminary FMI: Used to identify the second applicable J1939-73 FMI detected in the heater of the exhaust gas sensor, either NOx or O2, by the manufacturer's sensor control software in exhaust bank 1.  In the cas...";
CM_ SG_ 2565925374 EngnExhst1GsSnsr2HtrCntrl "Engine Exhaust 1 Gas Sensor 2 Heater Control: Indicates the heater status in the warm-up process.  Upon receiving a power-up command, the second gas sensor ramps up according to a manufacturer defined profile.  The Preheat 1, Preheat 2, and Automatic...";
CM_ SG_ 2565925374 EngnExhst1OxgnSnsr2PrlmnrFm "Engine Exhaust 1 Oxygen Sensor 2 Preliminary FMI: Used to identify the second applicable J1939-73 FMI detected in the oxygen sensor by the manufacturer's sensor control software in exhaust bank 1.   In the case of multiple failures the most severe is...";
CM_ BO_ 2565925630 "Aftertreatment 1 Outlet Gas 3";
CM_ SG_ 2565925630 Aftertreatment1OutletNox2 "Aftertreatment 1 Outlet NOx 2: The second measurement of the amount of combined NO and NO2 in the exhaust exiting the aftertreatment system measured by a NOx sensor at the aftertreatment outlet, represented in NOx molecule parts per million non-NOx m...";
CM_ SG_ 2565925630 Aftrtrtmnt1OtltGsSnsr2HtrCntrl "Aftertreatment 1 Outlet Gas Sensor 2 Heater Control: Indicates the heater status in the warm-up process.  Upon receiving a power-up command, the gas second sensor ramps up according to a manufacturer defined profile.  The Preheat 1, Preheat 2, and Au...";
CM_ SG_ 2565925630 Aftrtrtmnt1OtltGsSnsr2PwrInRng "Aftertreatment 1 Outlet Gas Sensor 2 Power In Range: Indicates that the second measurement of power supplied to the aftertreatment outlet gas sensor, either NOx or O2, is within the manufacturer's specification in exhaust bank 1. This parameter repor...";
CM_ SG_ 2565925630 Aftrtrtmnt1OtltPrntOxgn2 "Aftertreatment 1 Outlet Percent Oxygen 2: The second measurement of the actual oxidation factor (percent oxygen) of the gas within the exhaust stream.  For positive values, the parameter represents the percent oxygen in excess of the amount required ...";
CM_ SG_ 2565925630 Atttt1OttWdRPtOx2RdSt "Aftertreatment 1 Outlet Wide-Range Percent Oxygen 2 Reading Stable: Indicates that the percent oxygen reading of the aftertreatment outlet gas second sensor, either NOx or O2, is stable as determined by the manufacturer's control software in exhaust ...";
CM_ SG_ 2565925630 Aftrtrtmnt1OtltGsSnsr2AtTmprtr "Aftertreatment 1 Outlet Gas Sensor 2 at Temperature: Indicates that the heater element of the aftertreatment outlet gas second sensor, either NOx or O2, is within the manufacturer's specified range for accurate measurements in exhaust bank 1.00b = No...";
CM_ SG_ 2565925630 Aftrtrtmnt1OtltNx2RdngStl "Aftertreatment 1 Outlet NOx 2 Reading Stable: Indicates that the NOx reading of the aftertreatment outlet NOx second sensor is stable as determined by the manufacturer's control software in exhaust bank 1.00b = Not stable01b = Stable10b = Error11b = ...";
CM_ SG_ 2565925630 Atttt1OttGsSs2HtPF "Aftertreatment 1 Outlet Gas Sensor 2 Heater Preliminary FMI: Used to identify the applicable J1939-73 FMI detected in the heater of the outlet exhaust gas second sensor, either NOx or O2, by the manufacturer's sensor control software in exhaust bank ...";
CM_ SG_ 2565925630 Aftrtrtmnt1OtltNxSnsr2PrlmnrFm "Aftertreatment 1 Outlet NOx Sensor 2 Preliminary FMI: Used to identify the applicable J1939-73 FMI detected in the aftertreatment outlet NOx second sensor by the manufacturer's sensor control software in exhaust bank 1.  In the case of multiple failu...";
CM_ SG_ 2565925630 Atttt1OttNxSs2SDssStts "Aftertreatment 1 Outlet NOx Sensor 2 Self-diagnosis Status: Self-diagnosis result status for NOx second sensor ATO1 (Aftertreatment Outlet Bank 1)000b = Diagnosis not active001b = NOx Sensor ATO1 Self-diagnosis active flag010b = NOx Sensor ATO1 Self-...";
CM_ SG_ 2565925630 Atttt1OttOxSs2PF "Aftertreatment 1 Outlet Oxygen Sensor 2 Preliminary FMI: Used to identify the applicable J1939-73 FMI detected in the aftertreatment outlet oxygen second sensor by the manufacturer's sensor control software in exhaust bank 1.  In the case of multiple...";
CM_ BO_ 2565925886 "Aftertreatment 2 Intake Gas 3";
CM_ SG_ 2565925886 EngineExhaust2Nox2 "Engine Exhaust 2 NOx 2: The amount of combined NO and NO2 in the exhaust measured by the second NOx sensor at the aftertreatment intake, represented in NOx molecule parts per million non-NOx molecules in exhaust bank 2.  This sensor is located at the...";
CM_ SG_ 2565925886 EngineExhaust2Nox2ReadingStable "Engine Exhaust 2 NOx 2 Reading Stable: Indicates that the NOx reading of the second NOx sensor is stable as determined by the manufacturer's control software in exhaust bank 2.  This sensor is located at the intake of the SCR system if an SCR system ...";
CM_ SG_ 2565925886 EngnExhst2NxSnsr2PrlmnrFm "Engine Exhaust 2 NOx Sensor 2 Preliminary FMI: Used to identify the applicable J1939-73 FMI detected in the second NOx sensor by the manufacturer's sensor control software in exhaust bank 2.  This sensor is located at the intake of the SCR system if ...";
CM_ SG_ 2565925886 EngnExhst2NxSnsr2SlfDgnssStts "Engine Exhaust 2 NOx Sensor 2 Self-diagnosis Status: Self-diagnosis result status for NOx second sensor EEB2 (Engine Exhaust Bank 2).  This sensor is located at the intake of the aftertreatment system if an aftertreatment system exists.000b = Diagnos...";
CM_ SG_ 2565925886 EngineExhaust2PercentOxygen2 "Engine Exhaust 2 Percent Oxygen 2: The actual oxidation factor (percent oxygen) of the gas within the exhaust stream.  For positive values, the parameter represents the percent oxygen in excess of the amount required for stoichiometric combustion.  F...";
CM_ SG_ 2565925886 EngnExhst2GsSnsr2PwrInRng "Engine Exhaust 2 Gas Sensor 2 Power In Range: Indicates that the power supplied to the second gas sensor, either NOx or O2, is within the manufacturer's specification in exhaust bank 2.  This sensor is located at the engine exhaust in bank 2 and befo...";
CM_ SG_ 2565925886 EngnExhst2GsSnsr2AtTmprtr "Engine Exhaust 2 Gas Sensor 2 at Temperature: Indicates that the heater element of the second gas sensor, either NOx or O2, is within the manufacturer's specified range for accurate measurements in exhaust bank 2.  This sensor is located at the engin...";
CM_ SG_ 2565925886 EngnExhst2WdRngPrntOxgn2RdngStl "Engine Exhaust 2 Wide-Range Percent Oxygen 2 Reading Stable: Indicates that the percent oxygen reading of the second gas sensor, either NOx or O2, is stable as determined by the manufacturer's control software in exhaust bank 2.  This sensor is locat...";
CM_ SG_ 2565925886 EngnExhst2GsSnsr2HtrPrlmnrFm "Engine Exhaust 2 Gas Sensor 2 Heater Preliminary FMI: Used to identify the applicable J1939-73 FMI detected in the heater of the second gas sensor, either NOx or O2, by the manufacturer's sensor control software in exhaust bank 2.  In the case of mul...";
CM_ SG_ 2565925886 EngnExhst2GsSnsr2HtrCntrl "Engine Exhaust 2 Gas Sensor 2 Heater Control: Indicates the heater status in the warm-up process.  Upon receiving a power-up command, the second gas sensor ramps up according to a manufacturer defined profile.  The Preheat 1, Preheat 2, and Automatic...";
CM_ SG_ 2565925886 EngnExhst2OxgnSnsr2PrlmnrFm "Engine Exhaust 2 Oxygen Sensor 2 Preliminary FMI: Used to identify the applicable J1939-73 FMI detected in the second oxygen sensor by the manufacturer's sensor control software in exhaust bank 2.  In the case of multiple failures the most severe is ...";
CM_ BO_ 2565926142 "Aftertreatment 2 Outlet Gas 3";
CM_ SG_ 2565926142 Aftertreatment2OutletNox2 "Aftertreatment 2 Outlet NOx 2: The amount of combined NO and NO2 in the exhaust entering the aftertreatment system measured by the second NOx sensor at the aftertreatment outlet, represented in NOx molecule parts per million non-NOx molecules in exha...";
CM_ SG_ 2565926142 Aftrtrtmnt2OtltGsSnsr2HtrCntrl "Aftertreatment 2 Outlet Gas Sensor 2 Heater Control: Indicates the heater status in the warm-up process.  Upon receiving a power-up command, the gas second sensor ramps up according to a manufacturer defined profile.  The Preheat 1, Preheat 2, and Au...";
CM_ SG_ 2565926142 Aftrtrtmnt2OtltGsSnsr2PwrInRng "Aftertreatment 2 Outlet Gas Sensor 2 Power In Range:  Indicates that the power supplied to the aftertreatment outlet gas second sensor, either NOx or O2, is within the manufacturer's specification in exhaust bank 2.For a single exhaust bank system, r...";
CM_ SG_ 2565926142 Aftrtrtmnt2OtltPrntOxgn2 "Aftertreatment 2 Outlet Percent Oxygen 2: The actual oxidation factor (percent oxygen) of the gas within the exhaust stream.  For positive values, the parameter represents the percent oxygen in excess of the amount required for stoichiometric combust...";
CM_ SG_ 2565926142 Atttt2OttWdRPtOx2RdSt "Aftertreatment 2 Outlet Wide-Range Percent Oxygen 2 Reading Stable: Indicates that the percent oxygen reading of the aftertreatment outlet gas second sensor, either NOx or O2, is stable as determined by the manufacturer's control software in exhaust ...";
CM_ SG_ 2565926142 Aftrtrtmnt2OtltGsSnsr2AtTmprtr "Aftertreatment 2 Outlet Gas Sensor 2 at Temperature: Indicates that the heater element of the aftertreatment outlet gas second sensor, either NOx or O2, is within the manufacturer's specified range for accurate measurements in exhaust bank 2.For a si...";
CM_ SG_ 2565926142 Aftrtrtmnt2OtltNx2RdngStl "Aftertreatment 2 Outlet NOx  2 Reading Stable: Indicates that the NOx reading of the aftertreatment outlet NOx second sensor is stable as determined by the manufacturer's control software in exhaust bank 2.For a single exhaust bank system, refer to p...";
CM_ SG_ 2565926142 Atttt2OttGsSs2HtPF "Aftertreatment 2 Outlet Gas Sensor 2 Heater Preliminary FMI: Used to identify the applicable J1939-73 FMI detected in the heater of the outlet exhaust gas second sensor, either NOx or O2, by the manufacturer's sensor control software in exhaust bank ...";
CM_ SG_ 2565926142 Aftrtrtmnt2OtltNxSnsr2PrlmnrFm "Aftertreatment 2 Outlet NOx Sensor 2 Preliminary FMI: Used to identify the applicable J1939-73 FMI detected in the aftertreatment outlet NOx second sensor by the manufacturer's sensor control software in exhaust bank 2.  In the case of multiple failu...";
CM_ SG_ 2565926142 Atttt2OttNxSs2SDssStts "Aftertreatment 2 Outlet NOx Sensor 2 Self-diagnosis Status: Self-diagnosis result status for second NOx sensor ATO2 (Aftertreatment Outlet Bank 2)000b = Diagnosis not active001b = NOx Sensor ATO2 Self-diagnosis active flag010b = NOx Sensor ATO2 Self-...";
CM_ SG_ 2565926142 Atttt2OttOxSs2PF "Aftertreatment 2 Outlet Oxygen Sensor 2 Preliminary FMI: Used to identify the applicable J1939-73 FMI detected in the aftertreatment outlet oxygen second sensor by the manufacturer's sensor control software in exhaust bank 2.  In the case of multiple...";
CM_ BO_ 2565932286 "Engine Speed Sensor Information 2";
CM_ SG_ 2565932286 EngineSpeed4 "Engine Speed 4: The engine speed as measured by speed sensor 4.Notes: This is for the engine speed from the 4th engine speed sensor. This may be different than SPN 190 when used in multiple engine speed sensor configurations. In an application with m...";
CM_ BO_ 2565932798 "Well Stimulation Pump System 1";
CM_ SG_ 2565932798 WllStmltnPmpDshrgPrssr "Well Stimulation Pump Discharge Pressure: The pressure on the discharge side of the well stimulation pump.";
CM_ SG_ 2565932798 WllStmltnPmpStnPrssr "Well Stimulation Pump Suction Pressure: The pressure on the suction side of the well stimulation pump.";
CM_ BO_ 2565933054 "Well Stimulation Pump System 2";
CM_ SG_ 2565933054 WellStimulationPumpSpeed "Well Stimulation Pump Speed: The operating speed of the well stimulation pump.";
CM_ SG_ 2565933054 WllStmltnPmpGrBxOlPrssr "Well Stimulation Pump Gear Box Oil Pressure: The oil pressure measured in the well stimulation pump gear box.";
CM_ SG_ 2565933054 WllStmltnPmpGrBxOlTmprtr "Well Stimulation Pump Gear Box Oil Temperature: Temperature of the oil in the well stimulation pump gear box.";
CM_ SG_ 2565933054 WllStmltnPmpGrBxOtltOlTmprtr "Well Stimulation Pump Gear Box Outlet Oil Temperature: Temperature of the oil at the outlet of the well stimulation pump gear box.  Reference SPN 8157 for the temperature at the inlet of the pump gear box.";
CM_ BO_ 2565934590 "Fuel Information 6 (Gaseous)";
CM_ SG_ 2565934590 EngnFlVlv2DffrntlPrssr "Engine Fuel Valve 2 Differential Pressure: The differential pressure between the intake and the outlet of the second gaseous fuel valve.";
CM_ BO_ 2565942014 "DC/AC Accessory Inverter 3 Feedback 2";
CM_ SG_ 2565942014 DAAssrInvrtr3PwrLmtdDTDSdCrrnt "DC/AC Accessory Inverter 3 Power Limited due to DC Side Current: Output power is being limited due to DC Side input current (see SPN 9268) approaching or exceeding the maximum limit (See SPN 9286).00b = No power limit for this reason01b = Power limit...";
CM_ SG_ 2565942014 DAAssIvt3PwLtdDTASdRsCt "DC/AC Accessory Inverter 3 Power Limited due to AC Side RMS Current: AC Side Output power is being limited due to AC Side output RMS current (see SPN 9202) approaching or exceeding the maximum limit (See SPN 9288).00b = No power limit for this reason...";
CM_ SG_ 2565942014 DAAssIvt3PwLtdDTDSdVtM "DC/AC Accessory Inverter 3 Power Limited due to DC Side Voltage Minimum: Output power is being limited due to DC Side input voltage (see SPN 9267) approaching or falling below the minimum limit  (SPN 9285).00b = No power limit for this reason01b = Po...";
CM_ SG_ 2565942014 DAAssrInvrtr3FrqnCmmndBlwMnmm "DC/AC Accessory Inverter 3 Frequency Command below Minimum: Output frequency is being limited due to frequency command (see SPN 8361) approaching or falling below the minimum limit (SPN 8357).00b = No frequency limit for this reason01b = Frequency li...";
CM_ SG_ 2565942014 DAAssrInvrtr3FrqnCmmndExdsMxmm "DC/AC Accessory Inverter 3 Frequency Command exceeds Maximum: Output frequency is being limited due to frequency command (see SPN 8361) approaching or exceeding the maximum limit (SPN 8356).00b = No frequency limit for this reason01b = Frequency limi...";
CM_ SG_ 2565942014 DAAssIvt3PwLtdDTCtTpt "DC/AC Accessory Inverter 3 Power Limited due to Controller Temperature: Output power is being limited due to the controller temperature (see SPN 9261) approaching or exceeding the maximum limit.00b = No power limit for this reason01b = Power limited ...";
CM_ SG_ 2565942014 DAAssIvt3PwLtdDTEtFtTpt "DC/AC Accessory Inverter 3 Power Limited due to Electronic Filter Temperature: Output power is being limited due to electronic filter temperature (see SPN 9262) approaching or exceeding the maximum limit.00b = No power limit for this reason01b = Powe...";
CM_ SG_ 2565942014 DAAssIvt3PwLtdDTPwEtsTpt "DC/AC Accessory Inverter 3 Power Limited due to Power Electronics Temperature: Output power is being limited due to power electronics temperature (see SPN 9263) approaching or exceeding the maximum limit.00b = No power limit for this reason01b = Powe...";
CM_ SG_ 2565942014 DAAssIvt3PwLtdDTRtOCLt "DC/AC Accessory Inverter 3 Power Limited due to Rate of Change Limit: Output power is being limited due to the frequency approaching or exceeding the rate of change limit (see SPN 8360).00b = No power limit for this reason01b = Power limited for this...";
CM_ SG_ 2565942014 DAAssrInvrtr3PwrLmtdDTUndfndRsn "DC/AC Accessory Inverter 3 Power Limited due to Undefined Reason: Output power is being limited due to an undefined reason.00b = No power limit for this reason01b = Power limited for this reason10b = Error11b = Not Available";
CM_ BO_ 2565942782 "DC/AC Accessory Inverter 4 Feedback 2";
CM_ SG_ 2565942782 DAAssrInvrtr4PwrLmtdDTDSdCrrnt "DC/AC Accessory Inverter 4 Power Limited due to DC Side Current: Output power is being limited due to DC Side input current (see SPN 9298) approaching or exceeding the maximum limit (See SPN 9316).00b = No power limit for this reason01b = Power limit...";
CM_ SG_ 2565942782 DAAssIvt4PwLtdDTASdRsCt "DC/AC Accessory Inverter 4 Power Limited due to AC Side RMS Current: AC Side Output power is being limited due to AC Side output RMS current (see SPN 9203) approaching or exceeding the maximum limit (See SPN 9318).00b = No power limit for this reason...";
CM_ SG_ 2565942782 DAAssIvt4PwLtdDTDSdVtM "DC/AC Accessory Inverter 4 Power Limited due to DC Side Voltage Minimum: Output power is being limited due to DC Side input voltage (see SPN 9297) approaching or falling below the minimum limit (SPN 9315).00b = No power limit for this reason01b = Pow...";
CM_ SG_ 2565942782 DAAssrInvrtr4FrqnCmmndBlwMnmm "DC/AC Accessory Inverter 4 Frequency Command below Minimum: Output frequency is being limited due to frequency command (see SPN 8375) approaching or falling below the minimum limit (SPN 8371).00b = No frequency limit for this reason01b = Frequency li...";
CM_ SG_ 2565942782 DAAssrInvrtr4FrqnCmmndExdsMxmm "DC/AC Accessory Inverter 4 Frequency Command exceeds Maximum: Output frequency is being limited due to frequency command (see SPN 8375) approaching or exceeding the maximum limit (SPN 8370).00b = No frequency limit for this reason01b = Frequency limi...";
CM_ SG_ 2565942782 DAAssIvt4PwLtdDTCtTpt "DC/AC Accessory Inverter 4 Power Limited due to Controller Temperature: Output power is being limited due to the controller temperature (see SPN 9291) approaching or exceeding the maximum limit.00b = No power limit for this reason01b = Power limited ...";
CM_ SG_ 2565942782 DAAssIvt4PwLtdDTEtFtTpt "DC/AC Accessory Inverter 4 Power Limited due to Electronic Filter Temperature: Output power is being limited due to electronic filter temperature (see SPN 9292) approaching or exceeding the maximum limit.00b = No power limit for this reason01b = Powe...";
CM_ SG_ 2565942782 DAAssIvt4PwLtdDTPwEtsTpt "DC/AC Accessory Inverter 4 Power Limited due to Power Electronics Temperature: Output power is being limited due to power electronics temperature (see SPN 9293) approaching or exceeding the maximum limit.00b = No power limit for this reason01b = Powe...";
CM_ SG_ 2565942782 DAAssIvt4PwLtdDTRtOCLt "DC/AC Accessory Inverter 4 Power Limited due to Rate of Change Limit: Output power is being limited due to the frequency approaching or exceeding the rate of change limit (see SPN 8374).00b = No power limit for this reason01b = Power limited for this...";
CM_ SG_ 2565942782 DAAssrInvrtr4PwrLmtdDTUndfndRsn "DC/AC Accessory Inverter 4 Power Limited due to Undefined Reason: Output power is being limited due to an undefined reason.00b = No power limit for this reason01b = Power limited for this reason10b = Error11b = Not Available";
CM_ BO_ 2565943038 "DC/AC Accessory Inverter 5 Command";
CM_ SG_ 2565943038 DAAssrInvrtr5DvMxmmFrqn "DC/AC Accessory Inverter 5 Device Maximum Frequency: Signal to the DC/AC Accessory Inverter indicating the maximum frequency of the devices(s) attached to the inverter output.  Each output may control multiple devices (e.g. electric motors) if they a...";
CM_ SG_ 2565943038 DAAssrInvrtr5DvMnmmFrqn "DC/AC Accessory Inverter 5 Device Minimum Frequency: Signal to the DC/AC Accessory Inverter indicating the minimum frequency of the device(s) attached to the inverter output.  Each output may control multiple devices (e.g. electric motors) if they al...";
CM_ SG_ 2565943038 DAAssrInvrtr5DvRtdFrqn "DC/AC Accessory Inverter 5 Device Rated Frequency: Signal to the DC/AC Accessory Inverter indicating the rated frequency of the device(s) attached to the inverter output.  Each output may control multiple devices (e.g. electric motors) if they all op...";
CM_ SG_ 2565943038 DAAssrInvrtr5DvRtdRmsVltg "DC/AC Accessory Inverter 5 Device Rated RMS Voltage: Signal to the DC/AC Accessory Inverter indicating the rated RMS voltage of the device(s) attached to the inverter output.   Each output may control multiple devices (e.g. electric motors) if they a...";
CM_ SG_ 2565943038 DAAssrInvrtr5DvFrqnRtOfChngLmt "DC/AC Accessory Inverter 5 Device Frequency Rate of Change Limit: Signal to the DC/AC Accessory Inverter indicating the frequency rate of change limit of the device(s) attached to the inverter output (Note: Increasing and decreasing rates can be cont...";
CM_ SG_ 2565943038 DAAssrInvrtr5FrqnCmmnd "DC/AC Accessory Inverter 5 Frequency Command: Command to the DC/AC Accessory Inverter indicating the Inverter frequency desired for the device(s) attached to the inverter output.  Each output may control multiple devices (e.g. electric motors) if the...";
CM_ SG_ 2565943038 DAAssrInvrtr5Dv1Stts "DC/AC Accessory Inverter 5 Device 1 Status: Signal to the DC/AC Accessory Inverter indicating the state of the device attached to the inverter output.  Each output may control multiple devices (e.g. electric motors) if they all operate at the same fr...";
CM_ SG_ 2565943038 DAAssrInvrtr5Dv2Stts "DC/AC Accessory Inverter 5 Device 2 Status: Signal to the DC/AC Accessory Inverter indicating the state of the device attached to the inverter output.  Each output may control multiple devices (e.g. electric motors) if they all operate at the same fr...";
CM_ SG_ 2565943038 DAAssrInvrtr5OprtnlCmmnd "DC/AC Accessory Inverter 5 Operational Command: Command to the DC/AC Accessory Inverter to enable this output.  Each output may control multiple devices (e.g. electric motors) if they all operate at the same frequency.00b = Disable DC/AC Accessory In...";
CM_ SG_ 2565943038 DAAssIvt5ASdMtSttRsVtRqst "DC/AC Accessory Inverter 5 AC Side Motor Starting RMS Voltage Request: Signal to the DC/AC Accessory Inverter indicating the requested AC side RMS voltage for starting the attached accessory motor.   In a V/Hz variable speed motor control application...";
CM_ BO_ 2565943294 "DC/AC Accessory Inverter 5 Feedback";
CM_ SG_ 2565943294 DcAcAccessoryInverter5Frequency "DC/AC Accessory Inverter 5 Frequency: Present operating frequency of this DC/AC Accessory Inverter output.";
CM_ SG_ 2565943294 DAAssrInvrtr5ASdRmsVltg "DC/AC Accessory Inverter 5 AC Side RMS Voltage: Present operating AC Side line to line RMS voltage of this DC/AC Accessory Inverter output.  In a three phase balanced motor, this is the RMS voltage across one phase of the motor.";
CM_ SG_ 2565943294 DAAssrInvrtr5ASdPwr "DC/AC Accessory Inverter 5 AC Side Power: Present operating AC Side power of this DC/AC Accessory Inverter output.";
CM_ SG_ 2565943294 DAAssrInvrtr5ASdRmsCrrnt "DC/AC Accessory Inverter 5 AC Side RMS Current: Present operating AC Side output RMS line Current of this DC/AC Accessory Inverter.  When connected to a balanced three phase motor, this would be the current in each individual phase of the motor.";
CM_ SG_ 2565943294 DAAssrInvrtr5OprtnlStts "DC/AC Accessory Inverter 5 Operational Status: Operating Status of this DC/AC Accessory Inverter output. The Inverter Output Faulted state will be communicated when the inverter output has shutdown due to an overload condition or other fault.000b = O...";
CM_ SG_ 2565943294 DAAssrInvrtr5LdshdRqst "DC/AC Accessory Inverter 5 Loadshed Request: Loadshed Request from this DC/AC Accessory Inverter output.  The Loadshed Requested state is an indication that the inverter output powering this device has a malfunction and is in a limit condition and if...";
CM_ SG_ 2565943294 DAAssrInvrtr5HvlStts "DC/AC Accessory Inverter 5 HVIL Status: High Voltage Interlock Loop (HVIL) state of the DC/AC Accessory Inverter 5.00b = HVIL Closed01b = HVIL Open10b = Error11b = Not Available";
CM_ BO_ 2565944062 "DC/AC Accessory Inverter 5 Feedback 2";
CM_ SG_ 2565944062 DAAssrInvrtr5PwrLmtdDTDSdCrrnt "DC/AC Accessory Inverter 5 Power Limited due to DC Side Current: Output power is being limited due to DC Side input current (see SPN 9344) approaching or exceeding the maximum limit (See SPN 9362).00b = No power limit for this reason01b = Power limit...";
CM_ SG_ 2565944062 DAAssIvt5PwLtdDTASdRsCt "DC/AC Accessory Inverter 5 Power Limited due to AC Side RMS Current: AC Side Output power is being limited due to AC Side output RMS current (see SPN 9333) approaching or exceeding the maximum limit (See SPN 9364).00b = No power limit for this reason...";
CM_ SG_ 2565944062 DAAssIvt5PwLtdDTDSdVtM "DC/AC Accessory Inverter 5 Power Limited due to DC Side Voltage Minimum: Output power is being limited due to DC Side input voltage (see SPN 9343) approaching or falling below the minimum limit (SPN 9361).00b = No power limit for this reason01b = Pow...";
CM_ SG_ 2565944062 DAAssrInvrtr5FrqnCmmndBlwMnmm "DC/AC Accessory Inverter 5 Frequency Command below Minimum: Output frequency is being limited due to frequency command (see SPN 9326) approaching or falling below the minimum limit (SPN 9322).00b = No frequency limit for this reason01b = Frequency li...";
CM_ SG_ 2565944062 DAAssrInvrtr5FrqnCmmndExdsMxmm "DC/AC Accessory Inverter 5 Frequency Command exceeds Maximum: Output frequency is being limited due to frequency command (see SPN 9326) approaching or exceeding the maximum limit (SPN 9321).00b = No frequency limit for this reason01b = Frequency limi...";
CM_ SG_ 2565944062 DAAssIvt5PwLtdDTCtTpt "DC/AC Accessory Inverter 5 Power Limited due to Controller Temperature: Output power is being limited due to the controller temperature (see SPN 9337) approaching or exceeding the maximum limit.00b = No power limit for this reason01b = Power limited ...";
CM_ SG_ 2565944062 DAAssIvt5PwLtdDTEtFtTpt "DC/AC Accessory Inverter 5 Power Limited due to Electronic Filter Temperature: Output power is being limited due to electronic filter temperature (see SPN 9338) approaching or exceeding the maximum limit.00b = No power limit for this reason01b = Powe...";
CM_ SG_ 2565944062 DAAssIvt5PwLtdDTPwEtsTpt "DC/AC Accessory Inverter 5 Power Limited due to Power Electronics Temperature: Output power is being limited due to power electronics temperature (see SPN 9339) approaching or exceeding the maximum limit.00b = No power limit for this reason01b = Powe...";
CM_ SG_ 2565944062 DAAssIvt5PwLtdDTRtOCLt "DC/AC Accessory Inverter 5 Power Limited due to Rate of Change Limit: Output power is being limited due to the frequency approaching or exceeding the rate of change limit (see SPN 9325).00b = No power limit for this reason01b = Power limited for this...";
CM_ SG_ 2565944062 DAAssrInvrtr5PwrLmtdDTUndfndRsn "DC/AC Accessory Inverter 5 Power Limited due to Undefined Reason: Output power is being limited due to an undefined reason.00b = No power limit for this reason01b = Power limited for this reason10b = Error11b = Not Available";
CM_ BO_ 2566624510 "Electronic Engine Controller 22";
CM_ SG_ 2566624510 EngnExhstGsRrltn1ClrIntkPrssr "Engine Exhaust Gas Recirculation 1 Cooler Intake Pressure: Exhaust gas recirculation gage pressure is measured at the EGR cooler intake.";
CM_ SG_ 2566624510 TtlNmrOfCrnkAttmptsDrngEngnLf "Total Number of Crank Attempts During Engine Life: Reports the number of cranking cycles undergone during the life of the engine.Note: This is intended to count the number of crank attempts as described in SPN 3671.";
CM_ BO_ 2566624766 "Engine Hours 2";
CM_ SG_ 2566624766 EngnIdlMngmntAtvTtlTm "Engine Idle Management Active Total Time: Total accumulated time the engine is off due to the engine idle management system.";
CM_ BO_ 2566625022 "Engine Information 3";
CM_ SG_ 2566625022 InstntnsEstmtdEngnPwrRtLmt "Instantaneous Estimated Engine Power Rate Limit: Estimate of the maximum power load rate the engine can sustain at that moment in time.";
CM_ SG_ 2566625022 EngineExhaustBank1Pressure2 "Engine Exhaust Bank 1 Pressure 2: Second gage pressure of the exhaust gases as measured at the turbine intake of the turbocharger. This SP is to be used for inline engines or exhaust bank 1 of multiple bank engines.  See SPN 11799 for exhaust bank 2.";
CM_ SG_ 2566625022 EngineDifferentialPressure "Engine Differential Pressure: The differential pressure across the engine cylinders, between the intake and exhaust manifolds.";
CM_ BO_ 2566625278 "Vehicle Electrical Power 15";
CM_ SG_ 2566625278 SlBttrPk1Bttr1CptSttng "SLI Battery Pack 1 Battery 1 Capacity Setting: Informs the battery controller of the capacity of its associated battery.  This parameter applies to the first battery in the first set of batteries (battery pack) used for starting the engine, for light...";
CM_ SG_ 2566625278 SlBttrPk1Bttr2CptSttng "SLI Battery Pack 1 Battery 2 Capacity Setting: Informs the battery controller of the capacity of its associated battery.  This parameter applies to the second battery in the first set of batteries (battery pack) used for starting the engine, for ligh...";
CM_ SG_ 2566625278 SlBttrPk1Bttr3CptSttng "SLI Battery Pack 1 Battery 3 Capacity Setting: Informs the battery controller of the capacity of its associated battery.  This parameter applies to the third battery in the first set of batteries (battery pack) used for starting the engine, for light...";
CM_ SG_ 2566625278 SlBttrPk1Bttr4CptSttng "SLI Battery Pack 1 Battery 4 Capacity Setting: Informs the battery controller of the capacity of its associated battery.  This parameter applies to the fourth battery in the first set of batteries (battery pack) used for starting the engine, for ligh...";
CM_ BO_ 2566625790 "DC/AC Accessory Inverter 1 Temperatures";
CM_ SG_ 2566625790 DAAssrInvrtr1CntrllrTmprtr "DC/AC Accessory Inverter 1 Controller Temperature: Temperature of the DC/AC Accessory Inverter (e.g, controller, circuit board, enclosure).";
CM_ SG_ 2566625790 DAAssIvt1IvtEtFtTpt "DC/AC Accessory Inverter 1 Inverter Electronic Filter Temperature: Temperature of the electronic components that make up the DC/AC Accessory Inverter filter.";
CM_ SG_ 2566625790 DAAssrInvrtr1PwrEltrnsTmprtr "DC/AC Accessory Inverter 1 Power Electronics Temperature: Temperature of the DC/AC Accessory Inverter power electronics components (e.g, switch or heatsink).";
CM_ SG_ 2566625790 DAAssrInvrtr1ClntInTmprtr "DC/AC Accessory Inverter 1 Coolant  In Temperature: Temperature of the DC/AC Accessory Inverter Coolant measured at the input of the accessory inverter.";
CM_ SG_ 2566625790 DAAssrInvrtr1ClntOtTmprtr "DC/AC Accessory Inverter 1 Coolant Out Temperature: Temperature of the DC/AC Accessory Inverter Coolant measured at the output of the accessory inverter.";
CM_ BO_ 2566626558 "DC/AC Accessory Inverter 1 Configuration 1";
CM_ SG_ 2566626558 DAAssIvt1DSdVtMLtStt "DC/AC Accessory Inverter 1 DC Side Voltage Minimum Limit Setting: Reports the active minimum limit on the DC Side input voltage of the DC/AC Accessory Inverter.  The setting may be requested by a separate device (via SPN 9221) or determined by the DC...";
CM_ SG_ 2566626558 DAAssIvt1DSdCtMxLtStt "DC/AC Accessory Inverter 1 DC Side Current Maximum Limit Setting: Reports the active maximum limit on the DC Side input current of the DC/AC Accessory Inverter.  The setting may be requested by a separate device (via SPN 9222) or determined by the DC...";
CM_ SG_ 2566626558 DAAssIvt1ASdRsVtMxLtStt "DC/AC Accessory Inverter 1 AC Side RMS Voltage Maximum Limit Setting: Reports the active maximum limit on the AC Side output line to line RMS voltage of the DC/AC Accessory Inverter.  The setting may be requested by a separate device (via SPN 9223) o...";
CM_ SG_ 2566626558 DAAssIvt1ASdRsCtMxLtStt "DC/AC Accessory Inverter 1 AC Side RMS Current Maximum Limit Setting: Reports the active maximum limit on the AC side output RMS line current of the DC/AC Accessory Inverter.  The setting may be requested by a separate device (via SPN 9224) or determ...";
CM_ SG_ 2566626558 DAAssIvt1DSdVtMxLtStt "DC/AC Accessory Inverter 1 DC Side Voltage Maximum Limit Setting: Reports the active maximum limit on the DC Side input voltage of the DC/AC Accessory Inverter.  The setting may be requested by a separate device (via SPN 9529) or determined by the DC...";
CM_ SG_ 2566626558 DAAssIvt1DSdCtMLtStt "DC/AC Accessory Inverter 1 DC Side Current Minimum Limit Setting: Reports the active minimum limit on the DC Side input current of the DC/AC Accessory Inverter.  The setting may be requested by a separate device (via SPN 9530) or determined by the DC...";
CM_ SG_ 2566626558 DAAssIvt1ASdDtFqCdStt "DC/AC Accessory Inverter 1 AC Side Default Frequency Command Setting: Reports the active AC Side Default Frequency Command Setting of the DC/AC Accessory Inverter.  The setting may be requested by a separate device (via SPN 9523).Note: Report Not Ava...";
CM_ BO_ 2566626814 "DC/AC Accessory Inverter 1 Lifetime Data";
CM_ SG_ 2566626814 DAAssrInvrtr1TtlDInptChrg "DC/AC Accessory Inverter 1 Total DC Input Charge : Total lifetime charge converted by the DC/AC from the DC Side.  ";
CM_ SG_ 2566626814 DAAssrInvrtr1TtlDInptEnrg "DC/AC Accessory Inverter 1 Total DC Input Energy : Total lifetime energy converted by the DC/AC from the DC Side.";
CM_ BO_ 2566627070 "DC/AC Accessory Inverter 2 Temperatures";
CM_ SG_ 2566627070 DAAssrInvrtr2CntrllrTmprtr "DC/AC Accessory Inverter 2 Controller Temperature: Temperature of the DC/AC Accessory Inverter (e.g, controller, circuit board, enclosure).";
CM_ SG_ 2566627070 DAAssIvt2IvtEtFtTpt "DC/AC Accessory Inverter 2 Inverter Electronic Filter Temperature: Temperature of the electronic components that make up the DC/AC Accessory Inverter filter.";
CM_ SG_ 2566627070 DAAssrInvrtr2PwrEltrnsTmprtr "DC/AC Accessory Inverter 2 Power Electronics Temperature: Temperature of the DC/AC Accessory Inverter power electronics components (e.g, switch or heatsink).";
CM_ SG_ 2566627070 DAAssrInvrtr2ClntInTmprtr "DC/AC Accessory Inverter 2 Coolant  In Temperature: Temperature of the DC/AC Accessory Inverter Coolant measured at the input of the accessory inverter.";
CM_ SG_ 2566627070 DAAssrInvrtr2ClntOtTmprtr "DC/AC Accessory Inverter 2 Coolant Out Temperature: Temperature of the DC/AC Accessory Inverter Coolant measured at the output of the accessory inverter.";
CM_ BO_ 2566627838 "DC/AC Accessory Inverter 2 Configuration 1";
CM_ SG_ 2566627838 DAAssIvt2DSdVtMLtStt "DC/AC Accessory Inverter 2 DC Side Voltage Minimum Limit Setting: Reports the active minimum limit on the DC Side input voltage of the DC/AC Accessory Inverter.  The setting may be requested by a separate device (via SPN 9251) or determined by the DC...";
CM_ SG_ 2566627838 DAAssIvt2DSdCtMxLtStt "DC/AC Accessory Inverter 2 DC Side Current Maximum Limit Setting: Reports the active maximum limit on the DC Side input current of the DC/AC Accessory Inverter.  The setting may be requested by a separate device (via SPN 9252) or determined by the DC...";
CM_ SG_ 2566627838 DAAssIvt2ASdRsVtMxLtStt "DC/AC Accessory Inverter 2 AC Side RMS Voltage Maximum Limit Setting: Reports the active maximum limit on the AC Side output line to line RMS voltage of the DC/AC Accessory Inverter.  The setting may be requested by a separate device (via SPN 9253) o...";
CM_ SG_ 2566627838 DAAssIvt2ASdRsCtMxLtStt "DC/AC Accessory Inverter 2 AC Side RMS Current Maximum Limit Setting: Reports the active maximum limit on the AC side output RMS line current of the DC/AC Accessory Inverter.  The setting may be requested by a separate device (via SPN 9254) or determ...";
CM_ SG_ 2566627838 DAAssIvt2DSdVtMxLtStt "DC/AC Accessory Inverter 2 DC Side Voltage Maximum Limit Setting: Reports the active maximum limit on the DC Side input voltage of the DC/AC Accessory Inverter.  The setting may be requested by a separate device (via SPN 9535) or determined by the DC...";
CM_ SG_ 2566627838 DAAssIvt2DSdCtMLtStt "DC/AC Accessory Inverter 2 DC Side Current Minimum Limit Setting: Reports the active minimum limit on the DC Side input current of the DC/AC Accessory Inverter.  The setting may be requested by a separate device (via SPN 9536) or determined by the DC...";
CM_ SG_ 2566627838 DAAssIvt2ASdDtFqCdStt "DC/AC Accessory Inverter 2 AC Side Default Frequency Command Setting: Reports the active AC Side Default Frequency Command Setting of the DC/AC Accessory Inverter.  The setting may be requested by a separate device (via SPN 9524).Note: Report Not Ava...";
CM_ BO_ 2566628094 "DC/AC Accessory Inverter 2 Lifetime Data";
CM_ SG_ 2566628094 DAAssrInvrtr2TtlDInptChrg "DC/AC Accessory Inverter 2 Total DC Input Charge : Total lifetime charge converted by the DC/AC from the DC Side.  ";
CM_ SG_ 2566628094 DAAssrInvrtr2TtlDInptEnrg "DC/AC Accessory Inverter 2 Total DC Input Energy : Total lifetime energy converted by the DC/AC from the DC Side.";
CM_ BO_ 2566628350 "DC/AC Accessory Inverter 3 Temperatures";
CM_ SG_ 2566628350 DAAssrInvrtr3CntrllrTmprtr "DC/AC Accessory Inverter 3 Controller Temperature: Temperature of the DC/AC Accessory Inverter (e.g, controller, circuit board, enclosure).";
CM_ SG_ 2566628350 DAAssIvt3IvtEtFtTpt "DC/AC Accessory Inverter 3 Inverter Electronic Filter Temperature: Temperature of the electronic components that make up the DC/AC Accessory Inverter filter.";
CM_ SG_ 2566628350 DAAssrInvrtr3PwrEltrnsTmprtr "DC/AC Accessory Inverter 3 Power Electronics Temperature: Temperature of the DC/AC Accessory Inverter power electronics components (e.g, switch or heatsink).";
CM_ SG_ 2566628350 DAAssrInvrtr3ClntInTmprtr "DC/AC Accessory Inverter 3 Coolant  In Temperature: Temperature of the DC/AC Accessory Inverter Coolant measured at the input of the accessory inverter.";
CM_ SG_ 2566628350 DAAssrInvrtr3ClntOtTmprtr "DC/AC Accessory Inverter 3 Coolant Out Temperature: Temperature of the DC/AC Accessory Inverter Coolant measured at the output of the accessory inverter.";
BA_DEF_ SG_  "SPN" INT 0 524287;
BA_DEF_ BO_  "VFrameFormat" ENUM  "StandardCAN","ExtendedCAN","reserved","J1939PG";
BA_DEF_DEF_  "SPN" 0;
BA_DEF_DEF_  "VFrameFormat" "J1939PG";
BA_ "SPN" SG_ 2561081086 AuxiliaryIO49 3872;
BA_ "SPN" SG_ 2561081086 AuxiliaryIO50 3873;
BA_ "SPN" SG_ 2561081086 AuxiliaryIO51 3874;
BA_ "SPN" SG_ 2561081086 AuxiliaryIO52 3875;
BA_ "SPN" SG_ 2561081086 AuxiliaryIO53 3876;
BA_ "SPN" SG_ 2561081086 AuxiliaryIO54 3877;
BA_ "SPN" SG_ 2561081086 AuxiliaryIO55 3878;
BA_ "SPN" SG_ 2561081086 AuxiliaryIO56 3879;
BA_ "SPN" SG_ 2561081086 AuxiliaryIO57 3880;
BA_ "SPN" SG_ 2561081086 AuxiliaryIO58 3881;
BA_ "SPN" SG_ 2561081086 AuxiliaryIO59 3882;
BA_ "SPN" SG_ 2561081086 AuxiliaryIO60 3883;
BA_ "SPN" SG_ 2561081086 AuxiliaryIO61 3884;
BA_ "SPN" SG_ 2561081086 AuxiliaryIO62 3885;
BA_ "SPN" SG_ 2561081086 AuxiliaryIO63 3886;
BA_ "SPN" SG_ 2561081086 AuxiliaryIO64 3887;
BA_ "SPN" SG_ 2561081086 AuxiliaryIO65 3888;
BA_ "SPN" SG_ 2561081086 AuxiliaryIO66 3889;
BA_ "SPN" SG_ 2561081086 AuxiliaryIO67 3890;
BA_ "SPN" SG_ 2561081086 AuxiliaryIO68 3891;
BA_ "SPN" SG_ 2561081086 AuxiliaryIO69 3892;
BA_ "SPN" SG_ 2561081086 AuxiliaryIO70 3893;
BA_ "SPN" SG_ 2561081086 AuxiliaryIO71 3894;
BA_ "SPN" SG_ 2561081086 AuxiliaryIO72 3895;
BA_ "SPN" SG_ 2561081086 AuxiliaryIO73 3896;
BA_ "SPN" SG_ 2561081086 AuxiliaryIO74 3897;
BA_ "SPN" SG_ 2561081086 AuxiliaryIO75 3898;
BA_ "SPN" SG_ 2561081086 AuxiliaryIO76 3899;
BA_ "SPN" SG_ 2561081086 AuxiliaryIO77 3900;
BA_ "SPN" SG_ 2561081086 AuxiliaryIO78 3901;
BA_ "SPN" SG_ 2561081086 AuxiliaryIO79 3902;
BA_ "SPN" SG_ 2561081086 AuxiliaryIO80 3903;
BA_ "SPN" SG_ 2561146622 AuxiliaryIO17 3840;
BA_ "SPN" SG_ 2561146622 AuxiliaryIO18 3841;
BA_ "SPN" SG_ 2561146622 AuxiliaryIO19 3842;
BA_ "SPN" SG_ 2561146622 AuxiliaryIO20 3843;
BA_ "SPN" SG_ 2561146622 AuxiliaryIO21 3844;
BA_ "SPN" SG_ 2561146622 AuxiliaryIO22 3845;
BA_ "SPN" SG_ 2561146622 AuxiliaryIO23 3846;
BA_ "SPN" SG_ 2561146622 AuxiliaryIO24 3847;
BA_ "SPN" SG_ 2561146622 AuxiliaryIO25 3848;
BA_ "SPN" SG_ 2561146622 AuxiliaryIO26 3849;
BA_ "SPN" SG_ 2561146622 AuxiliaryIO27 3850;
BA_ "SPN" SG_ 2561146622 AuxiliaryIO28 3851;
BA_ "SPN" SG_ 2561146622 AuxiliaryIO29 3852;
BA_ "SPN" SG_ 2561146622 AuxiliaryIO30 3853;
BA_ "SPN" SG_ 2561146622 AuxiliaryIO31 3854;
BA_ "SPN" SG_ 2561146622 AuxiliaryIO32 3855;
BA_ "SPN" SG_ 2561146622 AuxiliaryIO33 3856;
BA_ "SPN" SG_ 2561146622 AuxiliaryIO34 3857;
BA_ "SPN" SG_ 2561146622 AuxiliaryIO35 3858;
BA_ "SPN" SG_ 2561146622 AuxiliaryIO36 3859;
BA_ "SPN" SG_ 2561146622 AuxiliaryIO37 3860;
BA_ "SPN" SG_ 2561146622 AuxiliaryIO38 3861;
BA_ "SPN" SG_ 2561146622 AuxiliaryIO39 3862;
BA_ "SPN" SG_ 2561146622 AuxiliaryIO40 3863;
BA_ "SPN" SG_ 2561146622 AuxiliaryIO41 3864;
BA_ "SPN" SG_ 2561146622 AuxiliaryIO42 3865;
BA_ "SPN" SG_ 2561146622 AuxiliaryIO43 3866;
BA_ "SPN" SG_ 2561146622 AuxiliaryIO44 3867;
BA_ "SPN" SG_ 2561146622 AuxiliaryIO45 3868;
BA_ "SPN" SG_ 2561146622 AuxiliaryIO46 3869;
BA_ "SPN" SG_ 2561146622 AuxiliaryIO47 3870;
BA_ "SPN" SG_ 2561146622 AuxiliaryIO48 3871;
BA_ "SPN" SG_ 2561212158 TextDisplayIndex 3614;
BA_ "SPN" SG_ 2561212158 TextDisplayInstructions 3613;
BA_ "SPN" SG_ 2561277694 CurrentRegion 8133;
BA_ "SPN" SG_ 2561277694 CurrentSubRegion 8134;
BA_ "SPN" SG_ 2561277694 LnDprtrWrnngEnlCmmnd 3564;
BA_ "SPN" SG_ 2561277694 LaneKeepingAssistEnableCommand 9751;
BA_ "SPN" SG_ 2561277694 LaneCenteringEnableCommand 9752;
BA_ "SPN" SG_ 2561277694 RqstdAtvStrngDrvrPrfrnMd 9760;
BA_ "SPN" SG_ 2561605374 ReferenceTirePressureSetting 3193;
BA_ "SPN" SG_ 2561605374 TireLocation 3192;
BA_ "SPN" SG_ 2563768062 EngnSpdLmtRqstMnmmCntns 1784;
BA_ "SPN" SG_ 2563768062 EngnSpdLmtRqstMxmmCntns 1785;
BA_ "SPN" SG_ 2563768062 EngnTrqLmtRqstMnmmCntns 1786;
BA_ "SPN" SG_ 2563768062 EngnTrqLmtRqstMxmmCntns 1787;
BA_ "SPN" SG_ 2563768062 MnmmCntnsRtrdrSpdLmtRqst 1788;
BA_ "SPN" SG_ 2563768062 MnmmCntnsRtrdrTrqLmtRqst 1790;
BA_ "SPN" SG_ 2563768062 MxmmCntnsRtrdrSpdLmtRqst 1789;
BA_ "SPN" SG_ 2563768062 MxmmCntnsRtrdrTrqLmtRqst 1791;
BA_ "SPN" SG_ 2563833598 IlluminationBrightnessPercent 1487;
BA_ "SPN" SG_ 2563833598 SwthBklghtIllmntnBrghtnssPrnt 5532;
BA_ "SPN" SG_ 2563833598 SwthIndtnIllmntnBrghtnssPrnt 6820;
BA_ "SPN" SG_ 2563833598 OprtrDsrdDsplMdCmmnd1 13079;
BA_ "SPN" SG_ 2563833598 OprtrDsrdDsplMdCmmnd2 13080;
BA_ "SPN" SG_ 2563833598 CabDomeLight1Command 23610;
BA_ "SPN" SG_ 2563833598 CabDomeLight2Command 23611;
BA_ "SPN" SG_ 2564161278 AdjustDay 1607;
BA_ "SPN" SG_ 2564161278 AdjustHours 1605;
BA_ "SPN" SG_ 2564161278 AdjustLocalHourOffset 1610;
BA_ "SPN" SG_ 2564161278 AdjustLocalMinuteOffset 1609;
BA_ "SPN" SG_ 2564161278 AdjustMinutes 1604;
BA_ "SPN" SG_ 2564161278 AdjustMonth 1606;
BA_ "SPN" SG_ 2564161278 AdjustSeconds 1603;
BA_ "SPN" SG_ 2564161278 AdjustYear 1608;
BA_ "SPN" SG_ 2564882174 AftrtrtmntRgnrtnFrSwth 3696;
BA_ "SPN" SG_ 2564882174 AftrtrtmntRgnrtnInhtSwth 3695;
BA_ "SPN" SG_ 2564882174 AtmtGrShftngEnlSwth 1666;
BA_ "SPN" SG_ 2564882174 AuxiliaryHeaterModeRequest 1683;
BA_ "SPN" SG_ 2564882174 AxlrHtrClntPmpRqst 1684;
BA_ "SPN" SG_ 2564882174 BatteryMainSwitchHoldRequest 1682;
BA_ "SPN" SG_ 2564882174 CabInteriorTemperatureCommand 1691;
BA_ "SPN" SG_ 2564882174 EngineFan1RequestedPercentSpeed 986;
BA_ "SPN" SG_ 2564882174 EngnAtmtStrtEnlSwth 1656;
BA_ "SPN" SG_ 2564882174 OperatorSeatDirectionSwitch 1714;
BA_ "SPN" SG_ 2564882174 ParkBrakeCommand 5630;
BA_ "SPN" SG_ 2564882174 RequestCabZoneHeating 1686;
BA_ "SPN" SG_ 2564882174 RequestEngineZoneHeating 1685;
BA_ "SPN" SG_ 2564882174 SeatBeltSwitch 1856;
BA_ "SPN" SG_ 2564882174 SltdMxmmVhlSpdLmt 2596;
BA_ "SPN" SG_ 2564882174 VhlLmtngSpdGvrnrDrmntSwth 1655;
BA_ "SPN" SG_ 2564882174 VhlLmtngSpdGvrnrEnlSwth 1653;
BA_ "SPN" SG_ 2564882174 VhlLmtngSpdGvrnrInrmntSwth 1654;
BA_ "SPN" SG_ 2565865982 AbsFullyOperational 1243;
BA_ "SPN" SG_ 2565865982 AbsOffRoadSwitch 575;
BA_ "SPN" SG_ 2565865982 AcceleratorInterlockSwitch 972;
BA_ "SPN" SG_ 2565865982 AntiLockBrakingAbsActive 563;
BA_ "SPN" SG_ 2565865982 AsrBrakeControlActive 562;
BA_ "SPN" SG_ 2565865982 AsrEngineControlActive 561;
BA_ "SPN" SG_ 2565865982 AsrHillHolderSwitch 577;
BA_ "SPN" SG_ 2565865982 AsrOffRoadSwitch 576;
BA_ "SPN" SG_ 2565865982 AtcAsrInformationSignal 1793;
BA_ "SPN" SG_ 2565865982 BrakePedalPosition 521;
BA_ "SPN" SG_ 2565865982 EbsBrakeSwitch 1121;
BA_ "SPN" SG_ 2565865982 EbsRedWarningSignal 1439;
BA_ "SPN" SG_ 2565865982 EngineAuxiliaryShutdownSwitch 970;
BA_ "SPN" SG_ 2565865982 EngineDerateSwitch 971;
BA_ "SPN" SG_ 2565865982 EngineRetarderSelection 973;
BA_ "SPN" SG_ 2565865982 HaltBrakeSwitch 2911;
BA_ "SPN" SG_ 2565865982 RailroadModeSwitch 7941;
BA_ "SPN" SG_ 2565865982 RemoteAcceleratorEnableSwitch 969;
BA_ "SPN" SG_ 2565865982 TractionControlOverrideSwitch 1238;
BA_ "SPN" SG_ 2565865982 TrailerAbsStatus 1836;
BA_ "SPN" SG_ 2565865982 AsEsAmrWrnngSgnlPwrdVhl 1438;
BA_ "SPN" SG_ 2565865982 SrAddrssOfCntrllngDvFrBrkCntrl 1481;
BA_ "SPN" SG_ 2565865982 TrtrMntdTrlrAsWrnngSgnl 1792;
BA_ "SPN" SG_ 2565867006 TransmissionActualGearRatio 526;
BA_ "SPN" SG_ 2565867006 TransmissionCurrentGear 523;
BA_ "SPN" SG_ 2565867006 TransmissionCurrentRange 163;
BA_ "SPN" SG_ 2565867006 TransmissionRequestedRange 162;
BA_ "SPN" SG_ 2565867006 TransmissionSelectedGear 524;
BA_ "SPN" SG_ 2565867262 DffrntlLkSttCntrlFrnt 565;
BA_ "SPN" SG_ 2565867262 DffrntlLkSttCntrlRr 566;
BA_ "SPN" SG_ 2565867262 DifferentialLockStateCentral 564;
BA_ "SPN" SG_ 2565867262 DifferentialLockStateFrontAxle1 567;
BA_ "SPN" SG_ 2565867262 DifferentialLockStateFrontAxle2 568;
BA_ "SPN" SG_ 2565867262 DifferentialLockStateRearAxle1 569;
BA_ "SPN" SG_ 2565867262 DifferentialLockStateRearAxle2 570;
BA_ "SPN" SG_ 2565867262 DifferentialLockStateRearAxle3 7716;
BA_ "SPN" SG_ 2565867262 FrontAxleGroupEngagementStatus 3819;
BA_ "SPN" SG_ 2565867262 Location 927;
BA_ "SPN" SG_ 2565867262 RearAxleGroupEngagementStatus 3820;
BA_ "SPN" SG_ 2565867262 DogClutchRearAxle2 12285;
BA_ "SPN" SG_ 2565867774 EngnHdrlPrssrGvrnrMdIndtr 1763;
BA_ "SPN" SG_ 2565867774 EngnHdrlPrssrGvrnrSwth 1764;
BA_ "SPN" SG_ 2565867774 FireApparatusPumpEngagement 2599;
BA_ "SPN" SG_ 2565867774 FrApprtsOkTPmpIntrlk 6702;
BA_ "SPN" SG_ 2565867774 HdrlDshrgPrssrStPnt 6708;
BA_ "SPN" SG_ 2565867774 HdrlPrssrGvrnrDrsSwth 6704;
BA_ "SPN" SG_ 2565867774 HdrlPrssrGvrnrIdlSwth 6705;
BA_ "SPN" SG_ 2565867774 HdrlPrssrGvrnrInrsSwth 6703;
BA_ "SPN" SG_ 2565867774 HdrlPrssrGvrnrPrstSwth 6706;
BA_ "SPN" SG_ 2565867774 HydraulicIntakePressure 6707;
BA_ "SPN" SG_ 2565867774 HydraulicPressure 1762;
BA_ "SPN" SG_ 2565868030 LateralAcceleration 1809;
BA_ "SPN" SG_ 2565868030 LongitudinalAcceleration 1810;
BA_ "SPN" SG_ 2565868030 SteeringWheelAngle 1807;
BA_ "SPN" SG_ 2565868030 SteeringWheelAngleSensorType 1812;
BA_ "SPN" SG_ 2565868030 SteeringWheelTurnCounter 1811;
BA_ "SPN" SG_ 2565868030 YawRate 1808;
BA_ "SPN" SG_ 2565868542 ActualInnerWheelSteeringAngle 2927;
BA_ "SPN" SG_ 2565868542 AxleLocation 2928;
BA_ "SPN" SG_ 2565868542 StatusOfSteeringAxle 2923;
BA_ "SPN" SG_ 2565868542 SteeringType 2924;
BA_ "SPN" SG_ 2565868542 StrlLftAxlLwrngInht 2922;
BA_ "SPN" SG_ 2565868542 TypeOfSteeringForces 2925;
BA_ "SPN" SG_ 2565868542 TypeOfSteeringTransmission 2926;
BA_ "SPN" SG_ 2565869310 EngineExhaust1Nox1 3216;
BA_ "SPN" SG_ 2565869310 EngineExhaust1Nox1ReadingStable 3220;
BA_ "SPN" SG_ 2565869310 EngineExhaust1PercentOxygen1 3217;
BA_ "SPN" SG_ 2565869310 EngnExhst1GsSnsr1PwrInRng 3218;
BA_ "SPN" SG_ 2565869310 EngnExhst1NxSnsr1PrlmnrFm 3224;
BA_ "SPN" SG_ 2565869310 EngnExhst1NxSnsr1SlfDgnssStts 5714;
BA_ "SPN" SG_ 2565869310 EngnExhst1GsSnsr1AtTmprtr 3219;
BA_ "SPN" SG_ 2565869310 EngnExhst1WdRngPrntOxgn1RdngStl 3221;
BA_ "SPN" SG_ 2565869310 EngnExhst1GsSnsr1HtrPrlmnrFm 3222;
BA_ "SPN" SG_ 2565869310 EngnExhst1GsSnsr1HtrCntrl 3223;
BA_ "SPN" SG_ 2565869310 EngnExhst1OxgnSnsr1PrlmnrFm 3225;
BA_ "SPN" SG_ 2565869566 Aftertreatment1OutletNox1 3226;
BA_ "SPN" SG_ 2565869566 Aftrtrtmnt1OtltGsSnsr1HtrCntrl 3233;
BA_ "SPN" SG_ 2565869566 Aftrtrtmnt1OtltGsSnsr1PwrInRng 3228;
BA_ "SPN" SG_ 2565869566 Aftrtrtmnt1OtltPrntOxgn1 3227;
BA_ "SPN" SG_ 2565869566 Atttt1OttWdRPtOx1RdSt 3231;
BA_ "SPN" SG_ 2565869566 Aftrtrtmnt1OtltGsSnsr1AtTmprtr 3229;
BA_ "SPN" SG_ 2565869566 Aftrtrtmnt1OtltNx1RdngStl 3230;
BA_ "SPN" SG_ 2565869566 Atttt1OttGsSs1HtPF 3232;
BA_ "SPN" SG_ 2565869566 Aftrtrtmnt1OtltNxSnsr1PrlmnrFm 3234;
BA_ "SPN" SG_ 2565869566 Atttt1OttNxSs1SDssStts 5713;
BA_ "SPN" SG_ 2565869566 Atttt1OttOxSs1PF 3235;
BA_ "SPN" SG_ 2565869822 EngineExhaust2Nox1 3255;
BA_ "SPN" SG_ 2565869822 EngineExhaust2Nox1ReadingStable 3259;
BA_ "SPN" SG_ 2565869822 EngineExhaust2PercentOxygen1 3256;
BA_ "SPN" SG_ 2565869822 EngnExhst2GsSnsr1PwrInRng 3257;
BA_ "SPN" SG_ 2565869822 EngnExhst2GsSnsr2PwrSppl 8485;
BA_ "SPN" SG_ 2565869822 EngnExhst2NxSnsr1PrlmnrFm 3263;
BA_ "SPN" SG_ 2565869822 EngnExhst2NxSnsr1SlfDgnssStts 5716;
BA_ "SPN" SG_ 2565869822 EngnExhst2GsSnsr1AtTmprtr 3258;
BA_ "SPN" SG_ 2565869822 EngnExhst2WdRngPrntOxgn1RdngStl 3260;
BA_ "SPN" SG_ 2565869822 EngnExhst2GsSnsr1HtrPrlmnrFm 3261;
BA_ "SPN" SG_ 2565869822 EngnExhst2GsSnsr1HtrCntrl 3262;
BA_ "SPN" SG_ 2565869822 EngnExhst2OxgnSnsr1PrlmnrFm 3264;
BA_ "SPN" SG_ 2565870078 Aftertreatment2OutletNox1 3265;
BA_ "SPN" SG_ 2565870078 Aftrtrtmnt2Otlt2GsSnsrPwrSppl 8486;
BA_ "SPN" SG_ 2565870078 Aftrtrtmnt2OtltGsSnsr1HtrCntrl 3272;
BA_ "SPN" SG_ 2565870078 Aftrtrtmnt2OtltGsSnsr1PwrInRng 3267;
BA_ "SPN" SG_ 2565870078 Aftrtrtmnt2OtltPrntOxgn1 3266;
BA_ "SPN" SG_ 2565870078 Atttt2OttWdRPtOx1RdSt 3270;
BA_ "SPN" SG_ 2565870078 Aftrtrtmnt2OtltGsSnsr1AtTmprtr 3268;
BA_ "SPN" SG_ 2565870078 Aftrtrtmnt2OtltNx1RdngStl 3269;
BA_ "SPN" SG_ 2565870078 Atttt2OttGsSs1HtPF 3271;
BA_ "SPN" SG_ 2565870078 Aftrtrtmnt2OtltNxSnsr1PrlmnrFm 3273;
BA_ "SPN" SG_ 2565870078 Atttt2OttNxSs1SDssStts 5715;
BA_ "SPN" SG_ 2565870078 Atttt2OttOxSs1PF 3274;
BA_ "SPN" SG_ 2565870334 FifthWheelDrawbarForce 3309;
BA_ "SPN" SG_ 2565870334 FifthWheelRollMoment 3310;
BA_ "SPN" SG_ 2565870334 FifthWheelRollWarningIndicator 3317;
BA_ "SPN" SG_ 2565870334 FifthWheelVerticalForce 3308;
BA_ "SPN" SG_ 2565873150 MessageChecksum 3690;
BA_ "SPN" SG_ 2565873150 MessageCounter 3689;
BA_ "SPN" SG_ 2565873150 SteeringAngleSensorActiveMode 3687;
BA_ "SPN" SG_ 2565873150 SteeringAngleSensorCalibrated 3688;
BA_ "SPN" SG_ 2565873150 SteeringWheelAngle 3683;
BA_ "SPN" SG_ 2565873150 SteeringWheelAngleRange 3686;
BA_ "SPN" SG_ 2565873150 SteeringWheelAngleRangeCounter 3684;
BA_ "SPN" SG_ 2565873150 StrngWhlAnglRngCntrTp 3685;
BA_ "SPN" SG_ 2565874174 EngineSpeed1 4201;
BA_ "SPN" SG_ 2565874174 EngineSpeed2 723;
BA_ "SPN" SG_ 2565874174 EngineSpeed3 4202;
BA_ "SPN" SG_ 2565874174 EngnSpdSnsr1TmngPttrnStts 4203;
BA_ "SPN" SG_ 2565874174 EngnSpdSnsr2TmngPttrnStts 4204;
BA_ "SPN" SG_ 2565874174 EngnSpdSnsr3TmngPttrnStts 4205;
BA_ "SPN" SG_ 2565877502 EExstB1PssRtCtCd 649;
BA_ "SPN" SG_ 2565877502 EngnTrhrgrWstgtAttr1Cmmnd 5386;
BA_ "SPN" SG_ 2565877502 EngnTrhrgrWstgtAttr2Cmmnd 5387;
BA_ "SPN" SG_ 2565877502 ETCpssBwAtt1Cd 6201;
BA_ "SPN" SG_ 2565917438 DAAssrInvrtr1PwrLmtdDTDSdCrrnt 9211;
BA_ "SPN" SG_ 2565917438 DAAssIvt1PwLtdDTASdRsCt 9212;
BA_ "SPN" SG_ 2565917438 DAAssIvt1PwLtdDTDSdVtM 9213;
BA_ "SPN" SG_ 2565917438 DAAssrInvrtr1FrqnCmmndBlwMnmm 9214;
BA_ "SPN" SG_ 2565917438 DAAssrInvrtr1FrqnCmmndExdsMxmm 9215;
BA_ "SPN" SG_ 2565917438 DAAssIvt1PwLtdDTCtTpt 9216;
BA_ "SPN" SG_ 2565917438 DAAssIvt1PwLtdDTEtFtTpt 9217;
BA_ "SPN" SG_ 2565917438 DAAssIvt1PwLtdDTPwEtsTpt 9218;
BA_ "SPN" SG_ 2565917438 DAAssIvt1PwLtdDTRtOCLt 9219;
BA_ "SPN" SG_ 2565917438 DAAssrInvrtr1PwrLmtdDTUndfndRsn 9220;
BA_ "SPN" SG_ 2565918206 DAAssrInvrtr2PwrLmtdDTDSdCrrnt 9241;
BA_ "SPN" SG_ 2565918206 DAAssIvt2PwLtdDTASdRsCt 9242;
BA_ "SPN" SG_ 2565918206 DAAssIvt2PwLtdDTDSdVtM 9243;
BA_ "SPN" SG_ 2565918206 DAAssrInvrtr2FrqnCmmndBlwMnmm 9244;
BA_ "SPN" SG_ 2565918206 DAAssrInvrtr2FrqnCmmndExdsMxmm 9245;
BA_ "SPN" SG_ 2565918206 DAAssIvt2PwLtdDTCtTpt 9246;
BA_ "SPN" SG_ 2565918206 DAAssIvt2PwLtdDTEtFtTpt 9247;
BA_ "SPN" SG_ 2565918206 DAAssIvt2PwLtdDTPwEtsTpt 9248;
BA_ "SPN" SG_ 2565918206 DAAssIvt2PwLtdDTRtOCLt 9249;
BA_ "SPN" SG_ 2565918206 DAAssrInvrtr2PwrLmtdDTUndfndRsn 9250;
BA_ "SPN" SG_ 2565920510 DAAssrInvrtr1DvMxmmFrqn 8328;
BA_ "SPN" SG_ 2565920510 DAAssrInvrtr1DvMnmmFrqn 8329;
BA_ "SPN" SG_ 2565920510 DAAssrInvrtr1DvRtdFrqn 8330;
BA_ "SPN" SG_ 2565920510 DAAssrInvrtr1DvRtdRmsVltg 8331;
BA_ "SPN" SG_ 2565920510 DAAssrInvrtr1DvFrqnRtOfChngLmt 8332;
BA_ "SPN" SG_ 2565920510 DAAssrInvrtr1FrqnCmmnd 8333;
BA_ "SPN" SG_ 2565920510 DAAssrInvrtr1Dv1Stts 8334;
BA_ "SPN" SG_ 2565920510 DAAssrInvrtr1Dv2Stts 8335;
BA_ "SPN" SG_ 2565920510 DAAssrInvrtr1OprtnlCmmnd 8336;
BA_ "SPN" SG_ 2565920510 DAAssIvt1ASdMtSttRsVtRqst 9528;
BA_ "SPN" SG_ 2565920766 DcAcAccessoryInverter1Frequency 8337;
BA_ "SPN" SG_ 2565920766 DAAssrInvrtr1ASdRmsVltg 8338;
BA_ "SPN" SG_ 2565920766 DAAssrInvrtr1ASdPwr 8339;
BA_ "SPN" SG_ 2565920766 DAAssrInvrtr1ASdRmsCrrnt 9200;
BA_ "SPN" SG_ 2565920766 DAAssrInvrtr1OprtnlStts 8340;
BA_ "SPN" SG_ 2565920766 DAAssrInvrtr1LdshdRqst 8341;
BA_ "SPN" SG_ 2565920766 DAAssrInvrtr1HvlStts 8851;
BA_ "SPN" SG_ 2565921534 DAAssrInvrtr2DvMxmmFrqn 8342;
BA_ "SPN" SG_ 2565921534 DAAssrInvrtr2DvMnmmFrqn 8343;
BA_ "SPN" SG_ 2565921534 DAAssrInvrtr2DvRtdFrqn 8344;
BA_ "SPN" SG_ 2565921534 DAAssrInvrtr2DvRtdRmsVltg 8345;
BA_ "SPN" SG_ 2565921534 DAAssrInvrtr2DvFrqnRtOfChngLmt 8346;
BA_ "SPN" SG_ 2565921534 DAAssrInvrtr2FrqnCmmnd 8347;
BA_ "SPN" SG_ 2565921534 DAAssrInvrtr2Dv1Stts 8348;
BA_ "SPN" SG_ 2565921534 DAAssrInvrtr2Dv2Stts 8349;
BA_ "SPN" SG_ 2565921534 DAAssrInvrtr2OprtnlCmmnd 8350;
BA_ "SPN" SG_ 2565921534 DAAssIvt2ASdMtSttRsVtRqst 9534;
BA_ "SPN" SG_ 2565921790 DcAcAccessoryInverter2Frequency 8351;
BA_ "SPN" SG_ 2565921790 DAAssrInvrtr2ASdRmsVltg 8352;
BA_ "SPN" SG_ 2565921790 DAAssrInvrtr2ASdPwr 8353;
BA_ "SPN" SG_ 2565921790 DAAssrInvrtr2ASdRmsCrrnt 9201;
BA_ "SPN" SG_ 2565921790 DAAssrInvrtr2OprtnlStts 8354;
BA_ "SPN" SG_ 2565921790 DAAssrInvrtr2LdshdRqst 8355;
BA_ "SPN" SG_ 2565921790 DAAssrInvrtr2HvlStts 8852;
BA_ "SPN" SG_ 2565922558 DAAssrInvrtr3DvMxmmFrqn 8356;
BA_ "SPN" SG_ 2565922558 DAAssrInvrtr3DvMnmmFrqn 8357;
BA_ "SPN" SG_ 2565922558 DAAssrInvrtr3DvRtdFrqn 8358;
BA_ "SPN" SG_ 2565922558 DAAssrInvrtr3DvRtdRmsVltg 8359;
BA_ "SPN" SG_ 2565922558 DAAssrInvrtr3DvFrqnRtOfChngLmt 8360;
BA_ "SPN" SG_ 2565922558 DAAssrInvrtr3FrqnCmmnd 8361;
BA_ "SPN" SG_ 2565922558 DAAssrInvrtr3Dv1Stts 8362;
BA_ "SPN" SG_ 2565922558 DAAssrInvrtr3Dv2Stts 8363;
BA_ "SPN" SG_ 2565922558 DAAssrInvrtr3OprtnlCmmnd 8364;
BA_ "SPN" SG_ 2565922558 DAAssIvt3ASdMtSttRsVtRqst 9540;
BA_ "SPN" SG_ 2565922814 DcAcAccessoryInverter3Frequency 8365;
BA_ "SPN" SG_ 2565922814 DAAssrInvrtr3ASdRmsVltg 8366;
BA_ "SPN" SG_ 2565922814 DAAssrInvrtr3ASdPwr 8367;
BA_ "SPN" SG_ 2565922814 DAAssrInvrtr3ASdRmsCrrnt 9202;
BA_ "SPN" SG_ 2565922814 DAAssrInvrtr3OprtnlStts 8368;
BA_ "SPN" SG_ 2565922814 DAAssrInvrtr3LdshdRqst 8369;
BA_ "SPN" SG_ 2565922814 DAAssrInvrtr3HvlStts 8853;
BA_ "SPN" SG_ 2565923582 DAAssrInvrtr4DvMxmmFrqn 8370;
BA_ "SPN" SG_ 2565923582 DAAssrInvrtr4DvMnmmFrqn 8371;
BA_ "SPN" SG_ 2565923582 DAAssrInvrtr4DvRtdFrqn 8372;
BA_ "SPN" SG_ 2565923582 DAAssrInvrtr4DvRtdRmsVltg 8373;
BA_ "SPN" SG_ 2565923582 DAAssrInvrtr4DvFrqnRtOfChngLmt 8374;
BA_ "SPN" SG_ 2565923582 DAAssrInvrtr4FrqnCmmnd 8375;
BA_ "SPN" SG_ 2565923582 DAAssrInvrtr4Dv1Stts 8376;
BA_ "SPN" SG_ 2565923582 DAAssrInvrtr4Dv2Stts 8377;
BA_ "SPN" SG_ 2565923582 DAAssrInvrtr4OprtnlCmmnd 8378;
BA_ "SPN" SG_ 2565923582 DAAssIvt4ASdMtSttRsVtRqst 9546;
BA_ "SPN" SG_ 2565923838 DcAcAccessoryInverter4Frequency 8379;
BA_ "SPN" SG_ 2565923838 DAAssrInvrtr4ASdRmsVltg 8380;
BA_ "SPN" SG_ 2565923838 DAAssrInvrtr4ASdPwr 8381;
BA_ "SPN" SG_ 2565923838 DAAssrInvrtr4ASdRmsCrrnt 9203;
BA_ "SPN" SG_ 2565923838 DAAssrInvrtr4OprtnlStts 8382;
BA_ "SPN" SG_ 2565923838 DAAssrInvrtr4LdshdRqst 8383;
BA_ "SPN" SG_ 2565923838 DAAssrInvrtr4HvlStts 8854;
BA_ "SPN" SG_ 2565925374 EngineExhaust1Nox2 7649;
BA_ "SPN" SG_ 2565925374 EngineExhaust1Nox2ReadingStable 7653;
BA_ "SPN" SG_ 2565925374 EngnExhst1NxSnsr2PrlmnrFm 7657;
BA_ "SPN" SG_ 2565925374 EngnExhst1NxSnsr2SlfDgnssStts 7658;
BA_ "SPN" SG_ 2565925374 EngineExhaust1PercentOxygen2 7650;
BA_ "SPN" SG_ 2565925374 EngnExhst1GsSnsr2PwrInRng 7651;
BA_ "SPN" SG_ 2565925374 EngnExhst1GsSnsr2AtTmprtr 7652;
BA_ "SPN" SG_ 2565925374 EngnExhst1WdRngPrntOxgn2RdngStl 7654;
BA_ "SPN" SG_ 2565925374 EngnExhst1GsSnsr2HtrPrlmnrFm 7655;
BA_ "SPN" SG_ 2565925374 EngnExhst1GsSnsr2HtrCntrl 7656;
BA_ "SPN" SG_ 2565925374 EngnExhst1OxgnSnsr2PrlmnrFm 7659;
BA_ "SPN" SG_ 2565925630 Aftertreatment1OutletNox2 7660;
BA_ "SPN" SG_ 2565925630 Aftrtrtmnt1OtltGsSnsr2HtrCntrl 7667;
BA_ "SPN" SG_ 2565925630 Aftrtrtmnt1OtltGsSnsr2PwrInRng 7662;
BA_ "SPN" SG_ 2565925630 Aftrtrtmnt1OtltPrntOxgn2 7661;
BA_ "SPN" SG_ 2565925630 Atttt1OttWdRPtOx2RdSt 7665;
BA_ "SPN" SG_ 2565925630 Aftrtrtmnt1OtltGsSnsr2AtTmprtr 7663;
BA_ "SPN" SG_ 2565925630 Aftrtrtmnt1OtltNx2RdngStl 7664;
BA_ "SPN" SG_ 2565925630 Atttt1OttGsSs2HtPF 7666;
BA_ "SPN" SG_ 2565925630 Aftrtrtmnt1OtltNxSnsr2PrlmnrFm 7668;
BA_ "SPN" SG_ 2565925630 Atttt1OttNxSs2SDssStts 7669;
BA_ "SPN" SG_ 2565925630 Atttt1OttOxSs2PF 7670;
BA_ "SPN" SG_ 2565925886 EngineExhaust2Nox2 7671;
BA_ "SPN" SG_ 2565925886 EngineExhaust2Nox2ReadingStable 7675;
BA_ "SPN" SG_ 2565925886 EngnExhst2NxSnsr2PrlmnrFm 7679;
BA_ "SPN" SG_ 2565925886 EngnExhst2NxSnsr2SlfDgnssStts 7680;
BA_ "SPN" SG_ 2565925886 EngineExhaust2PercentOxygen2 7672;
BA_ "SPN" SG_ 2565925886 EngnExhst2GsSnsr2PwrInRng 7673;
BA_ "SPN" SG_ 2565925886 EngnExhst2GsSnsr2AtTmprtr 7674;
BA_ "SPN" SG_ 2565925886 EngnExhst2WdRngPrntOxgn2RdngStl 7676;
BA_ "SPN" SG_ 2565925886 EngnExhst2GsSnsr2HtrPrlmnrFm 7677;
BA_ "SPN" SG_ 2565925886 EngnExhst2GsSnsr2HtrCntrl 7678;
BA_ "SPN" SG_ 2565925886 EngnExhst2OxgnSnsr2PrlmnrFm 7681;
BA_ "SPN" SG_ 2565926142 Aftertreatment2OutletNox2 7682;
BA_ "SPN" SG_ 2565926142 Aftrtrtmnt2OtltGsSnsr2HtrCntrl 7689;
BA_ "SPN" SG_ 2565926142 Aftrtrtmnt2OtltGsSnsr2PwrInRng 7684;
BA_ "SPN" SG_ 2565926142 Aftrtrtmnt2OtltPrntOxgn2 7683;
BA_ "SPN" SG_ 2565926142 Atttt2OttWdRPtOx2RdSt 7687;
BA_ "SPN" SG_ 2565926142 Aftrtrtmnt2OtltGsSnsr2AtTmprtr 7685;
BA_ "SPN" SG_ 2565926142 Aftrtrtmnt2OtltNx2RdngStl 7686;
BA_ "SPN" SG_ 2565926142 Atttt2OttGsSs2HtPF 7688;
BA_ "SPN" SG_ 2565926142 Aftrtrtmnt2OtltNxSnsr2PrlmnrFm 7690;
BA_ "SPN" SG_ 2565926142 Atttt2OttNxSs2SDssStts 7691;
BA_ "SPN" SG_ 2565926142 Atttt2OttOxSs2PF 7692;
BA_ "SPN" SG_ 2565932286 EngineSpeed4 7846;
BA_ "SPN" SG_ 2565932798 WllStmltnPmpDshrgPrssr 8155;
BA_ "SPN" SG_ 2565932798 WllStmltnPmpStnPrssr 8154;
BA_ "SPN" SG_ 2565933054 WellStimulationPumpSpeed 8158;
BA_ "SPN" SG_ 2565933054 WllStmltnPmpGrBxOlPrssr 8156;
BA_ "SPN" SG_ 2565933054 WllStmltnPmpGrBxOlTmprtr 8157;
BA_ "SPN" SG_ 2565933054 WllStmltnPmpGrBxOtltOlTmprtr 12812;
BA_ "SPN" SG_ 2565934590 EngnFlVlv2DffrntlPrssr 6885;
BA_ "SPN" SG_ 2565942014 DAAssrInvrtr3PwrLmtdDTDSdCrrnt 9271;
BA_ "SPN" SG_ 2565942014 DAAssIvt3PwLtdDTASdRsCt 9272;
BA_ "SPN" SG_ 2565942014 DAAssIvt3PwLtdDTDSdVtM 9273;
BA_ "SPN" SG_ 2565942014 DAAssrInvrtr3FrqnCmmndBlwMnmm 9274;
BA_ "SPN" SG_ 2565942014 DAAssrInvrtr3FrqnCmmndExdsMxmm 9275;
BA_ "SPN" SG_ 2565942014 DAAssIvt3PwLtdDTCtTpt 9276;
BA_ "SPN" SG_ 2565942014 DAAssIvt3PwLtdDTEtFtTpt 9277;
BA_ "SPN" SG_ 2565942014 DAAssIvt3PwLtdDTPwEtsTpt 9278;
BA_ "SPN" SG_ 2565942014 DAAssIvt3PwLtdDTRtOCLt 9279;
BA_ "SPN" SG_ 2565942014 DAAssrInvrtr3PwrLmtdDTUndfndRsn 9280;
BA_ "SPN" SG_ 2565942782 DAAssrInvrtr4PwrLmtdDTDSdCrrnt 9301;
BA_ "SPN" SG_ 2565942782 DAAssIvt4PwLtdDTASdRsCt 9302;
BA_ "SPN" SG_ 2565942782 DAAssIvt4PwLtdDTDSdVtM 9303;
BA_ "SPN" SG_ 2565942782 DAAssrInvrtr4FrqnCmmndBlwMnmm 9304;
BA_ "SPN" SG_ 2565942782 DAAssrInvrtr4FrqnCmmndExdsMxmm 9305;
BA_ "SPN" SG_ 2565942782 DAAssIvt4PwLtdDTCtTpt 9306;
BA_ "SPN" SG_ 2565942782 DAAssIvt4PwLtdDTEtFtTpt 9307;
BA_ "SPN" SG_ 2565942782 DAAssIvt4PwLtdDTPwEtsTpt 9308;
BA_ "SPN" SG_ 2565942782 DAAssIvt4PwLtdDTRtOCLt 9309;
BA_ "SPN" SG_ 2565942782 DAAssrInvrtr4PwrLmtdDTUndfndRsn 9310;
BA_ "SPN" SG_ 2565943038 DAAssrInvrtr5DvMxmmFrqn 9321;
BA_ "SPN" SG_ 2565943038 DAAssrInvrtr5DvMnmmFrqn 9322;
BA_ "SPN" SG_ 2565943038 DAAssrInvrtr5DvRtdFrqn 9323;
BA_ "SPN" SG_ 2565943038 DAAssrInvrtr5DvRtdRmsVltg 9324;
BA_ "SPN" SG_ 2565943038 DAAssrInvrtr5DvFrqnRtOfChngLmt 9325;
BA_ "SPN" SG_ 2565943038 DAAssrInvrtr5FrqnCmmnd 9326;
BA_ "SPN" SG_ 2565943038 DAAssrInvrtr5Dv1Stts 9327;
BA_ "SPN" SG_ 2565943038 DAAssrInvrtr5Dv2Stts 9328;
BA_ "SPN" SG_ 2565943038 DAAssrInvrtr5OprtnlCmmnd 9329;
BA_ "SPN" SG_ 2565943038 DAAssIvt5ASdMtSttRsVtRqst 9552;
BA_ "SPN" SG_ 2565943294 DcAcAccessoryInverter5Frequency 9330;
BA_ "SPN" SG_ 2565943294 DAAssrInvrtr5ASdRmsVltg 9331;
BA_ "SPN" SG_ 2565943294 DAAssrInvrtr5ASdPwr 9332;
BA_ "SPN" SG_ 2565943294 DAAssrInvrtr5ASdRmsCrrnt 9333;
BA_ "SPN" SG_ 2565943294 DAAssrInvrtr5OprtnlStts 9334;
BA_ "SPN" SG_ 2565943294 DAAssrInvrtr5LdshdRqst 9335;
BA_ "SPN" SG_ 2565943294 DAAssrInvrtr5HvlStts 9336;
BA_ "SPN" SG_ 2565944062 DAAssrInvrtr5PwrLmtdDTDSdCrrnt 9347;
BA_ "SPN" SG_ 2565944062 DAAssIvt5PwLtdDTASdRsCt 9348;
BA_ "SPN" SG_ 2565944062 DAAssIvt5PwLtdDTDSdVtM 9349;
BA_ "SPN" SG_ 2565944062 DAAssrInvrtr5FrqnCmmndBlwMnmm 9350;
BA_ "SPN" SG_ 2565944062 DAAssrInvrtr5FrqnCmmndExdsMxmm 9351;
BA_ "SPN" SG_ 2565944062 DAAssIvt5PwLtdDTCtTpt 9352;
BA_ "SPN" SG_ 2565944062 DAAssIvt5PwLtdDTEtFtTpt 9353;
BA_ "SPN" SG_ 2565944062 DAAssIvt5PwLtdDTPwEtsTpt 9354;
BA_ "SPN" SG_ 2565944062 DAAssIvt5PwLtdDTRtOCLt 9355;
BA_ "SPN" SG_ 2565944062 DAAssrInvrtr5PwrLmtdDTUndfndRsn 9356;
BA_ "SPN" SG_ 2566624510 EngnExhstGsRrltn1ClrIntkPrssr 9379;
BA_ "SPN" SG_ 2566624510 TtlNmrOfCrnkAttmptsDrngEngnLf 22623;
BA_ "SPN" SG_ 2566624766 EngnIdlMngmntAtvTtlTm 9377;
BA_ "SPN" SG_ 2566625022 InstntnsEstmtdEngnPwrRtLmt 9375;
BA_ "SPN" SG_ 2566625022 EngineExhaustBank1Pressure2 11798;
BA_ "SPN" SG_ 2566625022 EngineDifferentialPressure 23975;
BA_ "SPN" SG_ 2566625278 SlBttrPk1Bttr1CptSttng 9368;
BA_ "SPN" SG_ 2566625278 SlBttrPk1Bttr2CptSttng 9369;
BA_ "SPN" SG_ 2566625278 SlBttrPk1Bttr3CptSttng 9370;
BA_ "SPN" SG_ 2566625278 SlBttrPk1Bttr4CptSttng 9371;
BA_ "SPN" SG_ 2566625790 DAAssrInvrtr1CntrllrTmprtr 9204;
BA_ "SPN" SG_ 2566625790 DAAssIvt1IvtEtFtTpt 9205;
BA_ "SPN" SG_ 2566625790 DAAssrInvrtr1PwrEltrnsTmprtr 9206;
BA_ "SPN" SG_ 2566625790 DAAssrInvrtr1ClntInTmprtr 9207;
BA_ "SPN" SG_ 2566625790 DAAssrInvrtr1ClntOtTmprtr 9208;
BA_ "SPN" SG_ 2566626558 DAAssIvt1DSdVtMLtStt 9225;
BA_ "SPN" SG_ 2566626558 DAAssIvt1DSdCtMxLtStt 9226;
BA_ "SPN" SG_ 2566626558 DAAssIvt1ASdRsVtMxLtStt 9227;
BA_ "SPN" SG_ 2566626558 DAAssIvt1ASdRsCtMxLtStt 9228;
BA_ "SPN" SG_ 2566626558 DAAssIvt1DSdVtMxLtStt 9531;
BA_ "SPN" SG_ 2566626558 DAAssIvt1DSdCtMLtStt 9532;
BA_ "SPN" SG_ 2566626558 DAAssIvt1ASdDtFqCdStt 9533;
BA_ "SPN" SG_ 2566626814 DAAssrInvrtr1TtlDInptChrg 9229;
BA_ "SPN" SG_ 2566626814 DAAssrInvrtr1TtlDInptEnrg 9230;
BA_ "SPN" SG_ 2566627070 DAAssrInvrtr2CntrllrTmprtr 9231;
BA_ "SPN" SG_ 2566627070 DAAssIvt2IvtEtFtTpt 9232;
BA_ "SPN" SG_ 2566627070 DAAssrInvrtr2PwrEltrnsTmprtr 9233;
BA_ "SPN" SG_ 2566627070 DAAssrInvrtr2ClntInTmprtr 9234;
BA_ "SPN" SG_ 2566627070 DAAssrInvrtr2ClntOtTmprtr 9235;
BA_ "SPN" SG_ 2566627838 DAAssIvt2DSdVtMLtStt 9255;
BA_ "SPN" SG_ 2566627838 DAAssIvt2DSdCtMxLtStt 9256;
BA_ "SPN" SG_ 2566627838 DAAssIvt2ASdRsVtMxLtStt 9257;
BA_ "SPN" SG_ 2566627838 DAAssIvt2ASdRsCtMxLtStt 9258;
BA_ "SPN" SG_ 2566627838 DAAssIvt2DSdVtMxLtStt 9537;
BA_ "SPN" SG_ 2566627838 DAAssIvt2DSdCtMLtStt 9538;
BA_ "SPN" SG_ 2566627838 DAAssIvt2ASdDtFqCdStt 9539;
BA_ "SPN" SG_ 2566628094 DAAssrInvrtr2TtlDInptChrg 9259;
BA_ "SPN" SG_ 2566628094 DAAssrInvrtr2TtlDInptEnrg 9260;
BA_ "SPN" SG_ 2566628350 DAAssrInvrtr3CntrllrTmprtr 9261;
BA_ "SPN" SG_ 2566628350 DAAssIvt3IvtEtFtTpt 9262;
BA_ "SPN" SG_ 2566628350 DAAssrInvrtr3PwrEltrnsTmprtr 9263;
BA_ "SPN" SG_ 2566628350 DAAssrInvrtr3ClntInTmprtr 9264;
BA_ "SPN" SG_ 2566628350 DAAssrInvrtr3ClntOtTmprtr 9265;
